VERSION "HNNBNNNYNNNNNNNNNNNNNNNNNNNNNNNNNNNNNNNNNN/4/%%%/4/'%**4NNN///"

NS_ :

BS_:

BU_: Airbag Allrad_Haldex BAP_Tester DCC_Gen3 EBKV_MQBW ESC_MQBW Gateway_Max Lenkhilfe_REPS

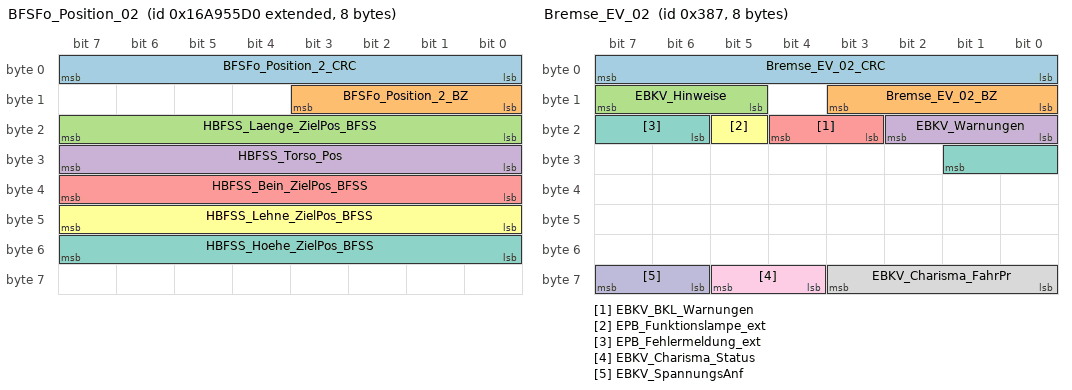
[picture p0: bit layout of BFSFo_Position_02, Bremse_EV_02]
BO_ 2527679952 BFSFo_Position_02: 8 Gateway_Max
 SG_ BFSFo_Position_2_CRC : 0|8@1+ (1,0) [0|255] ""  Airbag
 SG_ BFSFo_Position_2_BZ : 8|4@1+ (1,0) [0|15] ""  Airbag
 SG_ HBFSS_Laenge_ZielPos_BFSS : 16|8@1+ (1,0) [0|255] ""  Vector__XXX
 SG_ HBFSS_Torso_Pos : 24|8@1+ (1,0) [0|255] ""  Airbag
 SG_ HBFSS_Bein_ZielPos_BFSS : 32|8@1+ (1,0) [0|255] ""  Vector__XXX
 SG_ HBFSS_Lehne_ZielPos_BFSS : 40|8@1+ (1,0) [0|255] ""  Vector__XXX
 SG_ HBFSS_Hoehe_ZielPos_BFSS : 48|8@1+ (1,0) [0|255] ""  Vector__XXX

BO_ 870 Blinkmodi_02: 8 Gateway_Max
 SG_ Blinkmodi_02_CRC : 0|8@1+ (1,0) [0|255] ""  Vector__XXX
 SG_ Blinkmodi_02_BZ : 8|4@1+ (1,0) [0|15] ""  Vector__XXX
 SG_ BM_ZV_auf : 12|1@1+ (1.0,0.0) [0.0|1] ""  Vector__XXX
 SG_ BM_ZV_zu : 13|1@1+ (1.0,0.0) [0.0|1] ""  Vector__XXX
 SG_ BM_DWA_ein : 14|1@1+ (1.0,0.0) [0.0|1] ""  Vector__XXX
 SG_ BM_DWA_Alarm : 15|1@1+ (1.0,0.0) [0.0|1] ""  Vector__XXX
 SG_ BM_Crash : 16|1@1+ (1.0,0.0) [0.0|1] ""  Vector__XXX
 SG_ BM_Panik : 17|1@1+ (1.0,0.0) [0.0|1] ""  Vector__XXX
 SG_ BM_Not_Bremsung : 18|1@1+ (1.0,0.0) [0.0|1] ""  Vector__XXX
 SG_ BM_GDO : 19|1@1+ (1.0,0.0) [0.0|1] ""  Vector__XXX
 SG_ BM_Warnblinken : 20|1@1+ (1.0,0.0) [0.0|1] ""  Airbag,ESC_MQBW
 SG_ BM_Taxi_Notalarm : 21|1@1+ (1.0,0.0) [0.0|1] ""  Vector__XXX
 SG_ BM_Telematik : 22|1@1+ (1.0,0.0) [0.0|1] ""  Vector__XXX
 SG_ BM_links : 23|1@1+ (1.0,0.0) [0.0|1] ""  Airbag
 SG_ BM_rechts : 24|1@1+ (1.0,0.0) [0.0|1] ""  Airbag
 SG_ Blinken_li_Fzg_Takt : 25|1@1+ (1.0,0.0) [0.0|1] ""  Vector__XXX
 SG_ Blinken_re_Fzg_Takt : 26|1@1+ (1.0,0.0) [0.0|1] ""  Vector__XXX
 SG_ Blinken_li_Kombi_Takt : 27|1@1+ (1.0,0.0) [0.0|1] ""  Vector__XXX
 SG_ Blinken_re_Kombi_Takt : 28|1@1+ (1.0,0.0) [0.0|1] ""  Vector__XXX
 SG_ BM_NBA_n_codiert_n_aktiv : 29|1@1+ (1.0,0.0) [0.0|1] ""  Vector__XXX
 SG_ BM_NBA_Status : 30|2@1+ (1.0,0.0) [0.0|3] ""  Vector__XXX
 SG_ BM_WBT_Beleuchtung : 32|1@1+ (1.0,0.0) [0.0|1] ""  Vector__XXX
 SG_ BM_HD_Oeffnung_angelernt : 33|1@1+ (1.0,0.0) [0.0|1] ""  Vector__XXX
 SG_ BM_Autobahn : 34|1@1+ (1.0,0.0) [0.0|1] ""  Vector__XXX
 SG_ BM_Rollenmodus_Blinken : 35|1@1+ (1.0,0.0) [0.0|1] ""  Vector__XXX
 SG_ BM_Recas : 36|1@1+ (1.0,0.0) [0.0|1] ""  Vector__XXX
 SG_ BM_Wischblinken : 37|1@1+ (1.0,0.0) [0.0|1] ""  Vector__XXX
 SG_ BM_Telematik_Abbruchgrund : 38|6@1+ (1.0,0.0) [0.0|63] ""  Vector__XXX
 SG_ BM_PiloPa : 44|1@1+ (1.0,0.0) [0.0|1] ""  Vector__XXX
 SG_ SAL_TA_Blinken_Status : 45|3@1+ (1.0,0.0) [0.0|7] ""  Vector__XXX
 SG_ BM_WBA_Warnblinken : 48|1@1+ (1.0,0.0) [0.0|1] ""  Vector__XXX
 SG_ SAL_RHP_Blinken_Status : 49|3@1+ (1.0,0.0) [0.0|7] ""  Vector__XXX
 SG_ SAL_RHP_Warnblinken : 52|1@1+ (1.0,0.0) [0.0|1] ""  Vector__XXX

BO_ 903 Bremse_EV_02: 8 EBKV_MQBW
 SG_ Bremse_EV_02_CRC : 0|8@1+ (1,0) [0|255] ""  Vector__XXX
 SG_ Bremse_EV_02_BZ : 8|4@1+ (1,0) [0|15] ""  Vector__XXX
 SG_ EBKV_Hinweise : 13|3@1+ (1.0,0.0) [0.0|7] ""  Vector__XXX
 SG_ EBKV_Warnungen : 16|3@1+ (1.0,0.0) [0.0|7] ""  Vector__XXX
 SG_ EBKV_BKL_Warnungen : 19|2@1+ (1.0,0.0) [0.0|3] ""  Vector__XXX
 SG_ EPB_Funktionslampe_ext : 21|1@1+ (1.0,0.0) [0.0|1] ""  Vector__XXX
 SG_ EPB_Fehlermeldung_ext : 22|4@1+ (1.0,0.0) [0.0|15] ""  Vector__XXX
 SG_ EBKV_Charisma_FahrPr : 56|4@1+ (1.0,0.0) [0.0|15] ""  Vector__XXX
 SG_ EBKV_Charisma_Status : 60|2@1+ (1.0,0.0) [0.0|3] ""  Vector__XXX
 SG_ EBKV_SpannungsAnf : 62|2@1+ (1.0,0.0) [0.0|3] ""  Gateway_Max

BO_ 2281471488 CCP_Allrad_CRO_01: 8 Vector__XXX
 SG_ CCP_Allrad_CRO_01_Data : 0|64@1+ (1.0,0.0) [0.0|18446744073709551615] ""  Allrad_Haldex

BO_ 2281471489 CCP_Allrad_DTO_01: 8 Allrad_Haldex
 SG_ CCP_Allrad_DTO_01_Data : 0|64@1+ (1.0,0.0) [0.0|18446744073709551615] ""  Vector__XXX

BO_ 2463978646 Charisma_11: 24 Gateway_Max
 SG_ CHA_Ziel_FahrPr_AGA : 0|4@1+ (1.0,0.0) [0.0|15] ""  Vector__XXX
 SG_ CHA_Ziel_FahrPr_ESP : 4|4@1+ (1.0,0.0) [0.0|15] ""  ESC_MQBW
 SG_ CHA_Ziel_FahrPr_Freilauf : 8|4@1+ (1.0,0.0) [0.0|15] ""  Vector__XXX
 SG_ CHA_Fahrer_Umschaltung : 14|1@1+ (1.0,0.0) [0.0|1] ""  Airbag,ESC_MQBW
 SG_ CHA_Fahrer_Umschaltung_BMA : 15|1@1+ (1.0,0.0) [0.0|1] ""  Vector__XXX
 SG_ CHA_Ziel_FahrPr_MO : 16|4@1+ (1.0,0.0) [0.0|15] ""  Vector__XXX
 SG_ CHA_Ziel_FahrPr_GE : 20|4@1+ (1.0,0.0) [0.0|15] ""  Vector__XXX
 SG_ CHA_Ziel_FahrPr_ALR : 24|4@1+ (1.0,0.0) [0.0|15] ""  Allrad_Haldex
 SG_ CHA_Ziel_FahrPr_MO_BZS : 28|4@1+ (1.0,0.0) [0.0|15] ""  Vector__XXX
 SG_ CHA_Ziel_FahrPr_DR : 32|4@1+ (1.0,0.0) [0.0|15] ""  DCC_Gen3,ESC_MQBW
 SG_ CHA_Ziel_FahrPr_VAQ : 36|4@1+ (1.0,0.0) [0.0|15] ""  ESC_MQBW
 SG_ CHA_Ziel_FahrPr_AFS : 40|4@1+ (1.0,0.0) [0.0|15] ""  Vector__XXX
 SG_ CHA_Ziel_FahrPr_PreCrash : 44|4@1+ (1.0,0.0) [0.0|15] ""  Airbag
 SG_ CHA_Ziel_FahrPr_EPS : 48|4@1+ (1.0,0.0) [0.0|15] ""  Lenkhilfe_REPS
 SG_ CHA_Ziel_FahrPr_ACC : 52|4@1+ (1.0,0.0) [0.0|15] ""  Vector__XXX
 SG_ CHA_Ziel_FahrPr_SAK : 56|4@1+ (1.0,0.0) [0.0|15] ""  Vector__XXX
 SG_ CHA_Ziel_FahrPr_MO_StSt : 60|4@1+ (1.0,0.0) [0.0|15] ""  Vector__XXX
 SG_ CHA_Ziel_FahrPr_EBKV : 64|4@1+ (1.0,0.0) [0.0|15] ""  EBKV_MQBW
 SG_ CHA_Ziel_FahrPr_IL : 68|4@1+ (1.0,0.0) [0.0|15] ""  Vector__XXX
 SG_ CHA_Current_Mode : 72|4@1+ (1.0,0.0) [0.0|15] ""  Vector__XXX
 SG_ CHA_Ziel_FahrPr_QS : 80|4@1+ (1.0,0.0) [0.0|15] ""  Vector__XXX
 SG_ CHA_Ziel_FahrPr_SCU : 84|4@1+ (1.0,0.0) [0.0|15] ""  Vector__XXX
 SG_ CHA_Ziel_FahrPr_HAL : 88|4@1+ (1.0,0.0) [0.0|15] ""  Vector__XXX
 SG_ CHA_Ziel_FahrPr_NR : 92|4@1+ (1.0,0.0) [0.0|15] ""  Vector__XXX
 SG_ CHA_Ziel_FahrPr_AV : 96|4@1+ (1.0,0.0) [0.0|15] ""  Vector__XXX
 SG_ CHA_Ziel_FahrPr_MXB : 100|4@1+ (1.0,0.0) [0.0|15] ""  Vector__XXX
 SG_ CHA_Ziel_FahrPr_AFR : 104|4@1+ (1.0,0.0) [0.0|15] ""  Vector__XXX
 SG_ CHA_Ziel_FahrPr_HDC : 108|4@1+ (1.0,0.0) [0.0|15] ""  ESC_MQBW
 SG_ CHA_Ziel_FahrPr_EAR : 112|4@1+ (1.0,0.0) [0.0|15] ""  Vector__XXX
 SG_ CHA_Ziel_FahrPr_AEB : 116|4@1+ (1.0,0.0) [0.0|15] ""  Vector__XXX
 SG_ CHA_Ziel_FahrPr_FCWO : 120|4@1+ (1.0,0.0) [0.0|15] ""  Vector__XXX
 SG_ CHA_Ziel_FahrPr_FCWP : 124|4@1+ (1.0,0.0) [0.0|15] ""  Vector__XXX
 SG_ CHA_Ziel_FahrPr_eSound : 136|4@1+ (1.0,0.0) [0.0|15] ""  Vector__XXX
 SG_ CHA_Ziel_FahrPr_RHP : 140|4@1+ (1.0,0.0) [0.0|15] ""  Vector__XXX
 SG_ CHA_Ziel_FahrPr_ToS_laengs : 144|4@1+ (1.0,0.0) [0.0|15] ""  Vector__XXX
 SG_ CHA_Ziel_FahrPr_ToS_quer : 148|4@1+ (1.0,0.0) [0.0|15] ""  Vector__XXX
 SG_ CHA_Ziel_FahrPr_mFDR : 152|4@1+ (1.0,0.0) [0.0|15] ""  ESC_MQBW
 SG_ CHA_Ziel_FahrPr_Reku_ZwGas : 156|4@1+ (1.0,0.0) [0.0|15] ""  Vector__XXX
 SG_ CHA_Ziel_FahrPr_MO_Freilauf : 160|4@1+ (1.0,0.0) [0.0|15] ""  Vector__XXX
 SG_ CHA_Ziel_FahrPr_BMS : 164|4@1+ (1.0,0.0) [0.0|15] ""  Vector__XXX
 SG_ CHA_Ziel_FahrPr_PDC : 172|4@1+ (1.0,0.0) [0.0|15] ""  Vector__XXX
 SG_ CHA_Ziel_FahrPr_HHC : 176|4@1+ (1.0,0.0) [0.0|15] ""  ESC_MQBW
 SG_ CHA_Ziel_FahrPr_EDS : 180|4@1+ (1.0,0.0) [0.0|15] ""  ESC_MQBW
 SG_ CHA_Ziel_FahrPr_PACC : 184|4@1+ (1.0,0.0) [0.0|15] ""  Vector__XXX
 SG_ CHA_Ziel_FahrPr_AGK : 188|4@1+ (1.0,0.0) [0.0|15] ""  Vector__XXX

BO_ 918 Daempfer_01: 8 DCC_Gen3
 SG_ DR_Gelbe_Warnlampe : 18|2@1+ (1.0,0.0) [0.0|3] ""  Gateway_Max

BO_ 514 Daempfer_03: 32 DCC_Gen3
 SG_ DR_Aufbaubeschleunigung_HR : 12|10@1+ (0.0327,-15.696) [-15.6960|15.6960] "Unit_MeterPerSeconSquar"  Gateway_Max
 SG_ DR_Aufbaubeschleunigung_VR : 22|10@1+ (0.0327,-15.696) [-15.6960|15.6960] "Unit_MeterPerSeconSquar"  Gateway_Max
 SG_ DR_Aufbaubeschleunigung_VL : 32|10@1+ (0.0327,-15.696) [-15.6960|15.6960] "Unit_MeterPerSeconSquar"  Gateway_Max
 SG_ DR_Aufbaubeschleunigung_HL : 42|10@1+ (0.0327,-15.696) [-15.6960|15.6960] "Unit_MeterPerSeconSquar"  Gateway_Max
 SG_ DR_Funktionsstatus : 52|2@1+ (1.0,0.0) [0.0|3] ""  ESC_MQBW,Gateway_Max
 SG_ DR_Drehwinkelsensortausch_VL : 72|2@1+ (1,0) [1|3] ""  Gateway_Max
 SG_ DR_Drehwinkelsensortausch_VR : 74|2@1+ (1,0) [1|3] ""  Gateway_Max
 SG_ DR_Drehwinkelsensortausch_HL : 76|2@1+ (1,0) [1|3] ""  Gateway_Max
 SG_ DR_Drehwinkelsensortausch_HR : 78|2@1+ (1,0) [1|3] ""  Gateway_Max
 SG_ DR_Drehwinkel_VL : 80|12@1+ (0.088,0) [0.000|359.920] ""  ESC_MQBW,Gateway_Max
 SG_ DR_Drehwinkel_VR : 92|12@1+ (0.088,0) [0.000|359.920] ""  ESC_MQBW,Gateway_Max
 SG_ DR_Drehwinkel_HL : 104|12@1+ (0.088,0) [0.000|359.920] ""  ESC_MQBW,Gateway_Max
 SG_ DR_Drehwinkel_HR : 116|12@1+ (0.088,0) [0.000|359.920] ""  ESC_MQBW,Gateway_Max
 SG_ DR_Daempferweg_VL : 128|12@1+ (0.1,-200) [-200.0|209.1] "Unit_MilliMeter"  ESC_MQBW,Gateway_Max
 SG_ DR_Daempferweg_VR : 140|12@1+ (0.1,-200) [-200.0|209.1] "Unit_MilliMeter"  ESC_MQBW,Gateway_Max
 SG_ DR_Daempferweg_HL : 152|12@1+ (0.1,-200) [-200.0|209.1] "Unit_MilliMeter"  ESC_MQBW,Gateway_Max
 SG_ DR_Daempferweg_HR : 164|12@1+ (0.1,-200) [-200.0|209.1] "Unit_MilliMeter"  ESC_MQBW,Gateway_Max

BO_ 2463978758 Daempfer_05: 16 DCC_Gen3
 SG_ DR_DCCMonitor_I_Add : 48|8@1+ (0.5,0) [0.0|100.0] "Unit_PerCent"  Gateway_Max
 SG_ DR_DCCMonitor_I_SZ_Add : 56|8@1+ (0.5,0) [0.0|100.0] "Unit_PerCent"  Gateway_Max
 SG_ DR_DCCMonitor_I_HL : 64|8@1+ (0.5,0) [0.0|100.0] "Unit_PerCent"  Gateway_Max
 SG_ DR_DCCMonitor_I_SZ_HL : 72|8@1+ (0.5,0) [0.0|100.0] "Unit_PerCent"  Gateway_Max
 SG_ DR_DCCMonitor_I_HR : 80|8@1+ (0.5,0) [0.0|100.0] "Unit_PerCent"  Gateway_Max
 SG_ DR_DCCMonitor_I_SZ_HR : 88|8@1+ (0.5,0) [0.0|100.0] "Unit_PerCent"  Gateway_Max
 SG_ DR_DCCMonitor_I_VL : 96|8@1+ (0.5,0) [0.0|100.0] "Unit_PerCent"  Gateway_Max
 SG_ DR_DCCMonitor_I_SZ_VL : 104|8@1+ (0.5,0) [0.0|100.0] "Unit_PerCent"  Gateway_Max
 SG_ DR_DCCMonitor_I_VR : 112|8@1+ (0.5,0) [0.0|100.0] "Unit_PerCent"  Gateway_Max
 SG_ DR_DCCMonitor_I_SZ_VR : 120|8@1+ (0.5,0) [0.0|100.0] "Unit_PerCent"  Gateway_Max

BO_ 2617027088 DEV_Airbag_ASM_01: 8 Airbag
 SG_ DEV_Airbag_ASM_01_Data : 0|64@1+ (1.0,0.0) [0.0|18446744073709551615] ""  Vector__XXX

BO_ 2617027072 DEV_Airbag_Resp_00: 64 Airbag
 SG_ DEV_Airbag_Resp_00_Data_FD : 0|512@1+ (1.0,0.0) [0.0|13407807929942597099574024998205846127479365820592393377723561443721764030073546976801874298166903427690031858186486050853753882811946569946433649006084095] ""  Vector__XXX

BO_ 2617027073 DEV_Airbag_Resp_01: 64 Airbag
 SG_ DEV_Airbag_Resp_01_Data_FD : 0|512@1+ (1.0,0.0) [0.0|13407807929942597099574024998205846127479365820592393377723561443721764030073546976801874298166903427690031858186486050853753882811946569946433649006084095] ""  Vector__XXX

BO_ 2617014784 DEV_Allrad_Req_00: 8 Vector__XXX
 SG_ DEV_Allrad_Req_00_Data : 0|64@1+ (1.0,0.0) [0.0|18446744073709551615] ""  Allrad_Haldex

BO_ 2617014785 DEV_Allrad_Resp_01: 8 Allrad_Haldex
 SG_ DEV_Allrad_Resp_01_Data : 0|64@1+ (1.0,0.0) [0.0|18446744073709551615] ""  Vector__XXX

BO_ 2617014786 DEV_Allrad_Resp_02: 8 Allrad_Haldex
 SG_ DEV_Allrad_Resp_02_Data : 0|64@1+ (1.0,0.0) [0.0|18446744073709551615] ""  Vector__XXX

BO_ 2617014787 DEV_Allrad_Resp_03: 8 Allrad_Haldex
 SG_ DEV_Allrad_Resp_03_Data : 0|64@1+ (1.0,0.0) [0.0|18446744073709551615] ""  Vector__XXX

BO_ 2617014788 DEV_Allrad_Resp_04: 8 Allrad_Haldex
 SG_ DEV_Allrad_Resp_04_Data : 0|64@1+ (1.0,0.0) [0.0|18446744073709551615] ""  Vector__XXX

BO_ 2617014789 DEV_Allrad_Resp_05: 8 Allrad_Haldex
 SG_ DEV_Allrad_Resp_05_Data : 0|64@1+ (1.0,0.0) [0.0|18446744073709551615] ""  Vector__XXX

BO_ 2617014790 DEV_Allrad_Resp_06: 8 Allrad_Haldex
 SG_ DEV_Allrad_Resp_06_Data : 0|64@1+ (1.0,0.0) [0.0|18446744073709551615] ""  Vector__XXX

BO_ 2617014791 DEV_Allrad_Resp_07: 8 Allrad_Haldex
 SG_ DEV_Allrad_Resp_07_Data : 0|64@1+ (1.0,0.0) [0.0|18446744073709551615] ""  Vector__XXX

BO_ 2617217549 DEV_Daempfer_Req_13: 32 Vector__XXX
 SG_ DEV_Daempfer_Req_13_Data : 0|64@1+ (1.0,0.0) [0.0|18446744073709551615] ""  DCC_Gen3

BO_ 2617217550 DEV_Daempfer_Req_14: 32 Vector__XXX
 SG_ DEV_Daempfer_Req_14_Data : 0|64@1+ (1.0,0.0) [0.0|18446744073709551615] ""  DCC_Gen3

BO_ 2617217551 DEV_Daempfer_Resp_15: 32 DCC_Gen3
 SG_ DEV_Daempfer_Resp_15_Data : 0|64@1+ (1.0,0.0) [0.0|18446744073709551615] ""  Vector__XXX

BO_ 2617217552 DEV_Daempfer_Resp_16: 48 DCC_Gen3
 SG_ DEV_Daempfer_Resp_16_Data : 0|64@1+ (1.0,0.0) [0.0|18446744073709551615] ""  Vector__XXX

BO_ 2617217553 DEV_Daempfer_Resp_17: 32 DCC_Gen3
 SG_ DEV_Daempfer_Resp_17_Data : 0|64@1+ (1.0,0.0) [0.0|18446744073709551615] ""  Vector__XXX

BO_ 2617104905 DEV_EBKV_Resp_00: 64 EBKV_MQBW
 SG_ DEV_EBKV_Resp_00_Data : 0|64@1+ (1.0,0.0) [0.0|18446744073709551615] ""  Vector__XXX

BO_ 2617104906 DEV_EBKV_Resp_01: 32 EBKV_MQBW
 SG_ DEV_EBKV_Resp_01_Data : 0|64@1+ (1.0,0.0) [0.0|18446744073709551615] ""  Vector__XXX

BO_ 2617104907 DEV_EBKV_Resp_03: 20 EBKV_MQBW
 SG_ DEV_EBKV_Resp_03_Data : 0|64@1+ (1.0,0.0) [0.0|18446744073709551615] ""  Vector__XXX

BO_ 2617104908 DEV_EBKV_Resp_04: 24 EBKV_MQBW
 SG_ DEV_EBKV_Resp_04_Data : 0|64@1+ (1.0,0.0) [0.0|18446744073709551615] ""  Vector__XXX

BO_ 2617104897 DEV_EBKV_Resp_05: 64 EBKV_MQBW
 SG_ DEV_EBKV_Resp_05_Data : 0|64@1+ (1.0,0.0) [0.0|18446744073709551615] ""  Vector__XXX

BO_ 2617104898 DEV_EBKV_Resp_06: 64 EBKV_MQBW
 SG_ DEV_EBKV_Resp_06_Data : 0|64@1+ (1.0,0.0) [0.0|18446744073709551615] ""  Vector__XXX

BO_ 2617104899 DEV_EBKV_Resp_07: 64 EBKV_MQBW
 SG_ DEV_EBKV_Resp_07_Data : 0|64@1+ (1.0,0.0) [0.0|18446744073709551615] ""  Vector__XXX

BO_ 2617104903 DEV_EBKV_Resp_08: 64 EBKV_MQBW
 SG_ DEV_EBKV_Resp_08_Data : 0|64@1+ (1.0,0.0) [0.0|18446744073709551615] ""  Vector__XXX

BO_ 2617104904 DEV_EBKV_Resp_09: 64 EBKV_MQBW
 SG_ DEV_EBKV_Resp_09_Data : 0|64@1+ (1.0,0.0) [0.0|18446744073709551615] ""  Vector__XXX

BO_ 2617104909 DEV_EBKV_Resp_10: 64 EBKV_MQBW
 SG_ DEV_EBKV_Resp_10_Data : 0|64@1+ (1.0,0.0) [0.0|18446744073709551615] ""  Vector__XXX

BO_ 2617152033 DEV_EPB_Resp_01: 48 ESC_MQBW
 SG_ DEV_EPB_Resp_01_Data : 0|64@1+ (1.0,0.0) [0.0|18446744073709551615] ""  Vector__XXX

BO_ 2617152034 DEV_EPB_Resp_02: 48 ESC_MQBW
 SG_ DEV_EPB_Resp_02_Data : 0|64@1+ (1.0,0.0) [0.0|18446744073709551615] ""  Vector__XXX

BO_ 2617023022 DEV_ESC_Req_01: 7 Vector__XXX
 SG_ DEV_ESC_Req_01_Data : 0|56@1+ (1.0,0.0) [0.0|72057594037927935] ""  ESC_MQBW

BO_ 2617023023 DEV_ESC_Req_02: 7 Vector__XXX
 SG_ DEV_ESC_Req_02_Data : 0|56@1+ (1.0,0.0) [0.0|72057594037927935] ""  ESC_MQBW

BO_ 2617023021 DEV_ESC_Req_03: 8 Vector__XXX
 SG_ DEV_ESC_Req_03_Data : 0|64@1+ (1.0,0.0) [0.0|18446744073709551615] ""  ESC_MQBW

BO_ 2617023008 DEV_ESC_Resp_00: 64 ESC_MQBW
 SG_ DEV_ESC_Resp_00_Data : 0|64@1+ (1.0,0.0) [0.0|18446744073709551615] ""  Vector__XXX

BO_ 2617023009 DEV_ESC_Resp_01: 64 ESC_MQBW
 SG_ DEV_ESC_Resp_01_Data : 0|64@1+ (1.0,0.0) [0.0|18446744073709551615] ""  Vector__XXX

BO_ 2617023011 DEV_ESC_Resp_03: 20 ESC_MQBW
 SG_ DEV_ESC_Resp_03_Data : 0|64@1+ (1.0,0.0) [0.0|18446744073709551615] ""  Vector__XXX

BO_ 2617023012 DEV_ESC_Resp_04: 24 ESC_MQBW
 SG_ DEV_ESC_Resp_04_Data : 0|64@1+ (1.0,0.0) [0.0|18446744073709551615] ""  Vector__XXX

BO_ 2617023018 DEV_ESC_Resp_05: 48 ESC_MQBW
 SG_ DEV_ESC_Resp_05_Data : 0|64@1+ (1.0,0.0) [0.0|18446744073709551615] ""  Vector__XXX

BO_ 2617023019 DEV_ESC_Resp_06: 8 ESC_MQBW
 SG_ DEV_ESC_Resp_06_Data : 0|64@1+ (1.0,0.0) [0.0|18446744073709551615] ""  Vector__XXX

BO_ 2617023014 DEV_ESC_Resp_07: 64 ESC_MQBW
 SG_ DEV_ESC_Resp_07_Data : 0|64@1+ (1.0,0.0) [0.0|18446744073709551615] ""  Vector__XXX

BO_ 2617023015 DEV_ESC_Resp_08: 64 ESC_MQBW
 SG_ DEV_ESC_Resp_08_Data : 0|64@1+ (1.0,0.0) [0.0|18446744073709551615] ""  Vector__XXX

BO_ 2617023016 DEV_ESC_Resp_09: 64 ESC_MQBW
 SG_ DEV_ESC_Resp_09_Data : 0|64@1+ (1.0,0.0) [0.0|18446744073709551615] ""  Vector__XXX

BO_ 2617023013 DEV_ESC_Resp_10: 64 ESC_MQBW
 SG_ DEV_ESC_Resp_10_Data : 0|64@1+ (1.0,0.0) [0.0|18446744073709551615] ""  Vector__XXX

BO_ 2617023017 DEV_ESC_Resp_11: 64 ESC_MQBW
 SG_ DEV_ESC_Resp_11_Data : 0|64@1+ (1.0,0.0) [0.0|18446744073709551615] ""  Vector__XXX

BO_ 2617023024 DEV_ESC_Resp_12: 20 ESC_MQBW
 SG_ DEV_ESC_Resp_12_Data : 0|64@1+ (1.0,0.0) [0.0|18446744073709551615] ""  Vector__XXX

BO_ 2617023026 DEV_ESC_Resp_13: 64 ESC_MQBW
 SG_ DEV_ESC_Resp_13_Data : 0|64@1+ (1.0,0.0) [0.0|18446744073709551615] ""  Vector__XXX

BO_ 2617020928 DEV_Lenkhilfe_Resp_00: 8 Lenkhilfe_REPS
 SG_ DEV_Lenkhilfe_Resp_00_Data : 0|64@1+ (1.0,0.0) [0.0|18446744073709551615] ""  Vector__XXX

BO_ 2617020929 DEV_Lenkhilfe_Resp_01: 8 Lenkhilfe_REPS
 SG_ DEV_Lenkhilfe_Resp_01_Data : 0|64@1+ (1.0,0.0) [0.0|18446744073709551615] ""  Vector__XXX

BO_ 2617020930 DEV_Lenkhilfe_Resp_02: 8 Lenkhilfe_REPS
 SG_ DEV_Lenkhilfe_Resp_02_Data : 0|64@1+ (1.0,0.0) [0.0|18446744073709551615] ""  Vector__XXX

BO_ 2617020931 DEV_Lenkhilfe_Resp_03: 8 Lenkhilfe_REPS
 SG_ DEV_Lenkhilfe_Resp_03_Data : 0|64@1+ (1.0,0.0) [0.0|18446744073709551615] ""  Vector__XXX

BO_ 2617020932 DEV_Lenkhilfe_Resp_04: 8 Lenkhilfe_REPS
 SG_ DEV_Lenkhilfe_Resp_04_Data : 0|64@1+ (1.0,0.0) [0.0|18446744073709551615] ""  Vector__XXX

BO_ 2617020933 DEV_Lenkhilfe_Resp_05: 8 Lenkhilfe_REPS
 SG_ DEV_Lenkhilfe_Resp_05_Data : 0|64@1+ (1.0,0.0) [0.0|18446744073709551615] ""  Vector__XXX

BO_ 2617020934 DEV_Lenkhilfe_Resp_06: 8 Lenkhilfe_REPS
 SG_ DEV_Lenkhilfe_Resp_06_Data : 0|64@1+ (1.0,0.0) [0.0|18446744073709551615] ""  Vector__XXX

BO_ 2617020935 DEV_Lenkhilfe_Resp_07: 8 Lenkhilfe_REPS
 SG_ DEV_Lenkhilfe_Resp_07_Data : 0|64@1+ (1.0,0.0) [0.0|18446744073709551615] ""  Vector__XXX

BO_ 2617020936 DEV_Lenkhilfe_Resp_08: 8 Lenkhilfe_REPS
 SG_ DEV_Lenkhilfe_Resp_08_Data : 0|64@1+ (1.0,0.0) [0.0|18446744073709551615] ""  Vector__XXX

BO_ 2617020937 DEV_Lenkhilfe_Resp_09: 8 Lenkhilfe_REPS
 SG_ DEV_Lenkhilfe_Resp_09_Data : 0|64@1+ (1.0,0.0) [0.0|18446744073709551615] ""  Vector__XXX

BO_ 2617020938 DEV_Lenkhilfe_Resp_10: 8 Lenkhilfe_REPS
 SG_ DEV_Lenkhilfe_Resp_10_Data : 0|64@1+ (1.0,0.0) [0.0|18446744073709551615] ""  Vector__XXX

BO_ 2617020939 DEV_Lenkhilfe_Resp_11: 8 Lenkhilfe_REPS
 SG_ DEV_Lenkhilfe_Resp_11_Data : 0|64@1+ (1.0,0.0) [0.0|18446744073709551615] ""  Vector__XXX

BO_ 2617020940 DEV_Lenkhilfe_Resp_12: 8 Lenkhilfe_REPS
 SG_ DEV_Lenkhilfe_Resp_12_Data : 0|64@1+ (1.0,0.0) [0.0|18446744073709551615] ""  Vector__XXX

BO_ 2617020941 DEV_Lenkhilfe_Resp_13: 8 Lenkhilfe_REPS
 SG_ DEV_Lenkhilfe_Resp_13_Data : 0|64@1+ (1.0,0.0) [0.0|18446744073709551615] ""  Vector__XXX

BO_ 2617152080 DEV_PBC_Resp_01: 64 ESC_MQBW
 SG_ DEV_PBC_Resp_01_Data : 0|64@1+ (1.0,0.0) [0.0|18446744073709551615] ""  Vector__XXX

BO_ 2549891590 DIA_eCS_Req: 8 Gateway_Max
 SG_ DIA_eCS_Req_Data : 0|64@1+ (1.0,0.0) [0.0|18446744073709551615] ""  Vector__XXX

BO_ 2621456902 DIA_eCS_Req_FD: 64 Gateway_Max
 SG_ DIA_eCS_Req_FD_Data : 0|512@1+ (1.0,0.0) [0.0|13407807929942597099574024998205846127479365820592393377723561443721764030073546976801874298166903427690031858186486050853753882811946569946433649006084095] ""  Vector__XXX

BO_ 2550022662 DIA_eCS_Resp: 8 Vector__XXX
 SG_ DIA_eCS_Resp_Data : 0|64@1+ (1.0,0.0) [0.0|18446744073709551615] ""  Gateway_Max

BO_ 2621587974 DIA_eCS_Resp_FD: 64 Vector__XXX
 SG_ DIA_eCS_Resp_FD_Data : 0|512@1+ (1.0,0.0) [0.0|13407807929942597099574024998205846127479365820592393377723561443721764030073546976801874298166903427690031858186486050853753882811946569946433649006084095] ""  Gateway_Max

BO_ 2549880606 DIA_RGS_HL_Req: 8 Gateway_Max
 SG_ DIA_RGS_HL_Req_Data : 0|64@1+ (1.0,0.0) [0.0|18446744073709551615] ""  Vector__XXX

BO_ 2621445918 DIA_RGS_HL_Req_FD: 64 Gateway_Max
 SG_ DIA_RGS_HL_Req_FD_Data : 0|512@1+ (1.0,0.0) [0.0|13407807929942597099574024998205846127479365820592393377723561443721764030073546976801874298166903427690031858186486050853753882811946569946433649006084095] ""  Vector__XXX

BO_ 2550011678 DIA_RGS_HL_Resp: 8 Vector__XXX
 SG_ DIA_RGS_HL_Resp_Data : 0|64@1+ (1.0,0.0) [0.0|18446744073709551615] ""  Gateway_Max

BO_ 2621576990 DIA_RGS_HL_Resp_FD: 64 Vector__XXX
 SG_ DIA_RGS_HL_Resp_FD_Data : 0|512@1+ (1.0,0.0) [0.0|13407807929942597099574024998205846127479365820592393377723561443721764030073546976801874298166903427690031858186486050853753882811946569946433649006084095] ""  Gateway_Max

BO_ 2549880607 DIA_RGS_HR_Req: 8 Gateway_Max
 SG_ DIA_RGS_HR_Req_Data : 0|64@1+ (1.0,0.0) [0.0|18446744073709551615] ""  Vector__XXX

BO_ 2621445919 DIA_RGS_HR_Req_FD: 64 Gateway_Max
 SG_ DIA_RGS_HR_Req_FD_Data : 0|512@1+ (1.0,0.0) [0.0|13407807929942597099574024998205846127479365820592393377723561443721764030073546976801874298166903427690031858186486050853753882811946569946433649006084095] ""  Vector__XXX

BO_ 2550011679 DIA_RGS_HR_Resp: 8 Vector__XXX
 SG_ DIA_RGS_HR_Resp_Data : 0|64@1+ (1.0,0.0) [0.0|18446744073709551615] ""  Gateway_Max

BO_ 2621576991 DIA_RGS_HR_Resp_FD: 64 Vector__XXX
 SG_ DIA_RGS_HR_Resp_FD_Data : 0|512@1+ (1.0,0.0) [0.0|13407807929942597099574024998205846127479365820592393377723561443721764030073546976801874298166903427690031858186486050853753882811946569946433649006084095] ""  Gateway_Max

BO_ 2549880362 DIA_RGS_VL_Req: 8 Gateway_Max
 SG_ DIA_RGS_VL_Req_Data : 0|64@1+ (1.0,0.0) [0.0|18446744073709551615] ""  Vector__XXX

BO_ 2621445674 DIA_RGS_VL_Req_FD: 64 Gateway_Max
 SG_ DIA_RGS_VL_Req_FD_Data : 0|512@1+ (1.0,0.0) [0.0|13407807929942597099574024998205846127479365820592393377723561443721764030073546976801874298166903427690031858186486050853753882811946569946433649006084095] ""  Vector__XXX

BO_ 2550011434 DIA_RGS_VL_Resp: 8 Vector__XXX
 SG_ DIA_RGS_VL_Resp_Data : 0|64@1+ (1.0,0.0) [0.0|18446744073709551615] ""  Gateway_Max

BO_ 2621576746 DIA_RGS_VL_Resp_FD: 64 Vector__XXX
 SG_ DIA_RGS_VL_Resp_FD_Data : 0|512@1+ (1.0,0.0) [0.0|13407807929942597099574024998205846127479365820592393377723561443721764030073546976801874298166903427690031858186486050853753882811946569946433649006084095] ""  Gateway_Max

BO_ 2549880363 DIA_RGS_VR_Req: 8 Gateway_Max
 SG_ DIA_RGS_VR_Req_Data : 0|64@1+ (1.0,0.0) [0.0|18446744073709551615] ""  Vector__XXX

BO_ 2621445675 DIA_RGS_VR_Req_FD: 64 Gateway_Max
 SG_ DIA_RGS_VR_Req_FD_Data : 0|512@1+ (1.0,0.0) [0.0|13407807929942597099574024998205846127479365820592393377723561443721764030073546976801874298166903427690031858186486050853753882811946569946433649006084095] ""  Vector__XXX

BO_ 2550011435 DIA_RGS_VR_Resp: 8 Vector__XXX
 SG_ DIA_RGS_VR_Resp_Data : 0|64@1+ (1.0,0.0) [0.0|18446744073709551615] ""  Gateway_Max

BO_ 2621576747 DIA_RGS_VR_Resp_FD: 64 Vector__XXX
 SG_ DIA_RGS_VR_Resp_FD_Data : 0|512@1+ (1.0,0.0) [0.0|13407807929942597099574024998205846127479365820592393377723561443721764030073546976801874298166903427690031858186486050853753882811946569946433649006084095] ""  Gateway_Max

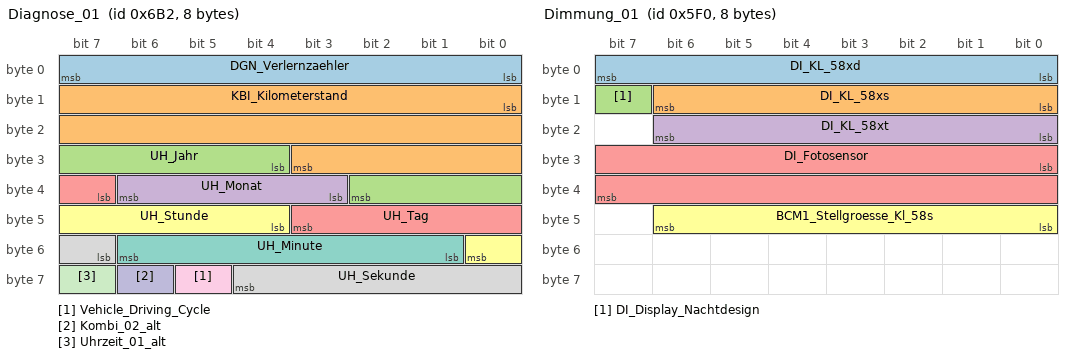
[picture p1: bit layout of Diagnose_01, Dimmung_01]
BO_ 1714 Diagnose_01: 8 Gateway_Max
 SG_ DGN_Verlernzaehler : 0|8@1+ (1,0) [0|254] ""  Airbag,Allrad_Haldex,EBKV_MQBW,ESC_MQBW
 SG_ KBI_Kilometerstand : 8|20@1+ (1,0) [0|1048573] "Unit_KiloMeter"  Airbag,Allrad_Haldex,DCC_Gen3,EBKV_MQBW,ESC_MQBW,Lenkhilfe_REPS
 SG_ UH_Jahr : 28|7@1+ (1,2000) [2000|2127] "Unit_Year"  Airbag,Allrad_Haldex,DCC_Gen3,EBKV_MQBW,ESC_MQBW,Lenkhilfe_REPS
 SG_ UH_Monat : 35|4@1+ (1,0) [1|12] "Unit_Month"  Airbag,Allrad_Haldex,DCC_Gen3,EBKV_MQBW,ESC_MQBW,Lenkhilfe_REPS
 SG_ UH_Tag : 39|5@1+ (1,0) [1|31] "Unit_Day"  Airbag,Allrad_Haldex,DCC_Gen3,EBKV_MQBW,ESC_MQBW,Lenkhilfe_REPS
 SG_ UH_Stunde : 44|5@1+ (1,0) [0|23] "Unit_Hours"  Airbag,Allrad_Haldex,DCC_Gen3,EBKV_MQBW,ESC_MQBW,Lenkhilfe_REPS
 SG_ UH_Minute : 49|6@1+ (1,0) [0|59] "Unit_Minut"  Airbag,Allrad_Haldex,DCC_Gen3,EBKV_MQBW,ESC_MQBW,Lenkhilfe_REPS
 SG_ UH_Sekunde : 55|6@1+ (1,0) [0|59] "Unit_Secon"  Airbag,Allrad_Haldex,DCC_Gen3,EBKV_MQBW,ESC_MQBW,Lenkhilfe_REPS
 SG_ Vehicle_Driving_Cycle : 61|1@1+ (1.0,0.0) [0.0|1] ""  Airbag,Lenkhilfe_REPS
 SG_ Kombi_02_alt : 62|1@1+ (1.0,0.0) [0.0|1] ""  Airbag
 SG_ Uhrzeit_01_alt : 63|1@1+ (1.0,0.0) [0.0|1] ""  Airbag

BO_ 1520 Dimmung_01: 8 Gateway_Max
 SG_ DI_KL_58xd : 0|8@1+ (1,0) [0|253] ""  Airbag,ESC_MQBW
 SG_ DI_KL_58xs : 8|7@1+ (1,0) [0|100] "Unit_PerCent"  Airbag
 SG_ DI_Display_Nachtdesign : 15|1@1+ (1.0,0.0) [0.0|1] ""  Vector__XXX
 SG_ DI_KL_58xt : 16|7@1+ (1,0) [0|100] "Unit_PerCent"  Airbag
 SG_ DI_Fotosensor : 24|16@1+ (1,0) [0|65535] ""  Vector__XXX
 SG_ BCM1_Stellgroesse_Kl_58s : 40|7@1+ (1,0) [0|100] ""  Vector__XXX

BO_ 331 DSR_01: 24 ESC_MQBW
 SG_ DSR_QFK_AnfStat : 12|4@1+ (1.0,0.0) [0.0|15] ""  Lenkhilfe_REPS
 SG_ DSR_QFK_Spuerb : 16|8@1+ (0.4,0) [0.0|100.0] "Unit_PerCent"  Lenkhilfe_REPS
 SG_ DSR_QFK_KruemmSoll : 24|15@1+ (0.0000067,0) [0E-7|0.2195389] "Unit_MeterInver"  Lenkhilfe_REPS
 SG_ DSR_QFK_KruemmSoll_VZ : 39|1@1+ (1.0,0.0) [0.0|1] ""  Lenkhilfe_REPS
 SG_ DSR_QFK_Signal1 : 40|10@1+ (1,0) [0|1023] ""  Lenkhilfe_REPS
 SG_ DSR_QFK_Art1 : 50|3@1+ (1,0) [0|7] ""  Lenkhilfe_REPS
 SG_ DSR_QFK_Art2 : 53|3@1+ (1,0) [0|7] ""  Lenkhilfe_REPS
 SG_ DSR_QFK_Signal2 : 56|10@1+ (1,0) [0|1023] ""  Lenkhilfe_REPS
 SG_ DSR_01_Sendestatus : 66|1@1+ (1.0,0.0) [0.0|1] ""  Lenkhilfe_REPS
 SG_ DSR_QFK_KrSoll_VZ : 67|1@1+ (1.0,0.0) [0.0|1] ""  Lenkhilfe_REPS
 SG_ DSR_QFK_KrSoll : 72|16@1+ (0.0000067,0) [0E-7|0.4390778] "Unit_MeterInver"  Lenkhilfe_REPS
 SG_ SOK_DSR_01_Signatur : 144|48@1+ (1,0) [0|281474976710655] "Unit_None"  Vector__XXX

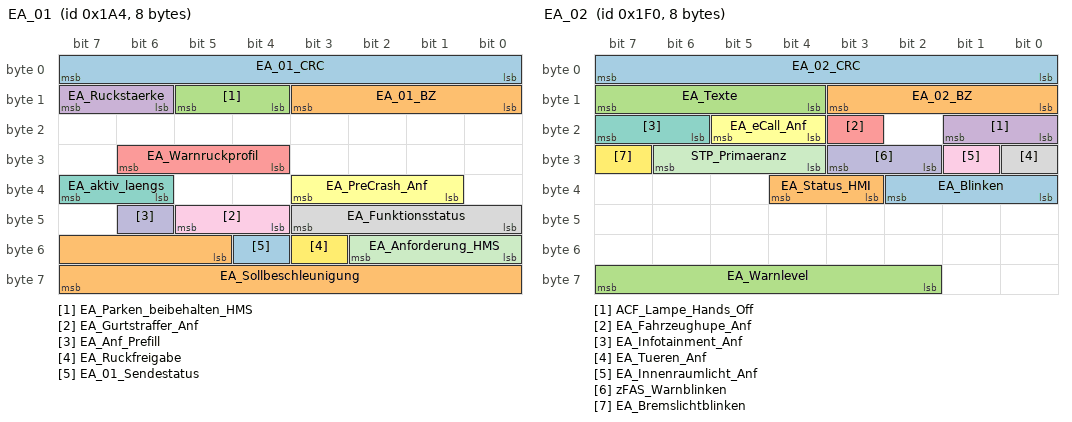
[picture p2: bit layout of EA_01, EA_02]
BO_ 420 EA_01: 8 Gateway_Max
 SG_ EA_01_CRC : 0|8@1+ (1,0) [0|255] ""  ESC_MQBW
 SG_ EA_01_BZ : 8|4@1+ (1,0) [0|15] ""  ESC_MQBW
 SG_ EA_Parken_beibehalten_HMS : 12|2@1+ (1.0,0.0) [0.0|3] ""  ESC_MQBW
 SG_ EA_Ruckstaerke : 14|2@1+ (1.0,0.0) [0.0|3] ""  ESC_MQBW
 SG_ EA_Warnruckprofil : 28|3@1+ (1.0,0.0) [0.0|7] ""  Vector__XXX
 SG_ EA_PreCrash_Anf : 33|3@1+ (1.0,0.0) [0.0|7] ""  Airbag
 SG_ EA_aktiv_laengs : 38|2@1+ (1.0,0.0) [0.0|3] ""  Vector__XXX
 SG_ EA_Funktionsstatus : 40|4@1+ (1.0,0.0) [0.0|15] ""  Airbag
 SG_ EA_Gurtstraffer_Anf : 44|2@1+ (1.0,0.0) [0.0|3] ""  Vector__XXX
 SG_ EA_Anf_Prefill : 46|1@1+ (1.0,0.0) [0.0|1] ""  ESC_MQBW
 SG_ EA_Anforderung_HMS : 48|3@1+ (1.0,0.0) [0.0|7] ""  ESC_MQBW
 SG_ EA_Ruckfreigabe : 51|1@1+ (1.0,0.0) [0.0|1] ""  ESC_MQBW
 SG_ EA_01_Sendestatus : 52|1@1+ (1.0,0.0) [0.0|1] ""  ESC_MQBW
 SG_ EA_Sollbeschleunigung : 53|11@1+ (0.005,-7.22) [-7.220|3.005] "Unit_MeterPerSeconSquar"  Vector__XXX

BO_ 496 EA_02: 8 Gateway_Max
 SG_ EA_02_CRC : 0|8@1+ (1,0) [0|255] ""  Vector__XXX
 SG_ EA_02_BZ : 8|4@1+ (1,0) [0|15] ""  Vector__XXX
 SG_ EA_Texte : 12|4@1+ (1.0,0.0) [0.0|15] ""  Airbag
 SG_ ACF_Lampe_Hands_Off : 16|2@1+ (1.0,0.0) [0.0|3] ""  Vector__XXX
 SG_ EA_Fahrzeughupe_Anf : 19|1@1+ (1.0,0.0) [0.0|1] ""  Vector__XXX
 SG_ EA_eCall_Anf : 20|2@1+ (1.0,0.0) [0.0|3] ""  Vector__XXX
 SG_ EA_Infotainment_Anf : 22|2@1+ (1.0,0.0) [0.0|3] ""  Vector__XXX
 SG_ EA_Tueren_Anf : 24|1@1+ (1.0,0.0) [0.0|1] ""  Vector__XXX
 SG_ EA_Innenraumlicht_Anf : 25|1@1+ (1.0,0.0) [0.0|1] ""  Vector__XXX
 SG_ zFAS_Warnblinken : 26|2@1+ (1.0,0.0) [0.0|3] ""  Vector__XXX
 SG_ STP_Primaeranz : 28|3@1+ (1.0,0.0) [0.0|7] ""  Vector__XXX
 SG_ EA_Bremslichtblinken : 31|1@1+ (1.0,0.0) [0.0|1] ""  Vector__XXX
 SG_ EA_Blinken : 32|3@1+ (1.0,0.0) [0.0|7] ""  Vector__XXX
 SG_ EA_Status_HMI : 35|2@1+ (1.0,0.0) [0.0|3] ""  Airbag
 SG_ EA_Warnlevel : 58|6@1+ (1.0,0.0) [0.0|63] ""  Vector__XXX

BO_ 236 EBKV_02: 12 EBKV_MQBW
 SG_ EBKV_02_CRC : 0|8@1+ (1,0) [0|255] ""  ESC_MQBW
 SG_ EBKV_02_BZ : 8|4@1+ (1,0) [0|15] ""  ESC_MQBW
 SG_ EBKV_extBr_Status : 12|3@1+ (1.0,0.0) [0.0|7] ""  ESC_MQBW
 SG_ EBKV_AktBr_aktiv : 15|1@1+ (1.0,0.0) [0.0|1] ""  ESC_MQBW
 SG_ EBKV_extBr_Druck_Max : 16|8@1+ (1,0) [0|250] "Unit_Bar"  ESC_MQBW
 SG_ EBKV_aktBr_Volumenstrom_Ist : 24|16@1+ (0.0078125,-252) [-252.0000000|252.0000000] "Unit_MilliLiterPerSec"  ESC_MQBW
 SG_ EBKV_Stangenweg : 40|12@1+ (0.015625,-5) [-5.000000|47.000000] "Unit_MilliMeter"  ESC_MQBW
 SG_ EBKV_Stangenweg_Fahrerwunsch : 52|12@1+ (0.02,-5) [-5.00|47.00] "Unit_MilliMeter"  ESC_MQBW
 SG_ SOK_EBKV_02_Signatur : 64|32@1+ (1,0) [0|4294967295] ""  Vector__XXX

BO_ 374 EBKV_03: 12 EBKV_MQBW
 SG_ EBKV_03_CRC : 0|8@1+ (1,0) [0|255] ""  ESC_MQBW,Gateway_Max
 SG_ EBKV_03_BZ : 8|4@1+ (1,0) [0|15] ""  ESC_MQBW,Gateway_Max
 SG_ EBKV_Activate_Fallback_ESP : 12|1@1+ (1.0,0.0) [0.0|1] ""  ESC_MQBW,Gateway_Max
 SG_ EBKV_Restdruckabsenkung : 13|3@1+ (1.0,0.0) [0.0|7] ""  ESC_MQBW,Gateway_Max
 SG_ EBKV_Status_02 : 16|4@1+ (1.0,0.0) [0.0|15] ""  ESC_MQBW,Gateway_Max
 SG_ EBKV_Diagnose : 20|1@1+ (1.0,0.0) [0.0|1] ""  ESC_MQBW,Gateway_Max
 SG_ EBKV_Fahrer_bremst : 21|1@1+ (1.0,0.0) [0.0|1] ""  ESC_MQBW,Gateway_Max
 SG_ EBKV_QBit_Fahrer_bremst : 22|1@1+ (1.0,0.0) [0.0|1] ""  ESC_MQBW,Gateway_Max
 SG_ EBKV_Fahrer_bremst_deutlich : 23|1@1+ (1.0,0.0) [0.0|1] ""  ESC_MQBW,Gateway_Max
 SG_ EBKV_OBD_Status : 24|1@1+ (1.0,0.0) [0.0|1] ""  ESC_MQBW,Gateway_Max
 SG_ EBKV_VMM_Sek_Notstopp_Status : 25|3@1+ (1.0,0.0) [0.0|7] ""  ESC_MQBW,Gateway_Max
 SG_ EBKV_Anforderung_HMS : 28|3@1+ (1.0,0.0) [0.0|7] ""  ESC_MQBW,Gateway_Max
 SG_ SBS_Anforderung_GE : 31|1@1+ (1.0,0.0) [0.0|1] ""  Gateway_Max
 SG_ EPB_Status_ext : 32|3@1+ (1.0,0.0) [0.0|7] ""  Gateway_Max
 SG_ EBKV_Textanzeigen : 35|2@1+ (1.0,0.0) [0.0|3] ""  Gateway_Max
 SG_ EBKV_Bremspedalweg : 40|8@1+ (0.4,-0.4) [0.0|101.2] "Unit_PerCent"  Airbag,ESC_MQBW,Gateway_Max
 SG_ EBKV_Kraftblending_Reserve : 48|8@1+ (0.5,0) [0.0|125.0] "Unit_Bar"  ESC_MQBW,Gateway_Max
 SG_ EBKV_Aussteuerdruck : 56|8@1+ (1,0) [0|250] "Unit_Bar"  ESC_MQBW,Gateway_Max
 SG_ SOK_EBKV_03_Signatur : 64|32@1+ (1,0) [0|4294967295] ""  Gateway_Max

BO_ 2589283963 EBKV_05: 16 EBKV_MQBW
 SG_ EBKV_OBD_Status_Auth : 12|1@1+ (1.0,0.0) [0.0|1] ""  Gateway_Max
 SG_ EBKV_Indc_StChk : 13|1@1+ (1.0,0.0) [0.0|1] ""  Gateway_Max
 SG_ EBKV_Indc_StFail : 14|1@1+ (1.0,0.0) [0.0|1] ""  Gateway_Max
 SG_ OBDProtocol_EBKV : 16|8@1+ (1.0,0.0) [0.0|255] ""  Gateway_Max
 SG_ SOK_EBKV_05_Signatur : 64|64@1+ (1,0) [1|18446744073709551615] "Unit_None"  Gateway_Max

BO_ 193 EM2_01: 32 Gateway_Max
 SG_ EM2_01_CRC : 0|8@1+ (1,0) [0|255] ""  Vector__XXX
 SG_ EM2_01_BZ : 8|4@1+ (1,0) [0|15] ""  Vector__XXX
 SG_ EM2_Istmodus : 12|4@1+ (1.0,0.0) [0.0|15] ""  Vector__XXX
 SG_ EM2_IstMoment : 16|12@1+ (0.5,-1023) [-1023.0|1023.5] "Unit_NewtoMeter"  Vector__XXX
 SG_ EM2_Moment_AR_Eingriff : 28|12@1+ (0.5,-1023) [-1023.0|1023.5] "Unit_NewtoMeter"  Vector__XXX
 SG_ EM2_IstDrehzahl : 40|15@1+ (1,-10000) [-10000|22765] "Unit_MinutInver"  Vector__XXX
 SG_ EM2_AR_aktiv : 55|1@1+ (1.0,0.0) [0.0|1] ""  Vector__XXX
 SG_ EM2_IstSpannung : 56|12@1+ (0.25,0) [0.00|1023.25] "Unit_Volt"  Vector__XXX
 SG_ EM2_Strom_HV : 68|12@1+ (0.5,-1023) [-1023.0|1023.5] "Unit_Amper"  Vector__XXX
 SG_ EM2_Max_Moment : 80|11@1+ (1,-1023) [-1023|1022] "Unit_NewtoMeter"  Vector__XXX
 SG_ EM2_ErwGrenzen_aktiv : 91|1@1+ (1.0,0.0) [0.0|1] ""  Vector__XXX
 SG_ EM2_Min_Moment : 92|11@1+ (1,-1023) [-1023|1022] "Unit_NewtoMeter"  Vector__XXX
 SG_ EM2_Fehler_ElAntriebAbschaltung : 103|1@1+ (1.0,0.0) [0.0|1] ""  Vector__XXX
 SG_ EM2_Max_Moment_Lim : 104|11@1+ (1,-1023) [-1023|1022] "Unit_NewtoMeter"  Vector__XXX
 SG_ EM2_Fehler_Notabschaltung : 115|1@1+ (1.0,0.0) [0.0|1] ""  Vector__XXX
 SG_ EM2_Min_Moment_Lim : 116|11@1+ (1,-1023) [-1023|1022] "Unit_NewtoMeter"  Vector__XXX
 SG_ EM2_Status_DrzEingriff : 127|2@1+ (1.0,0.0) [0.0|3] ""  Vector__XXX
 SG_ EM2_Mom_DrzEingriff : 129|11@1+ (1,-1023) [-1023|1022] "Unit_NewtoMeter"  Vector__XXX
 SG_ EM2_Raddrehzahl_links : 140|13@1+ (0.3,0) [0.0|2456.1] "Unit_MinutInver"  Vector__XXX
 SG_ EM2_Raddrehzahl_rechts : 153|13@1+ (0.3,0) [0.0|2456.1] "Unit_MinutInver"  Vector__XXX
 SG_ EM2_Max_Moment_Gesamt : 166|11@1+ (1,-1023) [-1023|1022] "Unit_NewtoMeter"  Vector__XXX
 SG_ EM2_Min_Moment_Gesamt : 177|11@1+ (1,-1023) [-1023|1022] "Unit_NewtoMeter"  Vector__XXX
 SG_ CluAxs_Avl : 188|2@1+ (1.0,0.0) [0.0|3] ""  Vector__XXX
 SG_ CluAxs_State : 190|2@1+ (1.0,0.0) [0.0|3] ""  Vector__XXX

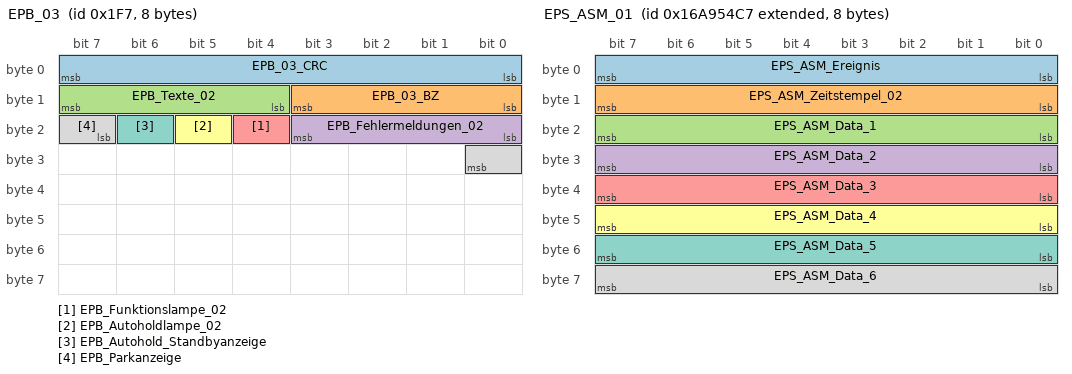
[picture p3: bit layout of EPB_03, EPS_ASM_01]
BO_ 503 EPB_03: 8 ESC_MQBW
 SG_ EPB_03_CRC : 0|8@1+ (1,0) [0|255] ""  Gateway_Max
 SG_ EPB_03_BZ : 8|4@1+ (1,0) [0|15] ""  Gateway_Max
 SG_ EPB_Texte_02 : 12|4@1+ (1.0,0.0) [0.0|15] ""  Gateway_Max
 SG_ EPB_Fehlermeldungen_02 : 16|4@1+ (1.0,0.0) [0.0|15] ""  Gateway_Max
 SG_ EPB_Funktionslampe_02 : 20|1@1+ (1.0,0.0) [0.0|1] ""  Gateway_Max
 SG_ EPB_Autoholdlampe_02 : 21|1@1+ (1.0,0.0) [0.0|1] ""  Gateway_Max
 SG_ EPB_Autohold_Standbyanzeige : 22|1@1+ (1.0,0.0) [0.0|1] ""  Gateway_Max
 SG_ EPB_Parkanzeige : 23|2@1+ (1.0,0.0) [0.0|3] ""  Gateway_Max

BO_ 2527679687 EPS_ASM_01: 8 Lenkhilfe_REPS
 SG_ EPS_ASM_Ereignis : 0|8@1+ (1,0) [1|254] "Unit_None"  Airbag
 SG_ EPS_ASM_Zeitstempel_02 : 8|8@1+ (0.04,0) [0.00|10.16] "Unit_Secon"  Airbag
 SG_ EPS_ASM_Data_1 : 16|8@1+ (1,0) [0|255] "Unit_None"  Airbag
 SG_ EPS_ASM_Data_2 : 24|8@1+ (1,0) [0|255] "Unit_None"  Airbag
 SG_ EPS_ASM_Data_3 : 32|8@1+ (1,0) [0|255] "Unit_None"  Airbag
 SG_ EPS_ASM_Data_4 : 40|8@1+ (1,0) [0|255] "Unit_None"  Airbag
 SG_ EPS_ASM_Data_5 : 48|8@1+ (1,0) [0|255] "Unit_None"  Airbag
 SG_ EPS_ASM_Data_6 : 56|8@1+ (1,0) [0|255] "Unit_None"  Airbag

CM_ BO_ 870 "Nur die Kombination des statischen und toggelnden Signals ergibt den Blinktakt für die Hell & Dunkelphase";
CM_ BO_ 903 "Schnittstelle EBKV - Kombi";
CM_ BO_ 2463978646 "ab MQB ohne CHK und mit geänderter Sendeart";
CM_ BO_ 1520 "ab MQB nach abgestimmten FLH Dimmung";

CM_ SG_ 2527679952 BFSFo_Position_2_BZ "4bit Botschaftszähler, wird mit jeder Sendebotschaft inkrementiert";
CM_ SG_ 2527679952 BFSFo_Position_2_CRC "Für MLB:
Berechnung siehe Lastenheft 'Kommunikationsabsicherung für FlexRay und CAN'
Ab MQB und MLBevo:
Berechnung siehe Lastenheft 'End-to-End Kommunikationsabsicherung'

Endwerte siehe Begleitdokument 'S-PDU Kennungsfolgen'";
CM_ SG_ 2527679952 HBFSS_Bein_ZielPos_BFSS "Zielposition_Bein_BFS_fuer EA_HBFS";
CM_ SG_ 2527679952 HBFSS_Hoehe_ZielPos_BFSS "HBFSS_Hoehe_ZielPos_BFSS";
CM_ SG_ 2527679952 HBFSS_Laenge_ZielPos_BFSS "Zielposition_Laenge_BFS_fuer EA_HBFS";
CM_ SG_ 2527679952 HBFSS_Lehne_ZielPos_BFSS "Zielposition_Lehne_BFS_fuer EA_HBFS";
CM_ SG_ 2527679952 HBFSS_Torso_Pos "Sitzwinkelposition für den Torso-Airbag";

CM_ SG_ 870 Blinken_li_Fzg_Takt "Fzg-Takt Blinker links

";
CM_ SG_ 870 Blinken_li_Kombi_Takt "Kombi-Takt Blinker links

";
CM_ SG_ 870 Blinken_re_Fzg_Takt "Fzg-Takt Blinker rechts

";
CM_ SG_ 870 Blinken_re_Kombi_Takt "Kombi-Takt Blinker rechts

";
CM_ SG_ 870 Blinkmodi_02_BZ "4bit Botschaftszähler, wird mit jeder Sendebotschaft inkrementiert";
CM_ SG_ 870 Blinkmodi_02_CRC "Für MLB:
Berechnung siehe Lastenheft 'Kommunikationsabsicherung für FlexRay und CAN'
Ab MQB und MLBevo:
Berechnung siehe Lastenheft 'End-to-End Kommunikationsabsicherung'

Endwerte siehe Begleitdokument 'S-PDU Kennungsfolgen'";
CM_ SG_ 870 BM_Autobahn "Status Autobahnblinken
";
CM_ SG_ 870 BM_Crash "Status Crashblinken
";
CM_ SG_ 870 BM_DWA_Alarm "Status DWA-Alarmblinken
";
CM_ SG_ 870 BM_DWA_ein "Status Quittierungsblinken DWA";
CM_ SG_ 870 BM_GDO "Blinken bei UGDO anlernen

";
CM_ SG_ 870 BM_HD_Oeffnung_angelernt "HD_Rueckmeld_prog eine Blinkerquittierung wird beim BCM2 angefordert.
Wenn die Geschwindigkeit kleiner einer vorgegebenen Schwelle (default 2km/h) ist wird das Signal BM_HD_Öffnung_angelernt versendet und die Blinkerquittierung ausgelöst";
CM_ SG_ 870 BM_links "Richtungsblinken links

";
CM_ SG_ 870 BM_NBA_n_codiert_n_aktiv "Notbremsanzeige nicht codiert/nicht aktiv (Fehler)";
CM_ SG_ 870 BM_NBA_Status "Notbremsanzeige Status nicht aktiv / BRL Dunkelphase / BRL Hellphase";
CM_ SG_ 870 BM_Not_Bremsung "Das Signal BM_Not_Bremsung  zeigt an,  ob ein Warnblinken aufgrund einer vom Bremssystem signalisierten Notbremsung aktiv ist.";
CM_ SG_ 870 BM_Panik "Panikblinken
";
CM_ SG_ 870 BM_PiloPa "Quittierungsblinken bei pilotierten Parkvorgängen";
CM_ SG_ 870 BM_Recas "Blinkermodus RECAS  (RearEndCollisionAlertSignal)";
CM_ SG_ 870 BM_rechts "Richtungsblinken rechts

";
CM_ SG_ 870 BM_Rollenmodus_Blinken "Das Signal wird statisch gesetzt, wenn die Blinkerart Rollenmodus_Blinken aktiv ist.";
CM_ SG_ 870 BM_Taxi_Notalarm "Blinken bei Taxi-Not-Alarm

";
CM_ SG_ 870 BM_Telematik "Telematikblinken
";
CM_ SG_ 870 BM_Telematik_Abbruchgrund "Gibt bei erwaretem aber ausbleibendem Flankenanstieg der BM_Telematik an wieso die Ausführung verhindert wurde. Bei Flankenabfall der BM_Telematik wird angegeben wieso die Ausführung beendet wurde.

Bei nicht bereitem Sender soll 'init' gesendet werden,";
CM_ SG_ 870 BM_Warnblinken "Warnblinken

";
CM_ SG_ 870 BM_WBA_Warnblinken "Rückkanal des durch WBA (Warnen, Bremsen, Ausweichen) angeforderten Warnblinken";
CM_ SG_ 870 BM_WBT_Beleuchtung "Aktivierung Warnblinktasterfunktionsbeleuchtung
Warnblinktasterfunktionsbeleuchtung soll aktiviert werden (statisch auf 1)";
CM_ SG_ 870 BM_Wischblinken "Blinkermodus Wisch_Blinken";
CM_ SG_ 870 BM_ZV_auf "Blinken bei ZV auf

";
CM_ SG_ 870 BM_ZV_zu "Blinken bei ZV zu

";
CM_ SG_ 870 SAL_RHP_Blinken_Status "SAL Rückmeldung Rush Hour Pilot Blinker-Status an Funktion RHP";
CM_ SG_ 870 SAL_RHP_Warnblinken "Rückkanal des durch RHP angeforderten Warnblinken";
CM_ SG_ 870 SAL_TA_Blinken_Status "SAL RückmeldungTravelAssist Blinker-Status an Funktion TA (MFK)";

CM_ SG_ 903 Bremse_EV_02_CRC "Für MLB:
'Berechnung siehe Lastenheft 'Kommunikationsabsicherung für FlexRay und CAN''

Ab MQB und MLBevo:
'Berechnung siehe Lastenheft 'End-to-End Kommunikationsabsicherung''

Endwerte siehe Begleitdokument 'S-PDU Kennungsfolgen'";
CM_ SG_ 903 EBKV_BKL_Warnungen "Ansteuerung der BKL-Lampe";
CM_ SG_ 903 EBKV_Charisma_FahrPr "Aktuell eingestellte Kennlinie EBKV";
CM_ SG_ 903 EBKV_Charisma_Status "Systemstatus des FPA-Teilnehmers EBKV";
CM_ SG_ 903 EBKV_Hinweise "Ansteuerung der Textanzeige";
CM_ SG_ 903 EBKV_SpannungsAnf "Anforderung eines Mindest-Spannungs-Niveaus an das NVEM";
CM_ SG_ 903 EBKV_Warnungen "Ansteuerung Kombi zur Fahrerwarnung";
CM_ SG_ 903 EPB_Fehlermeldung_ext "Über das Signal werden bestimmte Fehlertexte und -lampen für den separat angeschlossenen Aktuator im Kombi angefordert. Signal wird nur im MEB verwendet.";
CM_ SG_ 903 EPB_Funktionslampe_ext "Ersatzsignal um im Fehlerfall eine Anzeige im Kombi zu triggern. Signal wird nur im MEB verwendet.";

CM_ SG_ 2463978646 CHA_Current_Mode "Aktuell eingestelltes Charisma Fahrprogramm";
CM_ SG_ 2463978646 CHA_Fahrer_Umschaltung "Die manuelle Umschaltung durch den Fahrer soll signalisiert werden, um zu automatischen Umschaltungen (z.B. Retries) differenzieren zu können.";
CM_ SG_ 2463978646 CHA_Fahrer_Umschaltung_BMA "Die manuelle Umschaltung der Betriebsmodusauswahl durch den Fahrer soll signalisiert werden, um zu automatischen Umschaltungen (z.B. Retries) differenzieren zu können.";
CM_ SG_ 2463978646 CHA_Ziel_FahrPr_ACC "MQB
Anforderung Ziel-Fahrprogramm ACC";
CM_ SG_ 2463978646 CHA_Ziel_FahrPr_AEB "Anforderung Ziel-Fahrprogramm AEB (Autonomous Emergency Braking)";
CM_ SG_ 2463978646 CHA_Ziel_FahrPr_AFR "Anforderung Ziel-Fahrprogramm Aktive Fahrwerk Regelung (eAWS und eABC)";
CM_ SG_ 2463978646 CHA_Ziel_FahrPr_AFS "Anforderung Ziel-Fahrprogramm AFS";
CM_ SG_ 2463978646 CHA_Ziel_FahrPr_AGA "Anforderung Ziel-Fahrprogramm AGA/SAK2 (Aussensound)";
CM_ SG_ 2463978646 CHA_Ziel_FahrPr_AGK "Signal zur Ansteuerung des Teilnehmers Abgasklappen durch den Charisma-Koordinator über das Motor-SG";
CM_ SG_ 2463978646 CHA_Ziel_FahrPr_ALR "Anforderung Ziel-Fahrprogramm Allrad";
CM_ SG_ 2463978646 CHA_Ziel_FahrPr_AV "Anforderung Ziel-Fahrprogramm AreaView2";
CM_ SG_ 2463978646 CHA_Ziel_FahrPr_BMS "Anforderung Ziel-Fahrprogramm BMS (nähere Spezifikation siehe Charisma-LH PAG)";
CM_ SG_ 2463978646 CHA_Ziel_FahrPr_DR "Anforderung Ziel-Fahrprogramm Dämpfer";
CM_ SG_ 2463978646 CHA_Ziel_FahrPr_EAR "Anforderung Zielfahrprogramm EAR (EFP Allrad Regelsysteme)";
CM_ SG_ 2463978646 CHA_Ziel_FahrPr_EBKV "Signal zur Ansteuerung des EBKV durch den Charisma-Koordinator";
CM_ SG_ 2463978646 CHA_Ziel_FahrPr_EDS "Anforderung Ziel-Fahrprogramm Elektronische Differentialsperre";
CM_ SG_ 2463978646 CHA_Ziel_FahrPr_EPS "Anforderung Ziel-Fahrprogramm Elektrische Lenkhilfe";
CM_ SG_ 2463978646 CHA_Ziel_FahrPr_eSound "Anforderung Ziel-Fahrprogramm eSound";
CM_ SG_ 2463978646 CHA_Ziel_FahrPr_ESP "Anforderung Ziel-Fahrprogramm ESP";
CM_ SG_ 2463978646 CHA_Ziel_FahrPr_FCWO "Anforderung Ziel-Fahrprogramm FCWO (Objektwarnung)";
CM_ SG_ 2463978646 CHA_Ziel_FahrPr_FCWP "Anforderung Ziel-Fahrprogramm FCWP (Personenwarnung)";
CM_ SG_ 2463978646 CHA_Ziel_FahrPr_Freilauf "Anforderung Ziel-Fahrprogramm Funktion Freilauf";
CM_ SG_ 2463978646 CHA_Ziel_FahrPr_GE "Anforderung Ziel-Fahrprogramm Getriebe";
CM_ SG_ 2463978646 CHA_Ziel_FahrPr_HAL "Anforderung Zielfahrprogramm Hinterachslenkung (HAL)";
CM_ SG_ 2463978646 CHA_Ziel_FahrPr_HDC "Anforderung Ziel-Fahrprogramm Hill Descent Control";
CM_ SG_ 2463978646 CHA_Ziel_FahrPr_HHC "Anforderung Ziel-Fahrprogramm Hill Hold Control";
CM_ SG_ 2463978646 CHA_Ziel_FahrPr_IL "Anforderung Ziel-Fahrprogramm Integrallenkung";
CM_ SG_ 2463978646 CHA_Ziel_FahrPr_mFDR "Signal zur Ansteuerung des mFDR durch den Charisma-Koordinator";
CM_ SG_ 2463978646 CHA_Ziel_FahrPr_MO "Anforderung Ziel-Fahrprogramm Motor";
CM_ SG_ 2463978646 CHA_Ziel_FahrPr_MO_BZS "Anforderung Zielfahrprogramm Motor-Betriebszusände";
CM_ SG_ 2463978646 CHA_Ziel_FahrPr_MO_Freilauf "Anforderung Ziel-Fahrprogramm Funktion Freilauf Motor aus";
CM_ SG_ 2463978646 CHA_Ziel_FahrPr_MO_StSt "Anforderung Ziel-Fahrprogramm Funktion Motor Start-Stopp";
CM_ SG_ 2463978646 CHA_Ziel_FahrPr_MXB "Anforderung Ziel-Fahrprogramm MXB";
CM_ SG_ 2463978646 CHA_Ziel_FahrPr_NR "Anforderung Ziel-Fahrprogramm Niveaureglierung";
CM_ SG_ 2463978646 CHA_Ziel_FahrPr_PACC "Anforderung Ziel-Fahrprogramm InnoDrive (PACCh)";
CM_ SG_ 2463978646 CHA_Ziel_FahrPr_PDC "Signal zur Ansteuerung des PDC/PLA durch den Charisma-Koordinator";
CM_ SG_ 2463978646 CHA_Ziel_FahrPr_PreCrash "Anforderung Ziel-Fahrprogramm PreCrash";
CM_ SG_ 2463978646 CHA_Ziel_FahrPr_QS "Anforderung Ziel-Fahrprogramm geregelte Hinterachsquersperre";
CM_ SG_ 2463978646 CHA_Ziel_FahrPr_Reku_ZwGas "Anforderung Ziel-Fahrprogramm für Rekuperation oder Zwischengas";
CM_ SG_ 2463978646 CHA_Ziel_FahrPr_RHP "MQB
Anforderung Ziel-Fahrprogramm RHP";
CM_ SG_ 2463978646 CHA_Ziel_FahrPr_SAK "Anforderung Ziel-Fahrprogramm Soundaktuator";
CM_ SG_ 2463978646 CHA_Ziel_FahrPr_SCU "Anforderung Ziel-Fahrprogramm SCU";
CM_ SG_ 2463978646 CHA_Ziel_FahrPr_ToS_laengs "Signal zur Ansteuerung des Torque Splitter längs durch den Charisma-Koordinator";
CM_ SG_ 2463978646 CHA_Ziel_FahrPr_ToS_quer "Signal zur Ansteuerung des Torque Splitter quer durch den Charisma-Koordinator";
CM_ SG_ 2463978646 CHA_Ziel_FahrPr_VAQ "Anforderung Ziel-Fahrprogramm VAQ";

CM_ SG_ 918 DR_Gelbe_Warnlampe "Bit wird gesetzt, wenn während des Betriebes ein Fehler erkannt wird.";

CM_ SG_ 514 DR_Aufbaubeschleunigung_HL "Aufbaubeschleunigungssensor
Auflösung 1g/300 
Wertebereich -1,6g..1,6g 
in m/s^2 übertragen.";
CM_ SG_ 514 DR_Aufbaubeschleunigung_HR "Aufbaubeschleunigungssensor
Auflösung 1g/300 
Wertebereich -1,6g..1,6g 
in m/s^2 übertragen.";
CM_ SG_ 514 DR_Aufbaubeschleunigung_VL "Aufbaubeschleunigungssensor
Auflösung 1g/300 
Wertebereich -1,6g..1,6g 
in m/s^2 übertragen.";
CM_ SG_ 514 DR_Aufbaubeschleunigung_VR "Aufbaubeschleunigungssensor
Auflösung 1g/300 
Wertebereich -1,6g..1,6g 
in m/s^2 übertragen.";
CM_ SG_ 514 DR_Daempferweg_HL "Bei DCC-System: 0mm entspricht
maximal eingefedert.";
CM_ SG_ 514 DR_Daempferweg_HR "Bei DCC-System: 0mm entspricht
maximal eingefedert.";
CM_ SG_ 514 DR_Daempferweg_VL "Bei DCC-System: 0mm entspricht
maximal eingefedert.";
CM_ SG_ 514 DR_Daempferweg_VR "Bei DCC-System: 0mm entspricht
maximal eingefedert.";
CM_ SG_ 514 DR_Drehwinkel_HL "Drehwinkelsensor zur Berechnung von Dämpferweg und  für LWR";
CM_ SG_ 514 DR_Drehwinkel_HR "Drehwinkelsensor zur Berechnung von Dämpferweg und  für LWR";
CM_ SG_ 514 DR_Drehwinkel_VL "Drehwinkelsensor zur Berechnung von Dämpferweg und  für LWR";
CM_ SG_ 514 DR_Drehwinkel_VR "Drehwinkelsensor zur Berechnung von Dämpferweg und  für LWR";
CM_ SG_ 514 DR_Drehwinkelsensortausch_HL "Zähler der bei jedem erkannten Drehwinkelsensortausch inkrementiert wird. Systeme die den Drehwinkelwert empfangen können notwendigen Inbetriebnahmefunktionen starten";
CM_ SG_ 514 DR_Drehwinkelsensortausch_HR "Zähler der bei jedem erkannten Drehwinkelsensortausch inkrementiert wird. Systeme die den Drehwinkelwert empfangen können notwendigen Inbetriebnahmefunktionen starten";
CM_ SG_ 514 DR_Drehwinkelsensortausch_VL "Zähler der bei jedem erkannten Drehwinkelsensortausch inkrementiert wird. Systeme die den Drehwinkelwert empfangen können notwendigen Inbetriebnahmefunktionen starten";
CM_ SG_ 514 DR_Drehwinkelsensortausch_VR "Zähler der bei jedem erkannten Drehwinkelsensortausch inkrementiert wird. Systeme die den Drehwinkelwert empfangen können notwendigen Inbetriebnahmefunktionen starten";
CM_ SG_ 514 DR_Funktionsstatus "Funktionsstatus des DCC_Gen3-SG";

CM_ SG_ 2463978758 DR_DCCMonitor_I_Add "Summen-Dämpferstrom zur Anzeige im DCC-Monitor in % auf den max. Strom bezogen.";
CM_ SG_ 2463978758 DR_DCCMonitor_I_HL "Dämpferstrom zur Anzeige im DCC-Monitor in % auf den max. Strom bezogen.";
CM_ SG_ 2463978758 DR_DCCMonitor_I_HR "Dämpferstrom zur Anzeige im DCC-Monitor in % auf den max. Strom bezogen.";
CM_ SG_ 2463978758 DR_DCCMonitor_I_SZ_Add "Schleppzeigerwert für DR_DCCMonitor_I_Add";
CM_ SG_ 2463978758 DR_DCCMonitor_I_SZ_HL "Schleppzeigerwert für DR_DCCMonitor_I_HL";
CM_ SG_ 2463978758 DR_DCCMonitor_I_SZ_HR "Schleppzeigerwert für DR_DCCMonitor_I_HR";
CM_ SG_ 2463978758 DR_DCCMonitor_I_SZ_VL "Schleppzeigerwert für DR_DCCMonitor_I_VL";
CM_ SG_ 2463978758 DR_DCCMonitor_I_SZ_VR "Schleppzeigerwert für DR_DCCMonitor_I_VR";
CM_ SG_ 2463978758 DR_DCCMonitor_I_VL "Dämpferstrom zur Anzeige im DCC-Monitor in % auf den max. Strom bezogen.";
CM_ SG_ 2463978758 DR_DCCMonitor_I_VR "Dämpferstrom zur Anzeige im DCC-Monitor in % auf den max. Strom bezogen.";

CM_ SG_ 2549891590 DIA_eCS_Req_Data "Diagnose Request Flashen <SG-Name>";

CM_ SG_ 2621456902 DIA_eCS_Req_FD_Data "Diagnose Request Flashen eCS";

CM_ SG_ 2550022662 DIA_eCS_Resp_Data "Diagnose Response Flashen <SG-Name>";

CM_ SG_ 2621587974 DIA_eCS_Resp_FD_Data "Diagnose Response Flashen eCS";

CM_ SG_ 2549880606 DIA_RGS_HL_Req_Data "Diagnose Request Flashen RGS_HL";

CM_ SG_ 2621445918 DIA_RGS_HL_Req_FD_Data "Diagnose Request FD RGS_HL";

CM_ SG_ 2550011678 DIA_RGS_HL_Resp_Data "Diagnose Response Flashen RGS_HL";

CM_ SG_ 2621576990 DIA_RGS_HL_Resp_FD_Data "Diagnose Response FD RGS_HL";

CM_ SG_ 2549880607 DIA_RGS_HR_Req_Data "Diagnose Request Flashen RGS_HR";

CM_ SG_ 2621445919 DIA_RGS_HR_Req_FD_Data "Diagnose Request FD RGS_HR";

CM_ SG_ 2550011679 DIA_RGS_HR_Resp_Data "Diagnose Response Flashen RGS_HR";

CM_ SG_ 2621576991 DIA_RGS_HR_Resp_FD_Data "Diagnose Response FD RGS_HR";

CM_ SG_ 2549880362 DIA_RGS_VL_Req_Data "Diagnose Request Flashen RGS_VL";

CM_ SG_ 2621445674 DIA_RGS_VL_Req_FD_Data "Diagnose Request FD RGS_VL";

CM_ SG_ 2550011434 DIA_RGS_VL_Resp_Data "Diagnose Response Flashen RGS_VL";

CM_ SG_ 2621576746 DIA_RGS_VL_Resp_FD_Data "Diagnose Response FD RGS_VL";

CM_ SG_ 2549880363 DIA_RGS_VR_Req_Data "Diagnose Request Flashen RGS_VR";

CM_ SG_ 2621445675 DIA_RGS_VR_Req_FD_Data "Diagnose Request FD RGS_VR";

CM_ SG_ 2550011435 DIA_RGS_VR_Resp_Data "Diagnose Response Flashen RGS_VR";

CM_ SG_ 2621576747 DIA_RGS_VR_Resp_FD_Data "Diagnose Response FD RGS_VR";

CM_ SG_ 1714 DGN_Verlernzaehler "wrap around 254 --> 0";
CM_ SG_ 1714 KBI_Kilometerstand "Fehler wird ausgegeben, falls Kilometerstand nicht restaurierbar
";
CM_ SG_ 1714 UH_Minute "0x3C- 0x3f = Werte ungültig";
CM_ SG_ 1714 UH_Monat "0x0D, 0xF =  Werte ungültig
0x0E = Relatives Datum (nur VW)";
CM_ SG_ 1714 UH_Sekunde "0x3C- 0x3f = Werte ungültig";
CM_ SG_ 1714 UH_Stunde "0x18 - 0x1F = Werte ungültig";
CM_ SG_ 1714 UH_Tag "0x0: reserviert bei VW";
CM_ SG_ 1714 Uhrzeit_01_alt "
";
CM_ SG_ 1714 Vehicle_Driving_Cycle "Optimierung der Inbetriebnahme von Steuergeräten in einem Teilverbau in der Produktion.
Siehe VW80114. Signal bildet (durch eine Gateway-Funktion) den Inhalt des Signals OBD_Driving_Cycle ab.";

CM_ SG_ 1520 BCM1_Stellgroesse_Kl_58s "Rohwert Dimmpoti";
CM_ SG_ 1520 DI_Display_Nachtdesign "Für Displays sind oft  automatische Umschaltungen von Tag-/Nachtdesign vorgesehen.
Es gibt jedoch Zustände, an denen auch tagsüber das Abblendlicht eingeschaltet ist.
z.B. Dauerfahrlicht, Geschwindigkeitsabhängiges 'Licht-An-Bei-Autobahn', 'Regenlicht',";
CM_ SG_ 1520 DI_Fotosensor "Helligkeitswert Fotosensor
Für die Dimmung relevanter Wert zur Sensierung der Umgebungshelligkeit
Im Detail beschrieben im 'Funktionslastenheft Dimmung MQB'.";
CM_ SG_ 1520 DI_KL_58xd "Klemme 58xd Display- und Funktionsbeleuchtung
Mit der Klemme 58xd wird die Helligkeit der Display- und der Funktionsbeleuchtungen der Schalter gesteuert.
Im Detail beschrieben im 'Funktionslastenheft Dimmung MQB'.";
CM_ SG_ 1520 DI_KL_58xs "Suchbeleuchtung Schalter
EIN-AUS-Schaltalgorithmus der allgemeinen Schaltersuchbeleuchtung. 
Im Detail beschrieben im 'Funktionslastenheft Dimmung MQB'.
";
CM_ SG_ 1520 DI_KL_58xt "Timergesteuerte Suchbeleuchtung
Der EIN-AUS-Schaltalgorithmus für die vor- und nachlaufende Schaltersuchbeleuchtungen beim Ein- & Aussteigen; z.B.: Start/Stop-Taster.
Im Detail beschrieben im 'Funktionslastenheft Dimmung MQB'.";

CM_ SG_ 331 DSR_01_Sendestatus "Umschalten zwischen langsamem und schnellem Zyklus der DSR_01-Botschaft";
CM_ SG_ 331 DSR_QFK_AnfStat "Statusinformationen des Anforderers";
CM_ SG_ 331 DSR_QFK_Art1 "Auswahlsignal für DSR_QFK_Signal1";
CM_ SG_ 331 DSR_QFK_Art2 "Auswahlsignal für DSR_QFK_Signal2";
CM_ SG_ 331 DSR_QFK_KrSoll "Krümmungsanforderung";
CM_ SG_ 331 DSR_QFK_KrSoll_VZ "Vorzeichen für die Krümmungsanforderung";
CM_ SG_ 331 DSR_QFK_KruemmSoll "Krümmungsanforderung";
CM_ SG_ 331 DSR_QFK_KruemmSoll_VZ "Vorzeichen für die Krümmungsanforderung";
CM_ SG_ 331 DSR_QFK_Signal1 "Inhalt DSR_QFK_Signal1 wird durch das Signal DSR_QFK_Art1 gesteuert.
Nähere Informationen im LAH Querführungskoordinator.";
CM_ SG_ 331 DSR_QFK_Signal2 "Inhalt DSR_QFK_Signal2 wird durch das Signal DSR_QFK_Art2 gesteuert.
Nähere Informationen im LAH Querführungskoordinator.";
CM_ SG_ 331 DSR_QFK_Spuerb "Spürbarkeitsanforderung. Legt fest, mit welchem Handmoment die angeforderte Krümmung überlenkt werden muss.";
CM_ SG_ 331 SOK_DSR_01_Signatur "Signatur im Rahmen der durch SOK geschützen Broadcast-Kommunikation

Geschützte Funktion: Driver Steering Recommendation
Geschützte Botschaft: DSR_01";

CM_ SG_ 420 EA_01_BZ "EA Botschaftszähler";
CM_ SG_ 420 EA_01_CRC "Ab MQB und MLBevo:
'Berechnung siehe Lastenheft 'End-to-End Kommunikationsabsicherung''";
CM_ SG_ 420 EA_01_Sendestatus "Gibt den Sendestatus der Botschaft EA_01 an (notwendig für IL-Unterstützung)";
CM_ SG_ 420 EA_aktiv_laengs "Zeigt an, ob der Emergency Assist aktiv längs regelt.";
CM_ SG_ 420 EA_Anf_Prefill "Emergency Assist Anforderung an Prefill";
CM_ SG_ 420 EA_Anforderung_HMS "Emergency Assist Anforderung an HMS";
CM_ SG_ 420 EA_Funktionsstatus "Emergency Assist Funktionsstatus";
CM_ SG_ 420 EA_Gurtstraffer_Anf "Emergency Assist Anforderung reversibler Gurtstraffer";
CM_ SG_ 420 EA_Parken_beibehalten_HMS "Anforderung um automatisches lösen der Parkbremse zu verhindern";
CM_ SG_ 420 EA_PreCrash_Anf "Emergency Assist Anforderung PreCrash";
CM_ SG_ 420 EA_Ruckfreigabe "Emergency Alert Freigabit für die Warnruck-Anforderung an das ESP";
CM_ SG_ 420 EA_Ruckstaerke "Anforderung der Ruckstaerke in schwach, mittel oder stark.";
CM_ SG_ 420 EA_Sollbeschleunigung "Emergency Assist Beschleunigungsanforderung";
CM_ SG_ 420 EA_Warnruckprofil "Emergency Assist Anforderung an ESP, welcher Ruck verwendet werden soll.";

CM_ SG_ 496 ACF_Lampe_Hands_Off "Anzeige, ob der Fahrer die Hände am Lenkrad hat.";
CM_ SG_ 496 EA_02_BZ "Botschaftszähler";
CM_ SG_ 496 EA_02_CRC "Für MLB:
'Berechnung siehe Lastenheft 'Kommunikationsabsicherung für Flexray und CAN''

Ab MQB und MLBevo:
'Berechnung siehe Lastenheft 'End-to-End Kommunikationsabsicherung'

Endwerte siehe Begleitdokument 'S-PDU Kennungsfolge'";
CM_ SG_ 496 EA_Blinken "Emergency Assist Anforderung Blinker";
CM_ SG_ 496 EA_Bremslichtblinken "Die Funktion Emergency Alert fordert ein Blinken der Bremsleuchten an.";
CM_ SG_ 496 EA_eCall_Anf "Emergency Assist Anforderung eCall";
CM_ SG_ 496 EA_Fahrzeughupe_Anf "Emergency Assist Anforderung Fahrzeughupe";
CM_ SG_ 496 EA_Infotainment_Anf "Emergency Assist Anforderung Absenkung Infotainment-Funktionen";
CM_ SG_ 496 EA_Innenraumlicht_Anf "Anforderung Innenraumbeleuchtung durch den Emergency Assist";
CM_ SG_ 496 EA_Status_HMI "Anzeige Emergency Assist-Statusleuchte im Fahrerinformationsdisplay";
CM_ SG_ 496 EA_Texte "Anzeige der EA Texte";
CM_ SG_ 496 EA_Tueren_Anf "Emergency Assist Anforderung Türen entriegeln";
CM_ SG_ 496 EA_Warnlevel "Kritikalität der Funktion Emergency Assist";
CM_ SG_ 496 STP_Primaeranz "Primäranzeige des Staupiloten";
CM_ SG_ 496 zFAS_Warnblinken "Anforderung Warnblinken durch zFAS Funktionen.";

CM_ SG_ 236 EBKV_02_BZ "4bit Botschaftszähler, wird mit jeder Sendebotschaft inkrementiert";
CM_ SG_ 236 EBKV_02_CRC "Für MLB:
Berechnung siehe Lastenheft 'Kommunikationsabsicherung für FlexRay und CAN'
Ab MQB und MLBevo:
Berechnung siehe Lastenheft 'End-to-End Kommunikationsabsicherung'

Endwerte siehe Begleitdokument 'S-PDU Kennungsfolgen'";
CM_ SG_ 236 EBKV_AktBr_aktiv "Fahreranteil an Aktivbremsung";
CM_ SG_ 236 EBKV_aktBr_Volumenstrom_Ist "Istvolumenstrom für Aktivbremsung per eBKV,";
CM_ SG_ 236 EBKV_extBr_Druck_Max "Das Signal übermittelt seitens des EBKV den maximal abbildbaren Druck, der durch eine Volumenstromanforderung mittels ESC angesteuert werden kann.";
CM_ SG_ 236 EBKV_extBr_Status "beschreibt den eBKV-seitigen Status zur Realisierung einer externen Druckanforderung, gestellt durch das ESC";
CM_ SG_ 236 EBKV_Stangenweg "Ausgangsstangenweg des eBKV";
CM_ SG_ 236 EBKV_Stangenweg_Fahrerwunsch "Zielwert für die eBKV-Ausgangsstange, berechnet aus dem Fahrerwunsch an der Eingangsstange. Bei externer Druckanforderung wird der Wert ebenfalls ausgegeben.

Achtung! Der aktuelle, tatsächliche Ausgangsstangenweg, z.B. während dynamischer Bremsbetätigu";
CM_ SG_ 236 SOK_EBKV_02_Signatur "Signatur im Rahmen der durch SOK geschützen Broadcast-Kommunikation

Geschützte Funktion: Bremsfunktionen: Rekuperation und Blending
Geschützte Botschaft: EBKV_02";

CM_ SG_ 374 EBKV_03_BZ "4bit Botschaftszähler, wird mit jeder Sendebotschaft inkrementiert";
CM_ SG_ 374 EBKV_03_CRC "Für MLB:
Berechnung siehe Lastenheft 'Kommunikationsabsicherung für FlexRay und CAN'
Ab MQB und MLBevo:
Berechnung siehe Lastenheft 'End-to-End Kommunikationsabsicherung'

Endwerte siehe Begleitdokument 'S-PDU Kennungsfolgen'";
CM_ SG_ 374 EBKV_Activate_Fallback_ESP "Das Signal aktiviert im ESC die Rückfallebene.";
CM_ SG_ 374 EBKV_Anforderung_HMS "Anforderung an dem Haltemanager vom EBKV";
CM_ SG_ 374 EBKV_Aussteuerdruck "Das Signal übermittelt seitens des EBKVs frühzeitig den aktuellen, Fahrsituations-abhängig-variablen Brems-Vordruck an das ESC, bei dem die maximale Bremskraftunterstützung des EBVK erreicht ist. 
Über diesen übermittelten Druck-Wert erkennt das ESC den ";
CM_ SG_ 374 EBKV_Bremspedalweg "Bremspedalwert in Prozent. Der Wert ist Nullpunkt-abgeglichen.
Bremspedalweg von der EBKV eingelesen.";
CM_ SG_ 374 EBKV_Diagnose "eBKV im Diagnosemodus";
CM_ SG_ 374 EBKV_Fahrer_bremst "Fahrer will bremsen (Eintreterkennung).
Wird benötigt, um ACC oder GRA abzuschalten.";
CM_ SG_ 374 EBKV_Fahrer_bremst_deutlich "Rückmeldung des eBKVs, ob der Fahrer deutlich eine Bremsung wünscht.

Eine Aktivierung des Signals erfolgt bei 50N Pedalkraft (Druckäquivalent= 20bar, verwendet in AWV-Fkt.)
";
CM_ SG_ 374 EBKV_Kraftblending_Reserve "Maximale Druckdifferenz, die durch Pedalkraftblending noch simuliert werden kann";
CM_ SG_ 374 EBKV_OBD_Status "Ansteuerung der MIL-Lampe über den MIL-Master (Motorsteuergerät)";
CM_ SG_ 374 EBKV_QBit_Fahrer_bremst "
";
CM_ SG_ 374 EBKV_Restdruckabsenkung "Dieses Signal ermöglicht die Steuerung einer Routine zur Restdruckabsenkung aus dem eBKV heraus.
Die genaue Funktionsausprägung muss für das jeweilige Projekt festgelegt werden.";
CM_ SG_ 374 EBKV_Status_02 "eBKV Status Signal für 2 und 3 Box Systeme";
CM_ SG_ 374 EBKV_Textanzeigen "Das Signal sendet im Hinweisfall den Status des eBKV an das Kombiinstrument, welcher das Fahrzeugverhalten für den Nutzer plausibilisieren soll.";
CM_ SG_ 374 EBKV_VMM_Sek_Notstopp_Status "Beschreibt den eBKV -seitigen Status zur Kommunikation mit der Steuerung der Notstopp Rückfallebene im ESC";
CM_ SG_ 374 EPB_Status_ext "Zustand des separat angeschlossenen Aktuators. Signal wird nur im MEB verwendet.";
CM_ SG_ 374 SBS_Anforderung_GE "Das Sekundärbremssystem (SBS) realisiert mit dieser Schnittstelle ein Sichern des Fahrzeugs. Nach einer Bremsung in den Stillstand über die direkte Verzögerungsschnittstelle wird hierüber die Getriebesperre angefordert.";
CM_ SG_ 374 SOK_EBKV_03_Signatur "Signatur im Rahmen der durch SOK geschützten Broadcast-Kommunikation

Geschützte Funktion: Bremsfunktionen Rekuperation und Blending
Geschützte Botschaft: EBKV_03";

CM_ SG_ 2589283963 EBKV_Indc_StChk "OBM Inducement Request TestNotCompletedThisOperationCycle";
CM_ SG_ 2589283963 EBKV_Indc_StFail "OBM-Inducement Request TestFailed";
CM_ SG_ 2589283963 EBKV_OBD_Status_Auth "Ansteuerung der MIL-Lampe über den MIL-Master (Motorsteuergerät)
Redundantes Signal (SOK gesichert) zu EBKV_OBD_Status";
CM_ SG_ 2589283963 OBDProtocol_EBKV "Bestätigung des aktuell umgesetzten Scan Tool Protokolls";
CM_ SG_ 2589283963 SOK_EBKV_05_Signatur "Signatur im Rahmen der durch SOK geschützen Broadcast-Kommunikation

Geschützte Funktion: OBD-Malfunction Indicator Light (MIL)
Geschützte PDU: EBKV_05";

CM_ SG_ 193 CluAxs_Avl "Verfügbarkeit der Kupplung an der elektrischen Hinterachse";
CM_ SG_ 193 CluAxs_State "Status der Kupplung an der elektrischen Hinterachse";
CM_ SG_ 193 EM2_01_BZ "4bit Botschaftszähler, wird mit jeder Sendebotschaft inkrementiert
Botschaft asynchron geroutet. Zählerwert kann springen.";
CM_ SG_ 193 EM2_01_CRC "Für MLB:
Berechnung siehe Lastenheft 'Kommunikationsabsicherung für FlexRay und CAN'
Ab MQB und MLBevo:
Berechnung siehe Lastenheft 'End-to-End Kommunikationsabsicherung'

Endwerte siehe Begleitdokument 'S-PDU Kennungsfolgen'";
CM_ SG_ 193 EM2_AR_aktiv "Ruckeldämpfer aktiv";
CM_ SG_ 193 EM2_ErwGrenzen_aktiv "Die absoluten Momentengrenzen sind für die Durchführung eines VKM-Starts ggf. aufgeweitet";
CM_ SG_ 193 EM2_Fehler_ElAntriebAbschaltung "Fehler: PWR befindet sich im aktiven Kurzschluss
alle vom EMS gesendeten Max- und Min-Momente und das aktuelle EM-Moment nehmen in diesem Zustand den Wert des für die aktuelle Drehzahl entsprechenden Schleppmoments der E-Maschine an";
CM_ SG_ 193 EM2_Fehler_Notabschaltung "Fehler: Leistungselektronik fordert Abschaltung des HV-Netzes wegen eines schweren Fehlers an";
CM_ SG_ 193 EM2_IstDrehzahl "Momentanwert: E-Maschinen Drehzahl";
CM_ SG_ 193 EM2_Istmodus "aktuelle Betriebsart der E-Maschine...
0: Standby; Kommunikation aktiv; PSM: Aktiver Kurzschluss eingenommen
1: Momentenreglung
2: Drezahlregeung (interner Regelkreis)
3: Spannungsregelung
4: Drehzahlregelung (externer Regelkreis)
5: interner Invert";
CM_ SG_ 193 EM2_IstMoment "Momentanwert: E-Maschinen Moment";
CM_ SG_ 193 EM2_IstSpannung "Momentanwert: HV-Spannung am PWR";
CM_ SG_ 193 EM2_Max_Moment "maximal darstellbares Moment für eine im Funktionslastenheft definierte Dauer

Die Berechnung der Momentengrenzen wird projektspezifisch festgelegt
";
CM_ SG_ 193 EM2_Max_Moment_Gesamt "Maximal mögliches Moment bei der momentanen Maschinendrehzahl bezogen auf die im System verfügbare elektrische Gesamtleistung MO_EM1_Max_Leistung_Gesamt, motorischer Betrieb";
CM_ SG_ 193 EM2_Max_Moment_Lim "Maximales Moment bei der momentanen Maschinendrehzahl, motorischer Betrieb, berechnet aus Abregelstrom MO_EMx_Max_Strom_Lim und aktueller Spannung";
CM_ SG_ 193 EM2_Min_Moment "minimal darstellbares Moment für eine im Funktionslastenheft definierte Dauer

Die Berechnung der Momentengrenzen wird projektspezifisch festgelegt
";
CM_ SG_ 193 EM2_Min_Moment_Gesamt "Minimal mögliches Moment bei der momentanen Maschinendrehzahl bezogen auf die vom System aufnehmbare elektrische Gesamtleistung MO_EM1_Min_Leistung_Gesamt, generatorischer Betrieb";
CM_ SG_ 193 EM2_Min_Moment_Lim "Minimales Moment bei der momentanen Maschinendrehzahl, generatorischer Betrieb, berechnet aus Abregelstrom MO_EMx_Min_Strom_Lim und aktueller Spannung";
CM_ SG_ 193 EM2_Mom_DrzEingriff "Wirksames Moment der EM zum Begrenzen der Drehzahl auf Drehzahlbegrenzung";
CM_ SG_ 193 EM2_Moment_AR_Eingriff "Momentanwert: Eingriffsmoment der Anti-Ruckel-Funktion im PWR";
CM_ SG_ 193 EM2_Raddrehzahl_links "Momentanwert: Raddrehzahl links (Betrag)

Wird im PWR unter Nutzung der ESC-HW-Schnittstelle (Drehzahlfühler-Ausgänge im ESC) berechnet

Einschränkungen:
1. QM-Signal, kein ASIL möglich
2. Nur Betragswert möglich
3. Nach Stillstand oder Drehrichtun";
CM_ SG_ 193 EM2_Raddrehzahl_rechts "Momentanwert: Raddrehzahl rechts (Betrag)

Wird im PWR unter Nutzung der ESC-HW-Schnittstelle (Drehzahlfühler-Ausgänge im ESC) berechnet

Einschränkungen:
1. QM-Signal, kein ASIL möglich
2. Nur Betragswert möglich
3. Nach Stillstand oder Drehrichtu";
CM_ SG_ 193 EM2_Status_DrzEingriff "Status ASR-Eingriff über EM-Regelung";
CM_ SG_ 193 EM2_Strom_HV "Momentanwert: HV DC-Strom des PWR";

CM_ SG_ 503 EPB_03_BZ "Botschaftszähler";
CM_ SG_ 503 EPB_03_CRC "Für MLB:
'Berechnung siehe Lastenheft 'Kommunikationsabsicherung für FlexRay und CAN''

Ab MQB und MLBevo:
'Berechnung siehe Lastenheft 'End-to-End Kommunikationsabsicherung''

Endwerte siehe Begleitdokument 'S-PDU Kennungsfolgen'
";
CM_ SG_ 503 EPB_Autohold_Standbyanzeige "Ansteuerung der Autohold-Bereitschaftsanzeige im Kombiinstrument";
CM_ SG_ 503 EPB_Autoholdlampe_02 "Autoholdlampe im Kombi, grünes P";
CM_ SG_ 503 EPB_Fehlermeldungen_02 "Über das Signal werden bestimmte Fehlertexte und -lampen im Kombi angefordert.";
CM_ SG_ 503 EPB_Funktionslampe_02 "Bit wird nur gesetzt, wenn volle Spannkraft auf beiden Seiten erreicht. Rote Lampe (rotes P) im Kombiinstrument";
CM_ SG_ 503 EPB_Parkanzeige "Signalisierung der Funktionsaktivierung der Parkbremse. Dient zur Anzeige des Schriftzug „PARK“ im i.ID..";
CM_ SG_ 503 EPB_Texte_02 "EPB-Texte für Kombi
9 bei Audi aktuell nicht bedient.
10 bei Audi hinzugefügt für RSe
11 bei PAG Duo Servo Parkbremse aktuell nicht bedient 
12 bei PAG Duo Servo Parkbremse aktuell nicht bedient";

CM_ SG_ 2527679687 EPS_ASM_Data_1 "Diese Signal wird von mehreren Funktionen auf dem EPS-SG gemäß der ASM-Datendefinition befüllt und an den Assistenzsystemmonitor ASM gesendet";
CM_ SG_ 2527679687 EPS_ASM_Data_2 "Diese Signal wird von mehreren Funktionen auf dem EPS-SG gemäß der ASM-Datendefinition befüllt und an den Assistenzsystemmonitor ASM gesendet";
CM_ SG_ 2527679687 EPS_ASM_Data_3 "Diese Signal wird von mehreren Funktionen auf dem EPS-SG gemäß der ASM-Datendefinition befüllt und an den Assistenzsystemmonitor ASM gesendet";
CM_ SG_ 2527679687 EPS_ASM_Data_4 "Diese Signal wird von mehreren Funktionen auf dem EPS-SG gemäß der ASM-Datendefinition befüllt und an den Assistenzsystemmonitor ASM gesendet";
CM_ SG_ 2527679687 EPS_ASM_Data_5 "Diese Signal wird von mehreren Funktionen auf dem EPS-SG gemäß der ASM-Datendefinition befüllt und an den Assistenzsystemmonitor ASM gesendet";
CM_ SG_ 2527679687 EPS_ASM_Data_6 "Diese Signal wird von mehreren Funktionen auf dem EPS-SG gemäß der ASM-Datendefinition befüllt und an den Assistenzsystemmonitor ASM gesendet";
CM_ SG_ 2527679687 EPS_ASM_Ereignis "Dieses Signal definiert, welche Funktion und welche Art von Aktivität das Senden der Botschaft an den Assistenzsystemmonitor ASM veranlasst hat.";
CM_ SG_ 2527679687 EPS_ASM_Zeitstempel_02 "Zeitstempel der generierten ASM EPS Botschaft";
BA_DEF_REL_ BU_SG_REL_  "GenSigTimeoutTime" INT 0 65535;
BA_DEF_ BO_  "DiagRequest" ENUM "No", "Yes";
BA_DEF_ BO_  "DiagResponse" ENUM "No", "Yes";
BA_DEF_ BO_  "DiagState" ENUM "No", "Yes";
BA_DEF_ BO_  "GenMsgChkConstant" HEX 0 4095;
BA_DEF_ BO_  "GenMsgCycleTime" INT 0 65535;
BA_DEF_ BO_  "GenMsgCycleTimeFast" INT 0 65535;
BA_DEF_ BO_  "GenMsgDelayTime" INT 0 100000;
BA_DEF_ BO_  "GenMsgILSupport" ENUM "No", "Yes";
BA_DEF_ BO_  "GenMsgNrOfRepetition" INT 0 100;
BA_DEF_ BO_  "GenMsgPDUConstants" STRING;
BA_DEF_ BO_  "GenMsgSendType" ENUM "Cyclic", "not_used", "not_used", "not_used", "not_used", "not_used", "not_used", "IfActive", "NoMsgSendType";
BA_DEF_ BO_  "GenMsgStartDelayTime" INT 0 100000;
BA_DEF_ BO_  "NmMessage" ENUM "No", "Yes";
BA_DEF_ BO_  "NmhMessage" ENUM "No", "Yes";
BA_DEF_ BO_  "MsgType" ENUM "Application", "NM ", "NMH", "TP2.0", "ISO-TP ", "BAP", "EID", "KS", "XCP_PRE_CONFIGURED", "XCP_RUNTIME_CONFIGURED";
BA_DEF_ BO_  "VAGTP20_API" HEX 0 255;
BA_DEF_ BO_  "VAGTP20_DynConnection" ENUM "No", "Yes";
BA_DEF_ BO_  "VAGTP20_DynSetup" ENUM "No", "Yes";
BA_DEF_ BO_  "VAGTP20_StatConnection" ENUM "No", "Yes";
BA_DEF_ BO_  "CANFD_BRS" ENUM "0", "1";
BA_DEF_ BO_  "VFrameFormat" ENUM "StandardCAN", "ExtendedCAN", "reserved", "reserved", "reserved", "reserved", "reserved", "reserved", "reserved", "reserved", "reserved", "reserved", "reserved", "reserved", "StandardCAN_FD", "ExtendedCAN_FD";
BA_DEF_ SG_  "GenSigActiveRepetitions" INT -2147483648 2147483647;
BA_DEF_ SG_  "GenSigInactiveValue" INT -2147483648 2147483647;
BA_DEF_ SG_  "GenSigSendType" ENUM "Cyclic", "OnWrite", "OnWriteWithRepetition", "OnChange", "OnChangeWithRepetition", "IfActive", "IfActiveWithRepetition", "NoSigSendType", "OnChangeAndIfActive", "OnChangeAndIfActiveWithRepetition";
BA_DEF_ SG_  "GenSigStartValue" INT -2147483648 2147483647;
BA_DEF_ SG_  "NWM-WakeupAllowed" ENUM "No", "Yes";
BA_DEF_ SG_  "GenSigFuncType" ENUM "NoFunction", "MsgCounter", "CRC-8", "XOR", "XOR-2", "DatedBit", "SW-Kl15", "CHK", "Constant", "Protocol", "CRC-8-SAE_J1850", "CRC-32", "DataLength", "DataID", "MsgCounter16", "SOK-Signatur", "Cluster";
BA_DEF_ SG_  "GenSigSwitchedByIgnition" ENUM "No", "Yes";
BA_DEF_ SG_  "Fehlerwert" HEX 0 2147483647;
BA_DEF_ SG_  "GenSigMissingSourceValue" HEX 0 2147483647;
BA_DEF_DEF_REL_  "GenSigTimeoutTime" 0;
BA_DEF_DEF_  "DiagRequest" "No";
BA_DEF_DEF_  "DiagResponse" "No";
BA_DEF_DEF_  "DiagState" "No";
BA_DEF_DEF_  "GenMsgChkConstant" 0;
BA_DEF_DEF_  "GenMsgCycleTime" 0;
BA_DEF_DEF_  "GenMsgCycleTimeFast" 0;
BA_DEF_DEF_  "GenMsgDelayTime" 0;
BA_DEF_DEF_  "GenMsgILSupport" "No";
BA_DEF_DEF_  "GenMsgNrOfRepetition" 0;
BA_DEF_DEF_  "GenMsgPDUConstants" "";
BA_DEF_DEF_  "GenMsgSendType" "NoMsgSendType";
BA_DEF_DEF_  "GenMsgStartDelayTime" 0;
BA_DEF_DEF_  "NmMessage" "No";
BA_DEF_DEF_  "NmhMessage" "No";
BA_DEF_DEF_  "MsgType" "Application";
BA_DEF_DEF_  "VAGTP20_API" 0;
BA_DEF_DEF_  "VAGTP20_DynConnection" "No";
BA_DEF_DEF_  "VAGTP20_DynSetup" "No";
BA_DEF_DEF_  "VAGTP20_StatConnection" "No";
BA_DEF_DEF_  "CANFD_BRS" "1";
BA_DEF_DEF_  "VFrameFormat" "StandardCAN";
BA_DEF_DEF_  "GenSigActiveRepetitions" 0;
BA_DEF_DEF_  "GenSigInactiveValue" 0;
BA_DEF_DEF_  "GenSigSendType" "NoSigSendType";
BA_DEF_DEF_  "GenSigStartValue" 0;
BA_DEF_DEF_  "NWM-WakeupAllowed" "No";
BA_DEF_DEF_  "GenSigFuncType" "NoFunction";
BA_DEF_DEF_  "GenSigSwitchedByIgnition" "Yes";
BA_DEF_DEF_  "Fehlerwert" 0;
BA_DEF_DEF_  "GenSigMissingSourceValue" 0;
BA_ "GenMsgCycleTime" BO_ 2527679952 200;
BA_ "GenMsgILSupport" BO_ 2527679952 1;
BA_ "GenMsgPDUConstants" BO_ 2527679952 "0x9f,0xce,0x35,0xeb,0x75,0x1d,0xb5,0x1c,0xaf,0x1f,0xbf,0xc4,0x77,0x01,0xe1,0x12";
BA_ "GenMsgSendType" BO_ 2527679952 0;
BA_ "VFrameFormat" BO_ 2527679952 15;
BA_ "GenMsgCycleTime" BO_ 870 1000;
BA_ "GenMsgCycleTimeFast" BO_ 870 50;
BA_ "GenMsgDelayTime" BO_ 870 10;
BA_ "GenMsgILSupport" BO_ 870 1;
BA_ "GenMsgNrOfRepetition" BO_ 870 5;
BA_ "GenMsgPDUConstants" BO_ 870 "0xa9,0xbd,0xfb,0x3c,0x95,0x0f,0x75,0x3a,0x4f,0x19,0x59,0x6d,0xb2,0xe9,0xd1,0x97";
BA_ "GenMsgSendType" BO_ 870 0;
BA_ "VFrameFormat" BO_ 870 14;
BA_ "GenMsgChkConstant" BO_ 903 222;
BA_ "GenMsgCycleTime" BO_ 903 100;
BA_ "GenMsgILSupport" BO_ 903 1;
BA_ "GenMsgPDUConstants" BO_ 903 "0xde,0xde,0xde,0xde,0xde,0xde,0xde,0xde,0xde,0xde,0xde,0xde,0xde,0xde,0xde,0xde";
BA_ "GenMsgSendType" BO_ 903 0;
BA_ "VFrameFormat" BO_ 903 14;
BA_ "MsgType" BO_ 2281471488 6;
BA_ "CANFD_BRS" BO_ 2281471488 0;
BA_ "VFrameFormat" BO_ 2281471488 1;
BA_ "MsgType" BO_ 2281471489 6;
BA_ "CANFD_BRS" BO_ 2281471489 0;
BA_ "VFrameFormat" BO_ 2281471489 1;
BA_ "GenMsgCycleTime" BO_ 2463978646 1000;
BA_ "GenMsgDelayTime" BO_ 2463978646 50;
BA_ "GenMsgILSupport" BO_ 2463978646 1;
BA_ "GenMsgSendType" BO_ 2463978646 0;
BA_ "VFrameFormat" BO_ 2463978646 15;
BA_ "GenMsgCycleTime" BO_ 918 100;
BA_ "GenMsgILSupport" BO_ 918 1;
BA_ "GenMsgSendType" BO_ 918 0;
BA_ "VFrameFormat" BO_ 918 14;
BA_ "GenMsgCycleTime" BO_ 514 20;
BA_ "GenMsgILSupport" BO_ 514 1;
BA_ "GenMsgSendType" BO_ 514 0;
BA_ "VFrameFormat" BO_ 514 14;
BA_ "GenMsgCycleTime" BO_ 2463978758 100;
BA_ "GenMsgILSupport" BO_ 2463978758 1;
BA_ "GenMsgSendType" BO_ 2463978758 0;
BA_ "VFrameFormat" BO_ 2463978758 15;
BA_ "MsgType" BO_ 2617027088 6;
BA_ "VFrameFormat" BO_ 2617027088 15;
BA_ "MsgType" BO_ 2617027072 6;
BA_ "VFrameFormat" BO_ 2617027072 15;
BA_ "MsgType" BO_ 2617027073 6;
BA_ "VFrameFormat" BO_ 2617027073 15;
BA_ "MsgType" BO_ 2617014784 6;
BA_ "CANFD_BRS" BO_ 2617014784 0;
BA_ "VFrameFormat" BO_ 2617014784 1;
BA_ "MsgType" BO_ 2617014785 6;
BA_ "CANFD_BRS" BO_ 2617014785 0;
BA_ "VFrameFormat" BO_ 2617014785 1;
BA_ "MsgType" BO_ 2617014786 6;
BA_ "CANFD_BRS" BO_ 2617014786 0;
BA_ "VFrameFormat" BO_ 2617014786 1;
BA_ "MsgType" BO_ 2617014787 6;
BA_ "CANFD_BRS" BO_ 2617014787 0;
BA_ "VFrameFormat" BO_ 2617014787 1;
BA_ "MsgType" BO_ 2617014788 6;
BA_ "CANFD_BRS" BO_ 2617014788 0;
BA_ "VFrameFormat" BO_ 2617014788 1;
BA_ "MsgType" BO_ 2617014789 6;
BA_ "CANFD_BRS" BO_ 2617014789 0;
BA_ "VFrameFormat" BO_ 2617014789 1;
BA_ "MsgType" BO_ 2617014790 6;
BA_ "CANFD_BRS" BO_ 2617014790 0;
BA_ "VFrameFormat" BO_ 2617014790 1;
BA_ "MsgType" BO_ 2617014791 6;
BA_ "CANFD_BRS" BO_ 2617014791 0;
BA_ "VFrameFormat" BO_ 2617014791 1;
BA_ "MsgType" BO_ 2617217549 6;
BA_ "VFrameFormat" BO_ 2617217549 15;
BA_ "MsgType" BO_ 2617217550 6;
BA_ "VFrameFormat" BO_ 2617217550 15;
BA_ "MsgType" BO_ 2617217551 6;
BA_ "VFrameFormat" BO_ 2617217551 15;
BA_ "MsgType" BO_ 2617217552 6;
BA_ "VFrameFormat" BO_ 2617217552 15;
BA_ "MsgType" BO_ 2617217553 6;
BA_ "VFrameFormat" BO_ 2617217553 15;
BA_ "MsgType" BO_ 2617104905 6;
BA_ "VFrameFormat" BO_ 2617104905 15;
BA_ "MsgType" BO_ 2617104906 6;
BA_ "VFrameFormat" BO_ 2617104906 15;
BA_ "MsgType" BO_ 2617104907 6;
BA_ "VFrameFormat" BO_ 2617104907 15;
BA_ "MsgType" BO_ 2617104908 6;
BA_ "VFrameFormat" BO_ 2617104908 15;
BA_ "MsgType" BO_ 2617104897 6;
BA_ "VFrameFormat" BO_ 2617104897 15;
BA_ "MsgType" BO_ 2617104898 6;
BA_ "VFrameFormat" BO_ 2617104898 15;
BA_ "MsgType" BO_ 2617104899 6;
BA_ "VFrameFormat" BO_ 2617104899 15;
BA_ "MsgType" BO_ 2617104903 6;
BA_ "VFrameFormat" BO_ 2617104903 15;
BA_ "MsgType" BO_ 2617104904 6;
BA_ "VFrameFormat" BO_ 2617104904 15;
BA_ "MsgType" BO_ 2617104909 6;
BA_ "VFrameFormat" BO_ 2617104909 15;
BA_ "MsgType" BO_ 2617152033 6;
BA_ "VFrameFormat" BO_ 2617152033 15;
BA_ "MsgType" BO_ 2617152034 6;
BA_ "VFrameFormat" BO_ 2617152034 15;
BA_ "MsgType" BO_ 2617023022 6;
BA_ "VFrameFormat" BO_ 2617023022 15;
BA_ "MsgType" BO_ 2617023023 6;
BA_ "VFrameFormat" BO_ 2617023023 15;
BA_ "MsgType" BO_ 2617023021 6;
BA_ "VFrameFormat" BO_ 2617023021 15;
BA_ "MsgType" BO_ 2617023008 6;
BA_ "VFrameFormat" BO_ 2617023008 15;
BA_ "MsgType" BO_ 2617023009 6;
BA_ "VFrameFormat" BO_ 2617023009 15;
BA_ "MsgType" BO_ 2617023011 6;
BA_ "VFrameFormat" BO_ 2617023011 15;
BA_ "MsgType" BO_ 2617023012 6;
BA_ "VFrameFormat" BO_ 2617023012 15;
BA_ "MsgType" BO_ 2617023018 6;
BA_ "VFrameFormat" BO_ 2617023018 15;
BA_ "MsgType" BO_ 2617023019 6;
BA_ "VFrameFormat" BO_ 2617023019 15;
BA_ "MsgType" BO_ 2617023014 6;
BA_ "VFrameFormat" BO_ 2617023014 15;
BA_ "MsgType" BO_ 2617023015 6;
BA_ "VFrameFormat" BO_ 2617023015 15;
BA_ "MsgType" BO_ 2617023016 6;
BA_ "VFrameFormat" BO_ 2617023016 15;
BA_ "MsgType" BO_ 2617023013 6;
BA_ "VFrameFormat" BO_ 2617023013 15;
BA_ "MsgType" BO_ 2617023017 6;
BA_ "VFrameFormat" BO_ 2617023017 15;
BA_ "MsgType" BO_ 2617023024 6;
BA_ "VFrameFormat" BO_ 2617023024 15;
BA_ "MsgType" BO_ 2617023026 6;
BA_ "VFrameFormat" BO_ 2617023026 15;
BA_ "MsgType" BO_ 2617020928 6;
BA_ "VFrameFormat" BO_ 2617020928 15;
BA_ "MsgType" BO_ 2617020929 6;
BA_ "VFrameFormat" BO_ 2617020929 15;
BA_ "MsgType" BO_ 2617020930 6;
BA_ "VFrameFormat" BO_ 2617020930 15;
BA_ "MsgType" BO_ 2617020931 6;
BA_ "VFrameFormat" BO_ 2617020931 15;
BA_ "MsgType" BO_ 2617020932 6;
BA_ "VFrameFormat" BO_ 2617020932 15;
BA_ "MsgType" BO_ 2617020933 6;
BA_ "VFrameFormat" BO_ 2617020933 15;
BA_ "MsgType" BO_ 2617020934 6;
BA_ "VFrameFormat" BO_ 2617020934 15;
BA_ "MsgType" BO_ 2617020935 6;
BA_ "VFrameFormat" BO_ 2617020935 15;
BA_ "MsgType" BO_ 2617020936 6;
BA_ "VFrameFormat" BO_ 2617020936 15;
BA_ "MsgType" BO_ 2617020937 6;
BA_ "VFrameFormat" BO_ 2617020937 15;
BA_ "MsgType" BO_ 2617020938 6;
BA_ "VFrameFormat" BO_ 2617020938 15;
BA_ "MsgType" BO_ 2617020939 6;
BA_ "VFrameFormat" BO_ 2617020939 15;
BA_ "MsgType" BO_ 2617020940 6;
BA_ "VFrameFormat" BO_ 2617020940 15;
BA_ "MsgType" BO_ 2617020941 6;
BA_ "VFrameFormat" BO_ 2617020941 15;
BA_ "MsgType" BO_ 2617152080 6;
BA_ "VFrameFormat" BO_ 2617152080 15;
BA_ "DiagRequest" BO_ 2549891590 1;
BA_ "MsgType" BO_ 2549891590 4;
BA_ "VFrameFormat" BO_ 2549891590 15;
BA_ "DiagRequest" BO_ 2621456902 1;
BA_ "MsgType" BO_ 2621456902 4;
BA_ "VFrameFormat" BO_ 2621456902 15;
BA_ "DiagResponse" BO_ 2550022662 1;
BA_ "MsgType" BO_ 2550022662 4;
BA_ "VFrameFormat" BO_ 2550022662 15;
BA_ "DiagResponse" BO_ 2621587974 1;
BA_ "MsgType" BO_ 2621587974 4;
BA_ "VFrameFormat" BO_ 2621587974 15;
BA_ "DiagRequest" BO_ 2549880606 1;
BA_ "MsgType" BO_ 2549880606 4;
BA_ "VFrameFormat" BO_ 2549880606 15;
BA_ "DiagRequest" BO_ 2621445918 1;
BA_ "MsgType" BO_ 2621445918 4;
BA_ "VFrameFormat" BO_ 2621445918 15;
BA_ "DiagResponse" BO_ 2550011678 1;
BA_ "MsgType" BO_ 2550011678 4;
BA_ "VFrameFormat" BO_ 2550011678 15;
BA_ "DiagResponse" BO_ 2621576990 1;
BA_ "MsgType" BO_ 2621576990 4;
BA_ "VFrameFormat" BO_ 2621576990 15;
BA_ "DiagRequest" BO_ 2549880607 1;
BA_ "MsgType" BO_ 2549880607 4;
BA_ "VFrameFormat" BO_ 2549880607 15;
BA_ "DiagRequest" BO_ 2621445919 1;
BA_ "MsgType" BO_ 2621445919 4;
BA_ "VFrameFormat" BO_ 2621445919 15;
BA_ "DiagResponse" BO_ 2550011679 1;
BA_ "MsgType" BO_ 2550011679 4;
BA_ "VFrameFormat" BO_ 2550011679 15;
BA_ "DiagResponse" BO_ 2621576991 1;
BA_ "MsgType" BO_ 2621576991 4;
BA_ "VFrameFormat" BO_ 2621576991 15;
BA_ "DiagRequest" BO_ 2549880362 1;
BA_ "MsgType" BO_ 2549880362 4;
BA_ "VFrameFormat" BO_ 2549880362 15;
BA_ "DiagRequest" BO_ 2621445674 1;
BA_ "MsgType" BO_ 2621445674 4;
BA_ "VFrameFormat" BO_ 2621445674 15;
BA_ "DiagResponse" BO_ 2550011434 1;
BA_ "MsgType" BO_ 2550011434 4;
BA_ "VFrameFormat" BO_ 2550011434 15;
BA_ "DiagResponse" BO_ 2621576746 1;
BA_ "MsgType" BO_ 2621576746 4;
BA_ "VFrameFormat" BO_ 2621576746 15;
BA_ "DiagRequest" BO_ 2549880363 1;
BA_ "MsgType" BO_ 2549880363 4;
BA_ "VFrameFormat" BO_ 2549880363 15;
BA_ "DiagRequest" BO_ 2621445675 1;
BA_ "MsgType" BO_ 2621445675 4;
BA_ "VFrameFormat" BO_ 2621445675 15;
BA_ "DiagResponse" BO_ 2550011435 1;
BA_ "MsgType" BO_ 2550011435 4;
BA_ "VFrameFormat" BO_ 2550011435 15;
BA_ "DiagResponse" BO_ 2621576747 1;
BA_ "MsgType" BO_ 2621576747 4;
BA_ "VFrameFormat" BO_ 2621576747 15;
BA_ "GenMsgCycleTime" BO_ 1714 1000;
BA_ "GenMsgILSupport" BO_ 1714 1;
BA_ "GenMsgSendType" BO_ 1714 0;
BA_ "VFrameFormat" BO_ 1714 14;
BA_ "GenMsgCycleTime" BO_ 1520 200;
BA_ "GenMsgDelayTime" BO_ 1520 50;
BA_ "GenMsgILSupport" BO_ 1520 1;
BA_ "GenMsgSendType" BO_ 1520 0;
BA_ "VFrameFormat" BO_ 1520 14;
BA_ "GenMsgCycleTime" BO_ 331 1000;
BA_ "GenMsgCycleTimeFast" BO_ 331 10;
BA_ "GenMsgILSupport" BO_ 331 1;
BA_ "GenMsgNrOfRepetition" BO_ 331 5;
BA_ "GenMsgSendType" BO_ 331 0;
BA_ "VFrameFormat" BO_ 331 14;
BA_ "GenMsgCycleTime" BO_ 420 500;
BA_ "GenMsgCycleTimeFast" BO_ 420 20;
BA_ "GenMsgDelayTime" BO_ 420 20;
BA_ "GenMsgILSupport" BO_ 420 1;
BA_ "GenMsgNrOfRepetition" BO_ 420 5;
BA_ "GenMsgPDUConstants" BO_ 420 "0x69,0xbb,0x54,0xe6,0x4e,0x46,0x8d,0x7b,0xea,0x87,0xe9,0xb3,0x63,0xce,0xf8,0xbf";
BA_ "GenMsgSendType" BO_ 420 0;
BA_ "VFrameFormat" BO_ 420 14;
BA_ "GenMsgCycleTime" BO_ 496 500;
BA_ "GenMsgDelayTime" BO_ 496 20;
BA_ "GenMsgILSupport" BO_ 496 1;
BA_ "GenMsgPDUConstants" BO_ 496 "0x2f,0x3c,0x22,0x60,0x18,0xeb,0x63,0x76,0xc5,0x91,0x0f,0x27,0x34,0x04,0x7f,0x02";
BA_ "GenMsgSendType" BO_ 496 0;
BA_ "VFrameFormat" BO_ 496 14;
BA_ "GenMsgCycleTime" BO_ 236 10;
BA_ "GenMsgILSupport" BO_ 236 1;
BA_ "GenMsgPDUConstants" BO_ 236 "0xc9,0x33,0x62,0x8a,0xe0,0x01,0x96,0xd5,0x24,0x2f,0xbb,0x40,0xd1,0x5f,0x8d,0xb7";
BA_ "GenMsgSendType" BO_ 236 0;
BA_ "VFrameFormat" BO_ 236 14;
BA_ "GenMsgCycleTime" BO_ 374 20;
BA_ "GenMsgILSupport" BO_ 374 1;
BA_ "GenMsgPDUConstants" BO_ 374 "0x3c,0x60,0xeb,0x76,0x91,0x27,0x04,0x02,0xa4,0x3a,0x3f,0xa8,0x24,0x32,0x38,0x51";
BA_ "GenMsgSendType" BO_ 374 0;
BA_ "VFrameFormat" BO_ 374 14;
BA_ "GenMsgCycleTime" BO_ 2589283963 500;
BA_ "GenMsgILSupport" BO_ 2589283963 1;
BA_ "GenMsgSendType" BO_ 2589283963 0;
BA_ "VFrameFormat" BO_ 2589283963 15;
BA_ "GenMsgCycleTime" BO_ 193 200;
BA_ "GenMsgDelayTime" BO_ 193 20;
BA_ "GenMsgILSupport" BO_ 193 1;
BA_ "GenMsgPDUConstants" BO_ 193 "0xd7,0x12,0x85,0x7e,0x0b,0x34,0xfa,0x16,0x7a,0x25,0x2d,0x8f,0x04,0x8e,0x5d,0x35";
BA_ "GenMsgSendType" BO_ 193 0;
BA_ "VFrameFormat" BO_ 193 14;
BA_ "GenMsgCycleTime" BO_ 503 200;
BA_ "GenMsgDelayTime" BO_ 503 20;
BA_ "GenMsgILSupport" BO_ 503 1;
BA_ "GenMsgPDUConstants" BO_ 503 "0xe7,0x1f,0xa2,0xc2,0x76,0x25,0x1a,0x30,0xb7,0xc8,0xe8,0xe9,0x15,0x28,0x08,0x75";
BA_ "GenMsgSendType" BO_ 503 0;
BA_ "VFrameFormat" BO_ 503 14;
BA_ "GenMsgCycleTime" BO_ 2527679687 2000;
BA_ "GenMsgDelayTime" BO_ 2527679687 100;
BA_ "GenMsgILSupport" BO_ 2527679687 1;
BA_ "GenMsgSendType" BO_ 2527679687 0;
BA_ "VFrameFormat" BO_ 2527679687 15;
BA_ "GenSigSendType" SG_ 2527679952 BFSFo_Position_2_BZ 0;
BA_ "GenSigFuncType" SG_ 2527679952 BFSFo_Position_2_BZ 1;
BA_ "GenSigSwitchedByIgnition" SG_ 2527679952 BFSFo_Position_2_BZ 0;
BA_ "GenSigSendType" SG_ 2527679952 BFSFo_Position_2_CRC 0;
BA_ "GenSigFuncType" SG_ 2527679952 BFSFo_Position_2_CRC 2;
BA_ "GenSigSwitchedByIgnition" SG_ 2527679952 BFSFo_Position_2_CRC 0;
BA_ "GenSigSendType" SG_ 2527679952 HBFSS_Bein_ZielPos_BFSS 0;
BA_ "GenSigSwitchedByIgnition" SG_ 2527679952 HBFSS_Bein_ZielPos_BFSS 0;
BA_ "GenSigSendType" SG_ 2527679952 HBFSS_Hoehe_ZielPos_BFSS 0;
BA_ "GenSigSwitchedByIgnition" SG_ 2527679952 HBFSS_Hoehe_ZielPos_BFSS 0;
BA_ "GenSigSendType" SG_ 2527679952 HBFSS_Laenge_ZielPos_BFSS 0;
BA_ "GenSigSwitchedByIgnition" SG_ 2527679952 HBFSS_Laenge_ZielPos_BFSS 0;
BA_ "GenSigSendType" SG_ 2527679952 HBFSS_Lehne_ZielPos_BFSS 0;
BA_ "GenSigSwitchedByIgnition" SG_ 2527679952 HBFSS_Lehne_ZielPos_BFSS 0;
BA_ "GenSigSendType" SG_ 2527679952 HBFSS_Torso_Pos 0;
BA_ "GenSigSwitchedByIgnition" SG_ 2527679952 HBFSS_Torso_Pos 0;
BA_ "GenSigSendType" SG_ 870 Blinken_li_Fzg_Takt 4;
BA_ "GenSigSwitchedByIgnition" SG_ 870 Blinken_li_Fzg_Takt 0;
BA_ "GenSigSendType" SG_ 870 Blinken_li_Kombi_Takt 4;
BA_ "GenSigSwitchedByIgnition" SG_ 870 Blinken_li_Kombi_Takt 0;
BA_ "GenSigSendType" SG_ 870 Blinken_re_Fzg_Takt 4;
BA_ "GenSigSwitchedByIgnition" SG_ 870 Blinken_re_Fzg_Takt 0;
BA_ "GenSigSendType" SG_ 870 Blinken_re_Kombi_Takt 4;
BA_ "GenSigSwitchedByIgnition" SG_ 870 Blinken_re_Kombi_Takt 0;
BA_ "GenSigSendType" SG_ 870 Blinkmodi_02_BZ 0;
BA_ "GenSigFuncType" SG_ 870 Blinkmodi_02_BZ 1;
BA_ "GenSigSwitchedByIgnition" SG_ 870 Blinkmodi_02_BZ 0;
BA_ "GenSigSendType" SG_ 870 Blinkmodi_02_CRC 0;
BA_ "GenSigFuncType" SG_ 870 Blinkmodi_02_CRC 2;
BA_ "GenSigSwitchedByIgnition" SG_ 870 Blinkmodi_02_CRC 0;
BA_ "GenSigSendType" SG_ 870 BM_Autobahn 4;
BA_ "GenSigSwitchedByIgnition" SG_ 870 BM_Autobahn 0;
BA_ "GenSigSendType" SG_ 870 BM_Crash 4;
BA_ "GenSigSwitchedByIgnition" SG_ 870 BM_Crash 0;
BA_ "GenSigSendType" SG_ 870 BM_DWA_Alarm 4;
BA_ "GenSigSwitchedByIgnition" SG_ 870 BM_DWA_Alarm 0;
BA_ "GenSigSendType" SG_ 870 BM_DWA_ein 4;
BA_ "GenSigSwitchedByIgnition" SG_ 870 BM_DWA_ein 0;
BA_ "GenSigSendType" SG_ 870 BM_GDO 4;
BA_ "GenSigSwitchedByIgnition" SG_ 870 BM_GDO 0;
BA_ "GenSigSendType" SG_ 870 BM_HD_Oeffnung_angelernt 3;
BA_ "GenSigSwitchedByIgnition" SG_ 870 BM_HD_Oeffnung_angelernt 0;
BA_ "GenSigSendType" SG_ 870 BM_links 4;
BA_ "GenSigSwitchedByIgnition" SG_ 870 BM_links 0;
BA_ "GenSigSendType" SG_ 870 BM_NBA_n_codiert_n_aktiv 3;
BA_ "GenSigStartValue" SG_ 870 BM_NBA_n_codiert_n_aktiv 1;
BA_ "GenSigSwitchedByIgnition" SG_ 870 BM_NBA_n_codiert_n_aktiv 0;
BA_ "GenSigSendType" SG_ 870 BM_NBA_Status 4;
BA_ "GenSigSwitchedByIgnition" SG_ 870 BM_NBA_Status 0;
BA_ "GenSigSendType" SG_ 870 BM_Not_Bremsung 4;
BA_ "GenSigSwitchedByIgnition" SG_ 870 BM_Not_Bremsung 0;
BA_ "GenSigSendType" SG_ 870 BM_Panik 4;
BA_ "GenSigSwitchedByIgnition" SG_ 870 BM_Panik 0;
BA_ "GenSigSendType" SG_ 870 BM_PiloPa 4;
BA_ "GenSigSwitchedByIgnition" SG_ 870 BM_PiloPa 0;
BA_ "GenSigSendType" SG_ 870 BM_Recas 5;
BA_ "GenSigSwitchedByIgnition" SG_ 870 BM_Recas 0;
BA_ "GenSigSendType" SG_ 870 BM_rechts 4;
BA_ "GenSigSwitchedByIgnition" SG_ 870 BM_rechts 0;
BA_ "GenSigSendType" SG_ 870 BM_Rollenmodus_Blinken 5;
BA_ "GenSigSwitchedByIgnition" SG_ 870 BM_Rollenmodus_Blinken 0;
BA_ "GenSigSendType" SG_ 870 BM_Taxi_Notalarm 4;
BA_ "GenSigSwitchedByIgnition" SG_ 870 BM_Taxi_Notalarm 0;
BA_ "GenSigSendType" SG_ 870 BM_Telematik 4;
BA_ "GenSigSwitchedByIgnition" SG_ 870 BM_Telematik 0;
BA_ "GenSigSendType" SG_ 870 BM_Telematik_Abbruchgrund 4;
BA_ "GenSigSwitchedByIgnition" SG_ 870 BM_Telematik_Abbruchgrund 0;
BA_ "GenSigSendType" SG_ 870 BM_Warnblinken 4;
BA_ "GenSigSwitchedByIgnition" SG_ 870 BM_Warnblinken 0;
BA_ "GenSigSendType" SG_ 870 BM_WBA_Warnblinken 4;
BA_ "GenSigSwitchedByIgnition" SG_ 870 BM_WBA_Warnblinken 0;
BA_ "GenSigSendType" SG_ 870 BM_WBT_Beleuchtung 3;
BA_ "GenSigSwitchedByIgnition" SG_ 870 BM_WBT_Beleuchtung 0;
BA_ "GenSigSendType" SG_ 870 BM_Wischblinken 4;
BA_ "GenSigSwitchedByIgnition" SG_ 870 BM_Wischblinken 0;
BA_ "GenSigSendType" SG_ 870 BM_ZV_auf 4;
BA_ "GenSigSwitchedByIgnition" SG_ 870 BM_ZV_auf 0;
BA_ "GenSigSendType" SG_ 870 BM_ZV_zu 4;
BA_ "GenSigSwitchedByIgnition" SG_ 870 BM_ZV_zu 0;
BA_ "GenSigSendType" SG_ 870 SAL_RHP_Blinken_Status 3;
BA_ "GenSigSwitchedByIgnition" SG_ 870 SAL_RHP_Blinken_Status 0;
BA_ "GenSigSendType" SG_ 870 SAL_RHP_Warnblinken 3;
BA_ "GenSigSwitchedByIgnition" SG_ 870 SAL_RHP_Warnblinken 0;
BA_ "GenSigSendType" SG_ 870 SAL_TA_Blinken_Status 4;
BA_ "GenSigSwitchedByIgnition" SG_ 870 SAL_TA_Blinken_Status 0;
BA_ "GenSigSendType" SG_ 903 Bremse_EV_02_BZ 0;
BA_ "GenSigFuncType" SG_ 903 Bremse_EV_02_BZ 1;
BA_ "GenSigSwitchedByIgnition" SG_ 903 Bremse_EV_02_BZ 0;
BA_ "GenSigSendType" SG_ 903 Bremse_EV_02_CRC 0;
BA_ "GenSigFuncType" SG_ 903 Bremse_EV_02_CRC 2;
BA_ "GenSigSwitchedByIgnition" SG_ 903 Bremse_EV_02_CRC 0;
BA_ "GenSigSendType" SG_ 903 EBKV_BKL_Warnungen 0;
BA_ "GenSigSwitchedByIgnition" SG_ 903 EBKV_BKL_Warnungen 0;
BA_ "GenSigSendType" SG_ 903 EBKV_Charisma_FahrPr 0;
BA_ "GenSigSwitchedByIgnition" SG_ 903 EBKV_Charisma_FahrPr 0;
BA_ "GenSigSendType" SG_ 903 EBKV_Charisma_Status 0;
BA_ "GenSigSwitchedByIgnition" SG_ 903 EBKV_Charisma_Status 0;
BA_ "GenSigSendType" SG_ 903 EBKV_Hinweise 0;
BA_ "GenSigSwitchedByIgnition" SG_ 903 EBKV_Hinweise 0;
BA_ "GenSigSendType" SG_ 903 EBKV_SpannungsAnf 0;
BA_ "GenSigSwitchedByIgnition" SG_ 903 EBKV_SpannungsAnf 0;
BA_ "GenSigSendType" SG_ 903 EBKV_Warnungen 0;
BA_ "GenSigSwitchedByIgnition" SG_ 903 EBKV_Warnungen 0;
BA_ "GenSigSendType" SG_ 903 EPB_Fehlermeldung_ext 0;
BA_ "GenSigSwitchedByIgnition" SG_ 903 EPB_Fehlermeldung_ext 0;
BA_ "GenSigSendType" SG_ 903 EPB_Funktionslampe_ext 0;
BA_ "GenSigSwitchedByIgnition" SG_ 903 EPB_Funktionslampe_ext 0;
BA_ "GenSigFuncType" SG_ 2281471488 CCP_Allrad_CRO_01_Data 9;
BA_ "GenSigSwitchedByIgnition" SG_ 2281471488 CCP_Allrad_CRO_01_Data 0;
BA_ "GenSigFuncType" SG_ 2281471489 CCP_Allrad_DTO_01_Data 9;
BA_ "GenSigSwitchedByIgnition" SG_ 2281471489 CCP_Allrad_DTO_01_Data 0;
BA_ "GenSigSendType" SG_ 2463978646 CHA_Current_Mode 3;
BA_ "GenSigSwitchedByIgnition" SG_ 2463978646 CHA_Current_Mode 0;
BA_ "GenSigSendType" SG_ 2463978646 CHA_Fahrer_Umschaltung 3;
BA_ "GenSigSwitchedByIgnition" SG_ 2463978646 CHA_Fahrer_Umschaltung 0;
BA_ "GenSigSendType" SG_ 2463978646 CHA_Fahrer_Umschaltung_BMA 3;
BA_ "GenSigSwitchedByIgnition" SG_ 2463978646 CHA_Fahrer_Umschaltung_BMA 0;
BA_ "GenSigSendType" SG_ 2463978646 CHA_Ziel_FahrPr_ACC 3;
BA_ "GenSigSwitchedByIgnition" SG_ 2463978646 CHA_Ziel_FahrPr_ACC 0;
BA_ "GenSigSendType" SG_ 2463978646 CHA_Ziel_FahrPr_AEB 3;
BA_ "GenSigSwitchedByIgnition" SG_ 2463978646 CHA_Ziel_FahrPr_AEB 0;
BA_ "GenSigSendType" SG_ 2463978646 CHA_Ziel_FahrPr_AFR 3;
BA_ "GenSigSwitchedByIgnition" SG_ 2463978646 CHA_Ziel_FahrPr_AFR 0;
BA_ "GenSigSendType" SG_ 2463978646 CHA_Ziel_FahrPr_AFS 3;
BA_ "GenSigSwitchedByIgnition" SG_ 2463978646 CHA_Ziel_FahrPr_AFS 0;
BA_ "GenSigSendType" SG_ 2463978646 CHA_Ziel_FahrPr_AGA 3;
BA_ "GenSigSwitchedByIgnition" SG_ 2463978646 CHA_Ziel_FahrPr_AGA 0;
BA_ "GenSigSendType" SG_ 2463978646 CHA_Ziel_FahrPr_AGK 3;
BA_ "GenSigSwitchedByIgnition" SG_ 2463978646 CHA_Ziel_FahrPr_AGK 0;
BA_ "GenSigSendType" SG_ 2463978646 CHA_Ziel_FahrPr_ALR 3;
BA_ "GenSigSwitchedByIgnition" SG_ 2463978646 CHA_Ziel_FahrPr_ALR 0;
BA_ "GenSigSendType" SG_ 2463978646 CHA_Ziel_FahrPr_AV 3;
BA_ "GenSigSwitchedByIgnition" SG_ 2463978646 CHA_Ziel_FahrPr_AV 0;
BA_ "GenSigSendType" SG_ 2463978646 CHA_Ziel_FahrPr_BMS 3;
BA_ "GenSigSwitchedByIgnition" SG_ 2463978646 CHA_Ziel_FahrPr_BMS 0;
BA_ "GenSigSendType" SG_ 2463978646 CHA_Ziel_FahrPr_DR 3;
BA_ "GenSigSwitchedByIgnition" SG_ 2463978646 CHA_Ziel_FahrPr_DR 0;
BA_ "GenSigSendType" SG_ 2463978646 CHA_Ziel_FahrPr_EAR 3;
BA_ "GenSigSwitchedByIgnition" SG_ 2463978646 CHA_Ziel_FahrPr_EAR 0;
BA_ "GenSigSendType" SG_ 2463978646 CHA_Ziel_FahrPr_EBKV 3;
BA_ "GenSigSwitchedByIgnition" SG_ 2463978646 CHA_Ziel_FahrPr_EBKV 0;
BA_ "GenSigSendType" SG_ 2463978646 CHA_Ziel_FahrPr_EDS 3;
BA_ "GenSigSwitchedByIgnition" SG_ 2463978646 CHA_Ziel_FahrPr_EDS 0;
BA_ "GenSigSendType" SG_ 2463978646 CHA_Ziel_FahrPr_EPS 3;
BA_ "GenSigSwitchedByIgnition" SG_ 2463978646 CHA_Ziel_FahrPr_EPS 0;
BA_ "GenSigSendType" SG_ 2463978646 CHA_Ziel_FahrPr_eSound 3;
BA_ "GenSigSwitchedByIgnition" SG_ 2463978646 CHA_Ziel_FahrPr_eSound 0;
BA_ "GenSigSendType" SG_ 2463978646 CHA_Ziel_FahrPr_ESP 3;
BA_ "GenSigSwitchedByIgnition" SG_ 2463978646 CHA_Ziel_FahrPr_ESP 0;
BA_ "GenSigSendType" SG_ 2463978646 CHA_Ziel_FahrPr_FCWO 3;
BA_ "GenSigSwitchedByIgnition" SG_ 2463978646 CHA_Ziel_FahrPr_FCWO 0;
BA_ "GenSigSendType" SG_ 2463978646 CHA_Ziel_FahrPr_FCWP 3;
BA_ "GenSigSwitchedByIgnition" SG_ 2463978646 CHA_Ziel_FahrPr_FCWP 0;
BA_ "GenSigSendType" SG_ 2463978646 CHA_Ziel_FahrPr_Freilauf 3;
BA_ "GenSigSwitchedByIgnition" SG_ 2463978646 CHA_Ziel_FahrPr_Freilauf 0;
BA_ "GenSigSendType" SG_ 2463978646 CHA_Ziel_FahrPr_GE 3;
BA_ "GenSigSwitchedByIgnition" SG_ 2463978646 CHA_Ziel_FahrPr_GE 0;
BA_ "GenSigSendType" SG_ 2463978646 CHA_Ziel_FahrPr_HAL 3;
BA_ "GenSigSwitchedByIgnition" SG_ 2463978646 CHA_Ziel_FahrPr_HAL 0;
BA_ "GenSigSendType" SG_ 2463978646 CHA_Ziel_FahrPr_HDC 3;
BA_ "GenSigSwitchedByIgnition" SG_ 2463978646 CHA_Ziel_FahrPr_HDC 0;
BA_ "GenSigSendType" SG_ 2463978646 CHA_Ziel_FahrPr_HHC 3;
BA_ "GenSigSwitchedByIgnition" SG_ 2463978646 CHA_Ziel_FahrPr_HHC 0;
BA_ "GenSigSendType" SG_ 2463978646 CHA_Ziel_FahrPr_IL 3;
BA_ "GenSigSwitchedByIgnition" SG_ 2463978646 CHA_Ziel_FahrPr_IL 0;
BA_ "GenSigSendType" SG_ 2463978646 CHA_Ziel_FahrPr_mFDR 3;
BA_ "GenSigSwitchedByIgnition" SG_ 2463978646 CHA_Ziel_FahrPr_mFDR 0;
BA_ "GenSigSendType" SG_ 2463978646 CHA_Ziel_FahrPr_MO 3;
BA_ "GenSigSwitchedByIgnition" SG_ 2463978646 CHA_Ziel_FahrPr_MO 0;
BA_ "GenSigSendType" SG_ 2463978646 CHA_Ziel_FahrPr_MO_BZS 3;
BA_ "GenSigSwitchedByIgnition" SG_ 2463978646 CHA_Ziel_FahrPr_MO_BZS 0;
BA_ "GenSigSendType" SG_ 2463978646 CHA_Ziel_FahrPr_MO_Freilauf 3;
BA_ "GenSigSwitchedByIgnition" SG_ 2463978646 CHA_Ziel_FahrPr_MO_Freilauf 0;
BA_ "GenSigSendType" SG_ 2463978646 CHA_Ziel_FahrPr_MO_StSt 3;
BA_ "GenSigSwitchedByIgnition" SG_ 2463978646 CHA_Ziel_FahrPr_MO_StSt 0;
BA_ "GenSigSendType" SG_ 2463978646 CHA_Ziel_FahrPr_MXB 3;
BA_ "GenSigSwitchedByIgnition" SG_ 2463978646 CHA_Ziel_FahrPr_MXB 0;
BA_ "GenSigSendType" SG_ 2463978646 CHA_Ziel_FahrPr_NR 3;
BA_ "GenSigSwitchedByIgnition" SG_ 2463978646 CHA_Ziel_FahrPr_NR 0;
BA_ "GenSigSendType" SG_ 2463978646 CHA_Ziel_FahrPr_PACC 3;
BA_ "GenSigSwitchedByIgnition" SG_ 2463978646 CHA_Ziel_FahrPr_PACC 0;
BA_ "GenSigSendType" SG_ 2463978646 CHA_Ziel_FahrPr_PDC 3;
BA_ "GenSigSwitchedByIgnition" SG_ 2463978646 CHA_Ziel_FahrPr_PDC 0;
BA_ "GenSigSendType" SG_ 2463978646 CHA_Ziel_FahrPr_PreCrash 3;
BA_ "GenSigSwitchedByIgnition" SG_ 2463978646 CHA_Ziel_FahrPr_PreCrash 0;
BA_ "GenSigSendType" SG_ 2463978646 CHA_Ziel_FahrPr_QS 3;
BA_ "GenSigSwitchedByIgnition" SG_ 2463978646 CHA_Ziel_FahrPr_QS 0;
BA_ "GenSigSendType" SG_ 2463978646 CHA_Ziel_FahrPr_Reku_ZwGas 3;
BA_ "GenSigSwitchedByIgnition" SG_ 2463978646 CHA_Ziel_FahrPr_Reku_ZwGas 0;
BA_ "GenSigSendType" SG_ 2463978646 CHA_Ziel_FahrPr_RHP 3;
BA_ "GenSigSwitchedByIgnition" SG_ 2463978646 CHA_Ziel_FahrPr_RHP 0;
BA_ "GenSigSendType" SG_ 2463978646 CHA_Ziel_FahrPr_SAK 3;
BA_ "GenSigSwitchedByIgnition" SG_ 2463978646 CHA_Ziel_FahrPr_SAK 0;
BA_ "GenSigSendType" SG_ 2463978646 CHA_Ziel_FahrPr_SCU 3;
BA_ "GenSigSwitchedByIgnition" SG_ 2463978646 CHA_Ziel_FahrPr_SCU 0;
BA_ "GenSigSendType" SG_ 2463978646 CHA_Ziel_FahrPr_ToS_laengs 3;
BA_ "GenSigSwitchedByIgnition" SG_ 2463978646 CHA_Ziel_FahrPr_ToS_laengs 0;
BA_ "GenSigSendType" SG_ 2463978646 CHA_Ziel_FahrPr_ToS_quer 3;
BA_ "GenSigSwitchedByIgnition" SG_ 2463978646 CHA_Ziel_FahrPr_ToS_quer 0;
BA_ "GenSigSendType" SG_ 2463978646 CHA_Ziel_FahrPr_VAQ 3;
BA_ "GenSigSwitchedByIgnition" SG_ 2463978646 CHA_Ziel_FahrPr_VAQ 0;
BA_ "GenSigSendType" SG_ 918 DR_Gelbe_Warnlampe 0;
BA_ "GenSigSendType" SG_ 514 DR_Aufbaubeschleunigung_HL 0;
BA_ "GenSigStartValue" SG_ 514 DR_Aufbaubeschleunigung_HL 1022;
BA_ "GenSigSwitchedByIgnition" SG_ 514 DR_Aufbaubeschleunigung_HL 0;
BA_ "Fehlerwert" SG_ 514 DR_Aufbaubeschleunigung_HL 1023;
BA_ "GenSigSendType" SG_ 514 DR_Aufbaubeschleunigung_HR 0;
BA_ "GenSigStartValue" SG_ 514 DR_Aufbaubeschleunigung_HR 1022;
BA_ "GenSigSwitchedByIgnition" SG_ 514 DR_Aufbaubeschleunigung_HR 0;
BA_ "Fehlerwert" SG_ 514 DR_Aufbaubeschleunigung_HR 1023;
BA_ "GenSigSendType" SG_ 514 DR_Aufbaubeschleunigung_VL 0;
BA_ "GenSigStartValue" SG_ 514 DR_Aufbaubeschleunigung_VL 1022;
BA_ "GenSigSwitchedByIgnition" SG_ 514 DR_Aufbaubeschleunigung_VL 0;
BA_ "Fehlerwert" SG_ 514 DR_Aufbaubeschleunigung_VL 1023;
BA_ "GenSigSendType" SG_ 514 DR_Aufbaubeschleunigung_VR 0;
BA_ "GenSigStartValue" SG_ 514 DR_Aufbaubeschleunigung_VR 1022;
BA_ "GenSigSwitchedByIgnition" SG_ 514 DR_Aufbaubeschleunigung_VR 0;
BA_ "Fehlerwert" SG_ 514 DR_Aufbaubeschleunigung_VR 1023;
BA_ "GenSigSendType" SG_ 514 DR_Daempferweg_HL 0;
BA_ "GenSigStartValue" SG_ 514 DR_Daempferweg_HL 4094;
BA_ "GenSigSwitchedByIgnition" SG_ 514 DR_Daempferweg_HL 0;
BA_ "Fehlerwert" SG_ 514 DR_Daempferweg_HL 4095;
BA_ "GenSigSendType" SG_ 514 DR_Daempferweg_HR 0;
BA_ "GenSigStartValue" SG_ 514 DR_Daempferweg_HR 4094;
BA_ "GenSigSwitchedByIgnition" SG_ 514 DR_Daempferweg_HR 0;
BA_ "Fehlerwert" SG_ 514 DR_Daempferweg_HR 4095;
BA_ "GenSigSendType" SG_ 514 DR_Daempferweg_VL 0;
BA_ "GenSigStartValue" SG_ 514 DR_Daempferweg_VL 4094;
BA_ "GenSigSwitchedByIgnition" SG_ 514 DR_Daempferweg_VL 0;
BA_ "Fehlerwert" SG_ 514 DR_Daempferweg_VL 4095;
BA_ "GenSigSendType" SG_ 514 DR_Daempferweg_VR 0;
BA_ "GenSigStartValue" SG_ 514 DR_Daempferweg_VR 4094;
BA_ "GenSigSwitchedByIgnition" SG_ 514 DR_Daempferweg_VR 0;
BA_ "Fehlerwert" SG_ 514 DR_Daempferweg_VR 4095;
BA_ "GenSigSendType" SG_ 514 DR_Drehwinkel_HL 0;
BA_ "GenSigStartValue" SG_ 514 DR_Drehwinkel_HL 4094;
BA_ "GenSigSwitchedByIgnition" SG_ 514 DR_Drehwinkel_HL 0;
BA_ "Fehlerwert" SG_ 514 DR_Drehwinkel_HL 4095;
BA_ "GenSigSendType" SG_ 514 DR_Drehwinkel_HR 0;
BA_ "GenSigStartValue" SG_ 514 DR_Drehwinkel_HR 4094;
BA_ "GenSigSwitchedByIgnition" SG_ 514 DR_Drehwinkel_HR 0;
BA_ "Fehlerwert" SG_ 514 DR_Drehwinkel_HR 4095;
BA_ "GenSigSendType" SG_ 514 DR_Drehwinkel_VL 0;
BA_ "GenSigStartValue" SG_ 514 DR_Drehwinkel_VL 4094;
BA_ "GenSigSwitchedByIgnition" SG_ 514 DR_Drehwinkel_VL 0;
BA_ "Fehlerwert" SG_ 514 DR_Drehwinkel_VL 4095;
BA_ "GenSigSendType" SG_ 514 DR_Drehwinkel_VR 0;
BA_ "GenSigStartValue" SG_ 514 DR_Drehwinkel_VR 4094;
BA_ "GenSigSwitchedByIgnition" SG_ 514 DR_Drehwinkel_VR 0;
BA_ "Fehlerwert" SG_ 514 DR_Drehwinkel_VR 4095;
BA_ "GenSigSendType" SG_ 514 DR_Drehwinkelsensortausch_HL 0;
BA_ "GenSigSwitchedByIgnition" SG_ 514 DR_Drehwinkelsensortausch_HL 0;
BA_ "GenSigSendType" SG_ 514 DR_Drehwinkelsensortausch_HR 0;
BA_ "GenSigSwitchedByIgnition" SG_ 514 DR_Drehwinkelsensortausch_HR 0;
BA_ "GenSigSendType" SG_ 514 DR_Drehwinkelsensortausch_VL 0;
BA_ "GenSigSwitchedByIgnition" SG_ 514 DR_Drehwinkelsensortausch_VL 0;
BA_ "GenSigSendType" SG_ 514 DR_Drehwinkelsensortausch_VR 0;
BA_ "GenSigSwitchedByIgnition" SG_ 514 DR_Drehwinkelsensortausch_VR 0;
BA_ "GenSigSendType" SG_ 514 DR_Funktionsstatus 0;
BA_ "GenSigSwitchedByIgnition" SG_ 514 DR_Funktionsstatus 0;
BA_ "GenSigSendType" SG_ 2463978758 DR_DCCMonitor_I_Add 0;
BA_ "GenSigSwitchedByIgnition" SG_ 2463978758 DR_DCCMonitor_I_Add 0;
BA_ "GenSigSendType" SG_ 2463978758 DR_DCCMonitor_I_HL 0;
BA_ "GenSigSwitchedByIgnition" SG_ 2463978758 DR_DCCMonitor_I_HL 0;
BA_ "GenSigSendType" SG_ 2463978758 DR_DCCMonitor_I_HR 0;
BA_ "GenSigSwitchedByIgnition" SG_ 2463978758 DR_DCCMonitor_I_HR 0;
BA_ "GenSigSendType" SG_ 2463978758 DR_DCCMonitor_I_SZ_Add 0;
BA_ "GenSigSwitchedByIgnition" SG_ 2463978758 DR_DCCMonitor_I_SZ_Add 0;
BA_ "GenSigSendType" SG_ 2463978758 DR_DCCMonitor_I_SZ_HL 0;
BA_ "GenSigSwitchedByIgnition" SG_ 2463978758 DR_DCCMonitor_I_SZ_HL 0;
BA_ "GenSigSendType" SG_ 2463978758 DR_DCCMonitor_I_SZ_HR 0;
BA_ "GenSigSwitchedByIgnition" SG_ 2463978758 DR_DCCMonitor_I_SZ_HR 0;
BA_ "GenSigSendType" SG_ 2463978758 DR_DCCMonitor_I_SZ_VL 0;
BA_ "GenSigSwitchedByIgnition" SG_ 2463978758 DR_DCCMonitor_I_SZ_VL 0;
BA_ "GenSigSendType" SG_ 2463978758 DR_DCCMonitor_I_SZ_VR 0;
BA_ "GenSigSwitchedByIgnition" SG_ 2463978758 DR_DCCMonitor_I_SZ_VR 0;
BA_ "GenSigSendType" SG_ 2463978758 DR_DCCMonitor_I_VL 0;
BA_ "GenSigSwitchedByIgnition" SG_ 2463978758 DR_DCCMonitor_I_VL 0;
BA_ "GenSigSendType" SG_ 2463978758 DR_DCCMonitor_I_VR 0;
BA_ "GenSigSwitchedByIgnition" SG_ 2463978758 DR_DCCMonitor_I_VR 0;
BA_ "GenSigSwitchedByIgnition" SG_ 2617027088 DEV_Airbag_ASM_01_Data 0;
BA_ "GenSigSwitchedByIgnition" SG_ 2617027072 DEV_Airbag_Resp_00_Data_FD 0;
BA_ "GenSigSwitchedByIgnition" SG_ 2617027073 DEV_Airbag_Resp_01_Data_FD 0;
BA_ "GenSigSwitchedByIgnition" SG_ 2617014784 DEV_Allrad_Req_00_Data 0;
BA_ "GenSigSwitchedByIgnition" SG_ 2617014785 DEV_Allrad_Resp_01_Data 0;
BA_ "GenSigSwitchedByIgnition" SG_ 2617014786 DEV_Allrad_Resp_02_Data 0;
BA_ "GenSigSwitchedByIgnition" SG_ 2617014787 DEV_Allrad_Resp_03_Data 0;
BA_ "GenSigSwitchedByIgnition" SG_ 2617014788 DEV_Allrad_Resp_04_Data 0;
BA_ "GenSigSwitchedByIgnition" SG_ 2617014789 DEV_Allrad_Resp_05_Data 0;
BA_ "GenSigSwitchedByIgnition" SG_ 2617014790 DEV_Allrad_Resp_06_Data 0;
BA_ "GenSigSwitchedByIgnition" SG_ 2617014791 DEV_Allrad_Resp_07_Data 0;
BA_ "GenSigSwitchedByIgnition" SG_ 2617217549 DEV_Daempfer_Req_13_Data 0;
BA_ "GenSigSwitchedByIgnition" SG_ 2617217550 DEV_Daempfer_Req_14_Data 0;
BA_ "GenSigSwitchedByIgnition" SG_ 2617217551 DEV_Daempfer_Resp_15_Data 0;
BA_ "GenSigSwitchedByIgnition" SG_ 2617217552 DEV_Daempfer_Resp_16_Data 0;
BA_ "GenSigSwitchedByIgnition" SG_ 2617217553 DEV_Daempfer_Resp_17_Data 0;
BA_ "GenSigSwitchedByIgnition" SG_ 2617104905 DEV_EBKV_Resp_00_Data 0;
BA_ "GenSigSwitchedByIgnition" SG_ 2617104906 DEV_EBKV_Resp_01_Data 0;
BA_ "GenSigSwitchedByIgnition" SG_ 2617104907 DEV_EBKV_Resp_03_Data 0;
BA_ "GenSigSwitchedByIgnition" SG_ 2617104908 DEV_EBKV_Resp_04_Data 0;
BA_ "GenSigSwitchedByIgnition" SG_ 2617104897 DEV_EBKV_Resp_05_Data 0;
BA_ "GenSigSwitchedByIgnition" SG_ 2617104898 DEV_EBKV_Resp_06_Data 0;
BA_ "GenSigSwitchedByIgnition" SG_ 2617104899 DEV_EBKV_Resp_07_Data 0;
BA_ "GenSigSwitchedByIgnition" SG_ 2617104903 DEV_EBKV_Resp_08_Data 0;
BA_ "GenSigSwitchedByIgnition" SG_ 2617104904 DEV_EBKV_Resp_09_Data 0;
BA_ "GenSigSwitchedByIgnition" SG_ 2617104909 DEV_EBKV_Resp_10_Data 0;
BA_ "GenSigSwitchedByIgnition" SG_ 2617152033 DEV_EPB_Resp_01_Data 0;
BA_ "GenSigSwitchedByIgnition" SG_ 2617152034 DEV_EPB_Resp_02_Data 0;
BA_ "GenSigSwitchedByIgnition" SG_ 2617023022 DEV_ESC_Req_01_Data 0;
BA_ "GenSigSwitchedByIgnition" SG_ 2617023023 DEV_ESC_Req_02_Data 0;
BA_ "GenSigSwitchedByIgnition" SG_ 2617023021 DEV_ESC_Req_03_Data 0;
BA_ "GenSigSwitchedByIgnition" SG_ 2617023008 DEV_ESC_Resp_00_Data 0;
BA_ "GenSigSwitchedByIgnition" SG_ 2617023009 DEV_ESC_Resp_01_Data 0;
BA_ "GenSigSwitchedByIgnition" SG_ 2617023011 DEV_ESC_Resp_03_Data 0;
BA_ "GenSigSwitchedByIgnition" SG_ 2617023012 DEV_ESC_Resp_04_Data 0;
BA_ "GenSigSwitchedByIgnition" SG_ 2617023018 DEV_ESC_Resp_05_Data 0;
BA_ "GenSigSwitchedByIgnition" SG_ 2617023019 DEV_ESC_Resp_06_Data 0;
BA_ "GenSigSwitchedByIgnition" SG_ 2617023014 DEV_ESC_Resp_07_Data 0;
BA_ "GenSigSwitchedByIgnition" SG_ 2617023015 DEV_ESC_Resp_08_Data 0;
BA_ "GenSigSwitchedByIgnition" SG_ 2617023016 DEV_ESC_Resp_09_Data 0;
BA_ "GenSigSwitchedByIgnition" SG_ 2617023013 DEV_ESC_Resp_10_Data 0;
BA_ "GenSigSwitchedByIgnition" SG_ 2617023017 DEV_ESC_Resp_11_Data 0;
BA_ "GenSigSwitchedByIgnition" SG_ 2617023024 DEV_ESC_Resp_12_Data 0;
BA_ "GenSigSwitchedByIgnition" SG_ 2617023026 DEV_ESC_Resp_13_Data 0;
BA_ "GenSigSwitchedByIgnition" SG_ 2617020928 DEV_Lenkhilfe_Resp_00_Data 0;
BA_ "GenSigSwitchedByIgnition" SG_ 2617020929 DEV_Lenkhilfe_Resp_01_Data 0;
BA_ "GenSigSwitchedByIgnition" SG_ 2617020930 DEV_Lenkhilfe_Resp_02_Data 0;
BA_ "GenSigSwitchedByIgnition" SG_ 2617020931 DEV_Lenkhilfe_Resp_03_Data 0;
BA_ "GenSigSwitchedByIgnition" SG_ 2617020932 DEV_Lenkhilfe_Resp_04_Data 0;
BA_ "GenSigSwitchedByIgnition" SG_ 2617020933 DEV_Lenkhilfe_Resp_05_Data 0;
BA_ "GenSigSwitchedByIgnition" SG_ 2617020934 DEV_Lenkhilfe_Resp_06_Data 0;
BA_ "GenSigSwitchedByIgnition" SG_ 2617020935 DEV_Lenkhilfe_Resp_07_Data 0;
BA_ "GenSigSwitchedByIgnition" SG_ 2617020936 DEV_Lenkhilfe_Resp_08_Data 0;
BA_ "GenSigSwitchedByIgnition" SG_ 2617020937 DEV_Lenkhilfe_Resp_09_Data 0;
BA_ "GenSigSwitchedByIgnition" SG_ 2617020938 DEV_Lenkhilfe_Resp_10_Data 0;
BA_ "GenSigSwitchedByIgnition" SG_ 2617020939 DEV_Lenkhilfe_Resp_11_Data 0;
BA_ "GenSigSwitchedByIgnition" SG_ 2617020940 DEV_Lenkhilfe_Resp_12_Data 0;
BA_ "GenSigSwitchedByIgnition" SG_ 2617020941 DEV_Lenkhilfe_Resp_13_Data 0;
BA_ "GenSigSwitchedByIgnition" SG_ 2617152080 DEV_PBC_Resp_01_Data 0;
BA_ "GenSigSendType" SG_ 2549891590 DIA_eCS_Req_Data 3;
BA_ "GenSigFuncType" SG_ 2549891590 DIA_eCS_Req_Data 9;
BA_ "GenSigSwitchedByIgnition" SG_ 2549891590 DIA_eCS_Req_Data 0;
BA_ "GenSigSendType" SG_ 2621456902 DIA_eCS_Req_FD_Data 3;
BA_ "GenSigFuncType" SG_ 2621456902 DIA_eCS_Req_FD_Data 9;
BA_ "GenSigSwitchedByIgnition" SG_ 2621456902 DIA_eCS_Req_FD_Data 0;
BA_ "GenSigSendType" SG_ 2550022662 DIA_eCS_Resp_Data 3;
BA_ "GenSigFuncType" SG_ 2550022662 DIA_eCS_Resp_Data 9;
BA_ "GenSigSwitchedByIgnition" SG_ 2550022662 DIA_eCS_Resp_Data 0;
BA_ "GenSigSendType" SG_ 2621587974 DIA_eCS_Resp_FD_Data 3;
BA_ "GenSigFuncType" SG_ 2621587974 DIA_eCS_Resp_FD_Data 9;
BA_ "GenSigSwitchedByIgnition" SG_ 2621587974 DIA_eCS_Resp_FD_Data 0;
BA_ "GenSigSendType" SG_ 2549880606 DIA_RGS_HL_Req_Data 3;
BA_ "GenSigFuncType" SG_ 2549880606 DIA_RGS_HL_Req_Data 9;
BA_ "GenSigSwitchedByIgnition" SG_ 2549880606 DIA_RGS_HL_Req_Data 0;
BA_ "GenSigSendType" SG_ 2621445918 DIA_RGS_HL_Req_FD_Data 3;
BA_ "GenSigFuncType" SG_ 2621445918 DIA_RGS_HL_Req_FD_Data 9;
BA_ "GenSigSwitchedByIgnition" SG_ 2621445918 DIA_RGS_HL_Req_FD_Data 0;
BA_ "GenSigSendType" SG_ 2550011678 DIA_RGS_HL_Resp_Data 3;
BA_ "GenSigFuncType" SG_ 2550011678 DIA_RGS_HL_Resp_Data 9;
BA_ "GenSigSwitchedByIgnition" SG_ 2550011678 DIA_RGS_HL_Resp_Data 0;
BA_ "GenSigSendType" SG_ 2621576990 DIA_RGS_HL_Resp_FD_Data 3;
BA_ "GenSigFuncType" SG_ 2621576990 DIA_RGS_HL_Resp_FD_Data 9;
BA_ "GenSigSwitchedByIgnition" SG_ 2621576990 DIA_RGS_HL_Resp_FD_Data 0;
BA_ "GenSigSendType" SG_ 2549880607 DIA_RGS_HR_Req_Data 3;
BA_ "GenSigFuncType" SG_ 2549880607 DIA_RGS_HR_Req_Data 9;
BA_ "GenSigSwitchedByIgnition" SG_ 2549880607 DIA_RGS_HR_Req_Data 0;
BA_ "GenSigSendType" SG_ 2621445919 DIA_RGS_HR_Req_FD_Data 3;
BA_ "GenSigFuncType" SG_ 2621445919 DIA_RGS_HR_Req_FD_Data 9;
BA_ "GenSigSwitchedByIgnition" SG_ 2621445919 DIA_RGS_HR_Req_FD_Data 0;
BA_ "GenSigSendType" SG_ 2550011679 DIA_RGS_HR_Resp_Data 3;
BA_ "GenSigFuncType" SG_ 2550011679 DIA_RGS_HR_Resp_Data 9;
BA_ "GenSigSwitchedByIgnition" SG_ 2550011679 DIA_RGS_HR_Resp_Data 0;
BA_ "GenSigSendType" SG_ 2621576991 DIA_RGS_HR_Resp_FD_Data 3;
BA_ "GenSigFuncType" SG_ 2621576991 DIA_RGS_HR_Resp_FD_Data 9;
BA_ "GenSigSwitchedByIgnition" SG_ 2621576991 DIA_RGS_HR_Resp_FD_Data 0;
BA_ "GenSigSendType" SG_ 2549880362 DIA_RGS_VL_Req_Data 3;
BA_ "GenSigFuncType" SG_ 2549880362 DIA_RGS_VL_Req_Data 9;
BA_ "GenSigSwitchedByIgnition" SG_ 2549880362 DIA_RGS_VL_Req_Data 0;
BA_ "GenSigSendType" SG_ 2621445674 DIA_RGS_VL_Req_FD_Data 3;
BA_ "GenSigFuncType" SG_ 2621445674 DIA_RGS_VL_Req_FD_Data 9;
BA_ "GenSigSwitchedByIgnition" SG_ 2621445674 DIA_RGS_VL_Req_FD_Data 0;
BA_ "GenSigSendType" SG_ 2550011434 DIA_RGS_VL_Resp_Data 3;
BA_ "GenSigFuncType" SG_ 2550011434 DIA_RGS_VL_Resp_Data 9;
BA_ "GenSigSwitchedByIgnition" SG_ 2550011434 DIA_RGS_VL_Resp_Data 0;
BA_ "GenSigSendType" SG_ 2621576746 DIA_RGS_VL_Resp_FD_Data 3;
BA_ "GenSigFuncType" SG_ 2621576746 DIA_RGS_VL_Resp_FD_Data 9;
BA_ "GenSigSwitchedByIgnition" SG_ 2621576746 DIA_RGS_VL_Resp_FD_Data 0;
BA_ "GenSigSendType" SG_ 2549880363 DIA_RGS_VR_Req_Data 3;
BA_ "GenSigFuncType" SG_ 2549880363 DIA_RGS_VR_Req_Data 9;
BA_ "GenSigSwitchedByIgnition" SG_ 2549880363 DIA_RGS_VR_Req_Data 0;
BA_ "GenSigSendType" SG_ 2621445675 DIA_RGS_VR_Req_FD_Data 3;
BA_ "GenSigFuncType" SG_ 2621445675 DIA_RGS_VR_Req_FD_Data 9;
BA_ "GenSigSwitchedByIgnition" SG_ 2621445675 DIA_RGS_VR_Req_FD_Data 0;
BA_ "GenSigSendType" SG_ 2550011435 DIA_RGS_VR_Resp_Data 3;
BA_ "GenSigFuncType" SG_ 2550011435 DIA_RGS_VR_Resp_Data 9;
BA_ "GenSigSwitchedByIgnition" SG_ 2550011435 DIA_RGS_VR_Resp_Data 0;
BA_ "GenSigSendType" SG_ 2621576747 DIA_RGS_VR_Resp_FD_Data 3;
BA_ "GenSigFuncType" SG_ 2621576747 DIA_RGS_VR_Resp_FD_Data 9;
BA_ "GenSigSwitchedByIgnition" SG_ 2621576747 DIA_RGS_VR_Resp_FD_Data 0;
BA_ "GenSigSendType" SG_ 1714 DGN_Verlernzaehler 0;
BA_ "GenSigSwitchedByIgnition" SG_ 1714 DGN_Verlernzaehler 0;
BA_ "GenSigSendType" SG_ 1714 KBI_Kilometerstand 0;
BA_ "GenSigStartValue" SG_ 1714 KBI_Kilometerstand 1048574;
BA_ "GenSigSwitchedByIgnition" SG_ 1714 KBI_Kilometerstand 0;
BA_ "Fehlerwert" SG_ 1714 KBI_Kilometerstand 1048575;
BA_ "GenSigSendType" SG_ 1714 Kombi_02_alt 0;
BA_ "GenSigStartValue" SG_ 1714 Kombi_02_alt 1;
BA_ "GenSigFuncType" SG_ 1714 Kombi_02_alt 5;
BA_ "GenSigSwitchedByIgnition" SG_ 1714 Kombi_02_alt 0;
BA_ "GenSigSendType" SG_ 1714 UH_Jahr 0;
BA_ "GenSigSwitchedByIgnition" SG_ 1714 UH_Jahr 0;
BA_ "GenSigSendType" SG_ 1714 UH_Minute 0;
BA_ "GenSigSwitchedByIgnition" SG_ 1714 UH_Minute 0;
BA_ "GenSigSendType" SG_ 1714 UH_Monat 0;
BA_ "GenSigSwitchedByIgnition" SG_ 1714 UH_Monat 0;
BA_ "Fehlerwert" SG_ 1714 UH_Monat 15;
BA_ "GenSigSendType" SG_ 1714 UH_Sekunde 0;
BA_ "GenSigSwitchedByIgnition" SG_ 1714 UH_Sekunde 0;
BA_ "GenSigSendType" SG_ 1714 UH_Stunde 0;
BA_ "GenSigSwitchedByIgnition" SG_ 1714 UH_Stunde 0;
BA_ "GenSigSendType" SG_ 1714 UH_Tag 0;
BA_ "GenSigSwitchedByIgnition" SG_ 1714 UH_Tag 0;
BA_ "GenSigSendType" SG_ 1714 Uhrzeit_01_alt 0;
BA_ "GenSigStartValue" SG_ 1714 Uhrzeit_01_alt 1;
BA_ "GenSigFuncType" SG_ 1714 Uhrzeit_01_alt 5;
BA_ "GenSigSwitchedByIgnition" SG_ 1714 Uhrzeit_01_alt 0;
BA_ "GenSigSendType" SG_ 1714 Vehicle_Driving_Cycle 0;
BA_ "GenSigSwitchedByIgnition" SG_ 1714 Vehicle_Driving_Cycle 0;
BA_ "GenSigSendType" SG_ 1520 BCM1_Stellgroesse_Kl_58s 3;
BA_ "GenSigStartValue" SG_ 1520 BCM1_Stellgroesse_Kl_58s 126;
BA_ "GenSigSwitchedByIgnition" SG_ 1520 BCM1_Stellgroesse_Kl_58s 0;
BA_ "Fehlerwert" SG_ 1520 BCM1_Stellgroesse_Kl_58s 127;
BA_ "GenSigSendType" SG_ 1520 DI_Display_Nachtdesign 3;
BA_ "GenSigSwitchedByIgnition" SG_ 1520 DI_Display_Nachtdesign 0;
BA_ "GenSigSendType" SG_ 1520 DI_Fotosensor 3;
BA_ "GenSigSwitchedByIgnition" SG_ 1520 DI_Fotosensor 0;
BA_ "GenSigSendType" SG_ 1520 DI_KL_58xd 3;
BA_ "GenSigStartValue" SG_ 1520 DI_KL_58xd 254;
BA_ "GenSigSwitchedByIgnition" SG_ 1520 DI_KL_58xd 0;
BA_ "Fehlerwert" SG_ 1520 DI_KL_58xd 255;
BA_ "GenSigSendType" SG_ 1520 DI_KL_58xs 3;
BA_ "GenSigStartValue" SG_ 1520 DI_KL_58xs 126;
BA_ "GenSigSwitchedByIgnition" SG_ 1520 DI_KL_58xs 0;
BA_ "Fehlerwert" SG_ 1520 DI_KL_58xs 127;
BA_ "GenSigSendType" SG_ 1520 DI_KL_58xt 3;
BA_ "GenSigStartValue" SG_ 1520 DI_KL_58xt 126;
BA_ "GenSigSwitchedByIgnition" SG_ 1520 DI_KL_58xt 0;
BA_ "Fehlerwert" SG_ 1520 DI_KL_58xt 127;
BA_ "GenSigSendType" SG_ 331 DSR_01_Sendestatus 6;
BA_ "GenSigSendType" SG_ 331 DSR_QFK_AnfStat 0;
BA_ "GenSigStartValue" SG_ 331 DSR_QFK_AnfStat 1;
BA_ "GenSigSwitchedByIgnition" SG_ 331 DSR_QFK_AnfStat 0;
BA_ "GenSigSendType" SG_ 331 DSR_QFK_Art1 0;
BA_ "GenSigSwitchedByIgnition" SG_ 331 DSR_QFK_Art1 0;
BA_ "GenSigSendType" SG_ 331 DSR_QFK_Art2 0;
BA_ "GenSigSwitchedByIgnition" SG_ 331 DSR_QFK_Art2 0;
BA_ "GenSigSendType" SG_ 331 DSR_QFK_KrSoll 0;
BA_ "GenSigSwitchedByIgnition" SG_ 331 DSR_QFK_KrSoll 0;
BA_ "GenSigSendType" SG_ 331 DSR_QFK_KrSoll_VZ 0;
BA_ "GenSigSwitchedByIgnition" SG_ 331 DSR_QFK_KrSoll_VZ 0;
BA_ "GenSigSendType" SG_ 331 DSR_QFK_KruemmSoll 0;
BA_ "GenSigSwitchedByIgnition" SG_ 331 DSR_QFK_KruemmSoll 0;
BA_ "GenSigSendType" SG_ 331 DSR_QFK_KruemmSoll_VZ 0;
BA_ "GenSigSwitchedByIgnition" SG_ 331 DSR_QFK_KruemmSoll_VZ 0;
BA_ "GenSigSendType" SG_ 331 DSR_QFK_Signal1 0;
BA_ "GenSigSwitchedByIgnition" SG_ 331 DSR_QFK_Signal1 0;
BA_ "GenSigSendType" SG_ 331 DSR_QFK_Signal2 0;
BA_ "GenSigSwitchedByIgnition" SG_ 331 DSR_QFK_Signal2 0;
BA_ "GenSigSendType" SG_ 331 DSR_QFK_Spuerb 0;
BA_ "GenSigSwitchedByIgnition" SG_ 331 DSR_QFK_Spuerb 0;
BA_ "GenSigSendType" SG_ 331 SOK_DSR_01_Signatur 0;
BA_ "GenSigFuncType" SG_ 331 SOK_DSR_01_Signatur 15;
BA_ "GenSigSwitchedByIgnition" SG_ 331 SOK_DSR_01_Signatur 0;
BA_ "GenSigSendType" SG_ 420 EA_01_BZ 0;
BA_ "GenSigFuncType" SG_ 420 EA_01_BZ 1;
BA_ "GenSigSendType" SG_ 420 EA_01_CRC 0;
BA_ "GenSigFuncType" SG_ 420 EA_01_CRC 2;
BA_ "GenSigSendType" SG_ 420 EA_01_Sendestatus 6;
BA_ "GenSigSendType" SG_ 420 EA_aktiv_laengs 0;
BA_ "GenSigSendType" SG_ 420 EA_Anf_Prefill 0;
BA_ "GenSigSendType" SG_ 420 EA_Anforderung_HMS 0;
BA_ "GenSigSendType" SG_ 420 EA_Funktionsstatus 0;
BA_ "GenSigSendType" SG_ 420 EA_Gurtstraffer_Anf 3;
BA_ "GenSigSendType" SG_ 420 EA_Parken_beibehalten_HMS 0;
BA_ "GenSigStartValue" SG_ 420 EA_Parken_beibehalten_HMS 2;
BA_ "Fehlerwert" SG_ 420 EA_Parken_beibehalten_HMS 3;
BA_ "GenSigSendType" SG_ 420 EA_PreCrash_Anf 0;
BA_ "GenSigSendType" SG_ 420 EA_Ruckfreigabe 0;
BA_ "GenSigSendType" SG_ 420 EA_Ruckstaerke 0;
BA_ "GenSigSendType" SG_ 420 EA_Sollbeschleunigung 0;
BA_ "GenSigStartValue" SG_ 420 EA_Sollbeschleunigung 2046;
BA_ "Fehlerwert" SG_ 420 EA_Sollbeschleunigung 2047;
BA_ "GenSigSendType" SG_ 420 EA_Warnruckprofil 0;
BA_ "GenSigSendType" SG_ 496 ACF_Lampe_Hands_Off 3;
BA_ "GenSigSendType" SG_ 496 EA_02_BZ 0;
BA_ "GenSigFuncType" SG_ 496 EA_02_BZ 1;
BA_ "GenSigSendType" SG_ 496 EA_02_CRC 0;
BA_ "GenSigFuncType" SG_ 496 EA_02_CRC 2;
BA_ "GenSigSendType" SG_ 496 EA_Blinken 3;
BA_ "GenSigSendType" SG_ 496 EA_Bremslichtblinken 3;
BA_ "GenSigSendType" SG_ 496 EA_eCall_Anf 3;
BA_ "GenSigSendType" SG_ 496 EA_Fahrzeughupe_Anf 3;
BA_ "GenSigSendType" SG_ 496 EA_Infotainment_Anf 3;
BA_ "GenSigSendType" SG_ 496 EA_Innenraumlicht_Anf 3;
BA_ "GenSigSendType" SG_ 496 EA_Status_HMI 3;
BA_ "GenSigSendType" SG_ 496 EA_Texte 3;
BA_ "GenSigSendType" SG_ 496 EA_Tueren_Anf 3;
BA_ "GenSigSendType" SG_ 496 EA_Warnlevel 3;
BA_ "GenSigSendType" SG_ 496 STP_Primaeranz 3;
BA_ "GenSigSendType" SG_ 496 zFAS_Warnblinken 3;
BA_ "GenSigSendType" SG_ 236 EBKV_02_BZ 0;
BA_ "GenSigFuncType" SG_ 236 EBKV_02_BZ 1;
BA_ "GenSigSwitchedByIgnition" SG_ 236 EBKV_02_BZ 0;
BA_ "GenSigSendType" SG_ 236 EBKV_02_CRC 0;
BA_ "GenSigFuncType" SG_ 236 EBKV_02_CRC 2;
BA_ "GenSigSwitchedByIgnition" SG_ 236 EBKV_02_CRC 0;
BA_ "GenSigSendType" SG_ 236 EBKV_AktBr_aktiv 0;
BA_ "GenSigSwitchedByIgnition" SG_ 236 EBKV_AktBr_aktiv 0;
BA_ "GenSigSendType" SG_ 236 EBKV_aktBr_Volumenstrom_Ist 0;
BA_ "GenSigStartValue" SG_ 236 EBKV_aktBr_Volumenstrom_Ist 65534;
BA_ "GenSigSwitchedByIgnition" SG_ 236 EBKV_aktBr_Volumenstrom_Ist 0;
BA_ "Fehlerwert" SG_ 236 EBKV_aktBr_Volumenstrom_Ist 65535;
BA_ "GenSigSendType" SG_ 236 EBKV_extBr_Druck_Max 0;
BA_ "GenSigStartValue" SG_ 236 EBKV_extBr_Druck_Max 254;
BA_ "GenSigSwitchedByIgnition" SG_ 236 EBKV_extBr_Druck_Max 0;
BA_ "Fehlerwert" SG_ 236 EBKV_extBr_Druck_Max 255;
BA_ "GenSigSendType" SG_ 236 EBKV_extBr_Status 0;
BA_ "GenSigSwitchedByIgnition" SG_ 236 EBKV_extBr_Status 0;
BA_ "GenSigSendType" SG_ 236 EBKV_Stangenweg 0;
BA_ "GenSigStartValue" SG_ 236 EBKV_Stangenweg 4094;
BA_ "GenSigSwitchedByIgnition" SG_ 236 EBKV_Stangenweg 0;
BA_ "Fehlerwert" SG_ 236 EBKV_Stangenweg 4095;
BA_ "GenSigSendType" SG_ 236 EBKV_Stangenweg_Fahrerwunsch 0;
BA_ "GenSigStartValue" SG_ 236 EBKV_Stangenweg_Fahrerwunsch 4094;
BA_ "GenSigSwitchedByIgnition" SG_ 236 EBKV_Stangenweg_Fahrerwunsch 0;
BA_ "Fehlerwert" SG_ 236 EBKV_Stangenweg_Fahrerwunsch 4095;
BA_ "GenSigSendType" SG_ 236 SOK_EBKV_02_Signatur 0;
BA_ "GenSigFuncType" SG_ 236 SOK_EBKV_02_Signatur 15;
BA_ "GenSigSendType" SG_ 374 EBKV_03_BZ 0;
BA_ "GenSigFuncType" SG_ 374 EBKV_03_BZ 1;
BA_ "GenSigSwitchedByIgnition" SG_ 374 EBKV_03_BZ 0;
BA_ "GenSigSendType" SG_ 374 EBKV_03_CRC 0;
BA_ "GenSigFuncType" SG_ 374 EBKV_03_CRC 2;
BA_ "GenSigSwitchedByIgnition" SG_ 374 EBKV_03_CRC 0;
BA_ "GenSigSendType" SG_ 374 EBKV_Activate_Fallback_ESP 0;
BA_ "GenSigSwitchedByIgnition" SG_ 374 EBKV_Activate_Fallback_ESP 0;
BA_ "GenSigSendType" SG_ 374 EBKV_Anforderung_HMS 0;
BA_ "GenSigSwitchedByIgnition" SG_ 374 EBKV_Anforderung_HMS 0;
BA_ "GenSigSendType" SG_ 374 EBKV_Aussteuerdruck 0;
BA_ "GenSigStartValue" SG_ 374 EBKV_Aussteuerdruck 254;
BA_ "GenSigSwitchedByIgnition" SG_ 374 EBKV_Aussteuerdruck 0;
BA_ "Fehlerwert" SG_ 374 EBKV_Aussteuerdruck 255;
BA_ "GenSigSendType" SG_ 374 EBKV_Bremspedalweg 0;
BA_ "GenSigSwitchedByIgnition" SG_ 374 EBKV_Bremspedalweg 0;
BA_ "Fehlerwert" SG_ 374 EBKV_Bremspedalweg 255;
BA_ "GenSigSendType" SG_ 374 EBKV_Diagnose 0;
BA_ "GenSigSwitchedByIgnition" SG_ 374 EBKV_Diagnose 0;
BA_ "GenSigSendType" SG_ 374 EBKV_Fahrer_bremst 0;
BA_ "GenSigSwitchedByIgnition" SG_ 374 EBKV_Fahrer_bremst 0;
BA_ "GenSigSendType" SG_ 374 EBKV_Fahrer_bremst_deutlich 0;
BA_ "GenSigSwitchedByIgnition" SG_ 374 EBKV_Fahrer_bremst_deutlich 0;
BA_ "GenSigSendType" SG_ 374 EBKV_Kraftblending_Reserve 0;
BA_ "GenSigStartValue" SG_ 374 EBKV_Kraftblending_Reserve 254;
BA_ "GenSigSwitchedByIgnition" SG_ 374 EBKV_Kraftblending_Reserve 0;
BA_ "Fehlerwert" SG_ 374 EBKV_Kraftblending_Reserve 255;
BA_ "GenSigSendType" SG_ 374 EBKV_OBD_Status 0;
BA_ "GenSigSwitchedByIgnition" SG_ 374 EBKV_OBD_Status 0;
BA_ "GenSigSendType" SG_ 374 EBKV_QBit_Fahrer_bremst 0;
BA_ "GenSigStartValue" SG_ 374 EBKV_QBit_Fahrer_bremst 1;
BA_ "GenSigSwitchedByIgnition" SG_ 374 EBKV_QBit_Fahrer_bremst 0;
BA_ "GenSigSendType" SG_ 374 EBKV_Restdruckabsenkung 0;
BA_ "GenSigSwitchedByIgnition" SG_ 374 EBKV_Restdruckabsenkung 0;
BA_ "GenSigSendType" SG_ 374 EBKV_Status_02 0;
BA_ "GenSigSwitchedByIgnition" SG_ 374 EBKV_Status_02 0;
BA_ "GenSigSendType" SG_ 374 EBKV_Textanzeigen 0;
BA_ "GenSigSwitchedByIgnition" SG_ 374 EBKV_Textanzeigen 0;
BA_ "GenSigSendType" SG_ 374 EBKV_VMM_Sek_Notstopp_Status 0;
BA_ "GenSigSwitchedByIgnition" SG_ 374 EBKV_VMM_Sek_Notstopp_Status 0;
BA_ "GenSigSendType" SG_ 374 EPB_Status_ext 0;
BA_ "GenSigStartValue" SG_ 374 EPB_Status_ext 6;
BA_ "GenSigSwitchedByIgnition" SG_ 374 EPB_Status_ext 0;
BA_ "GenSigSendType" SG_ 374 SBS_Anforderung_GE 0;
BA_ "GenSigSwitchedByIgnition" SG_ 374 SBS_Anforderung_GE 0;
BA_ "GenSigSendType" SG_ 374 SOK_EBKV_03_Signatur 0;
BA_ "GenSigFuncType" SG_ 374 SOK_EBKV_03_Signatur 15;
BA_ "GenSigSendType" SG_ 2589283963 EBKV_Indc_StChk 0;
BA_ "GenSigStartValue" SG_ 2589283963 EBKV_Indc_StChk 1;
BA_ "GenSigSwitchedByIgnition" SG_ 2589283963 EBKV_Indc_StChk 0;
BA_ "GenSigSendType" SG_ 2589283963 EBKV_Indc_StFail 0;
BA_ "GenSigSwitchedByIgnition" SG_ 2589283963 EBKV_Indc_StFail 0;
BA_ "GenSigSendType" SG_ 2589283963 EBKV_OBD_Status_Auth 0;
BA_ "GenSigSwitchedByIgnition" SG_ 2589283963 EBKV_OBD_Status_Auth 0;
BA_ "GenSigSendType" SG_ 2589283963 OBDProtocol_EBKV 0;
BA_ "GenSigStartValue" SG_ 2589283963 OBDProtocol_EBKV 254;
BA_ "GenSigSwitchedByIgnition" SG_ 2589283963 OBDProtocol_EBKV 0;
BA_ "Fehlerwert" SG_ 2589283963 OBDProtocol_EBKV 255;
BA_ "GenSigSendType" SG_ 2589283963 SOK_EBKV_05_Signatur 0;
BA_ "GenSigFuncType" SG_ 2589283963 SOK_EBKV_05_Signatur 15;
BA_ "GenSigSwitchedByIgnition" SG_ 2589283963 SOK_EBKV_05_Signatur 0;
BA_ "GenSigSendType" SG_ 193 CluAxs_Avl 0;
BA_ "GenSigSwitchedByIgnition" SG_ 193 CluAxs_Avl 0;
BA_ "Fehlerwert" SG_ 193 CluAxs_Avl 2;
BA_ "GenSigSendType" SG_ 193 CluAxs_State 0;
BA_ "GenSigSwitchedByIgnition" SG_ 193 CluAxs_State 0;
BA_ "GenSigSendType" SG_ 193 EM2_01_BZ 0;
BA_ "GenSigFuncType" SG_ 193 EM2_01_BZ 1;
BA_ "GenSigSwitchedByIgnition" SG_ 193 EM2_01_BZ 0;
BA_ "GenSigSendType" SG_ 193 EM2_01_CRC 0;
BA_ "GenSigFuncType" SG_ 193 EM2_01_CRC 2;
BA_ "GenSigSwitchedByIgnition" SG_ 193 EM2_01_CRC 0;
BA_ "GenSigSendType" SG_ 193 EM2_AR_aktiv 0;
BA_ "GenSigSwitchedByIgnition" SG_ 193 EM2_AR_aktiv 0;
BA_ "GenSigSendType" SG_ 193 EM2_ErwGrenzen_aktiv 0;
BA_ "GenSigSwitchedByIgnition" SG_ 193 EM2_ErwGrenzen_aktiv 0;
BA_ "GenSigSendType" SG_ 193 EM2_Fehler_ElAntriebAbschaltung 0;
BA_ "GenSigSwitchedByIgnition" SG_ 193 EM2_Fehler_ElAntriebAbschaltung 0;
BA_ "GenSigSendType" SG_ 193 EM2_Fehler_Notabschaltung 0;
BA_ "GenSigSwitchedByIgnition" SG_ 193 EM2_Fehler_Notabschaltung 0;
BA_ "Fehlerwert" SG_ 193 EM2_Fehler_Notabschaltung 1;
BA_ "GenSigSendType" SG_ 193 EM2_IstDrehzahl 0;
BA_ "GenSigStartValue" SG_ 193 EM2_IstDrehzahl 32766;
BA_ "GenSigSwitchedByIgnition" SG_ 193 EM2_IstDrehzahl 0;
BA_ "Fehlerwert" SG_ 193 EM2_IstDrehzahl 32767;
BA_ "GenSigSendType" SG_ 193 EM2_Istmodus 0;
BA_ "GenSigStartValue" SG_ 193 EM2_Istmodus 15;
BA_ "GenSigSwitchedByIgnition" SG_ 193 EM2_Istmodus 0;
BA_ "GenSigSendType" SG_ 193 EM2_IstMoment 0;
BA_ "GenSigStartValue" SG_ 193 EM2_IstMoment 4094;
BA_ "GenSigSwitchedByIgnition" SG_ 193 EM2_IstMoment 0;
BA_ "Fehlerwert" SG_ 193 EM2_IstMoment 4095;
BA_ "GenSigSendType" SG_ 193 EM2_IstSpannung 0;
BA_ "GenSigStartValue" SG_ 193 EM2_IstSpannung 4094;
BA_ "GenSigSwitchedByIgnition" SG_ 193 EM2_IstSpannung 0;
BA_ "Fehlerwert" SG_ 193 EM2_IstSpannung 4095;
BA_ "GenSigSendType" SG_ 193 EM2_Max_Moment 0;
BA_ "GenSigStartValue" SG_ 193 EM2_Max_Moment 2046;
BA_ "GenSigSwitchedByIgnition" SG_ 193 EM2_Max_Moment 0;
BA_ "Fehlerwert" SG_ 193 EM2_Max_Moment 2047;
BA_ "GenSigSendType" SG_ 193 EM2_Max_Moment_Gesamt 0;
BA_ "GenSigStartValue" SG_ 193 EM2_Max_Moment_Gesamt 2046;
BA_ "GenSigSwitchedByIgnition" SG_ 193 EM2_Max_Moment_Gesamt 0;
BA_ "Fehlerwert" SG_ 193 EM2_Max_Moment_Gesamt 2047;
BA_ "GenSigSendType" SG_ 193 EM2_Max_Moment_Lim 0;
BA_ "GenSigStartValue" SG_ 193 EM2_Max_Moment_Lim 2046;
BA_ "GenSigSwitchedByIgnition" SG_ 193 EM2_Max_Moment_Lim 0;
BA_ "Fehlerwert" SG_ 193 EM2_Max_Moment_Lim 2047;
BA_ "GenSigSendType" SG_ 193 EM2_Min_Moment 0;
BA_ "GenSigStartValue" SG_ 193 EM2_Min_Moment 2046;
BA_ "GenSigSwitchedByIgnition" SG_ 193 EM2_Min_Moment 0;
BA_ "Fehlerwert" SG_ 193 EM2_Min_Moment 2047;
BA_ "GenSigSendType" SG_ 193 EM2_Min_Moment_Gesamt 0;
BA_ "GenSigStartValue" SG_ 193 EM2_Min_Moment_Gesamt 2046;
BA_ "GenSigSwitchedByIgnition" SG_ 193 EM2_Min_Moment_Gesamt 0;
BA_ "Fehlerwert" SG_ 193 EM2_Min_Moment_Gesamt 2047;
BA_ "GenSigSendType" SG_ 193 EM2_Min_Moment_Lim 0;
BA_ "GenSigStartValue" SG_ 193 EM2_Min_Moment_Lim 2046;
BA_ "GenSigSwitchedByIgnition" SG_ 193 EM2_Min_Moment_Lim 0;
BA_ "Fehlerwert" SG_ 193 EM2_Min_Moment_Lim 2047;
BA_ "GenSigSendType" SG_ 193 EM2_Mom_DrzEingriff 0;
BA_ "GenSigStartValue" SG_ 193 EM2_Mom_DrzEingriff 2046;
BA_ "GenSigSwitchedByIgnition" SG_ 193 EM2_Mom_DrzEingriff 0;
BA_ "Fehlerwert" SG_ 193 EM2_Mom_DrzEingriff 2047;
BA_ "GenSigSendType" SG_ 193 EM2_Moment_AR_Eingriff 0;
BA_ "GenSigStartValue" SG_ 193 EM2_Moment_AR_Eingriff 4094;
BA_ "GenSigSwitchedByIgnition" SG_ 193 EM2_Moment_AR_Eingriff 0;
BA_ "Fehlerwert" SG_ 193 EM2_Moment_AR_Eingriff 4095;
BA_ "GenSigSendType" SG_ 193 EM2_Raddrehzahl_links 0;
BA_ "GenSigStartValue" SG_ 193 EM2_Raddrehzahl_links 8190;
BA_ "GenSigSwitchedByIgnition" SG_ 193 EM2_Raddrehzahl_links 0;
BA_ "Fehlerwert" SG_ 193 EM2_Raddrehzahl_links 8191;
BA_ "GenSigSendType" SG_ 193 EM2_Raddrehzahl_rechts 0;
BA_ "GenSigStartValue" SG_ 193 EM2_Raddrehzahl_rechts 8190;
BA_ "GenSigSwitchedByIgnition" SG_ 193 EM2_Raddrehzahl_rechts 0;
BA_ "Fehlerwert" SG_ 193 EM2_Raddrehzahl_rechts 8191;
BA_ "GenSigSendType" SG_ 193 EM2_Status_DrzEingriff 3;
BA_ "GenSigSwitchedByIgnition" SG_ 193 EM2_Status_DrzEingriff 0;
BA_ "Fehlerwert" SG_ 193 EM2_Status_DrzEingriff 3;
BA_ "GenSigSendType" SG_ 193 EM2_Strom_HV 0;
BA_ "GenSigStartValue" SG_ 193 EM2_Strom_HV 4094;
BA_ "GenSigSwitchedByIgnition" SG_ 193 EM2_Strom_HV 0;
BA_ "Fehlerwert" SG_ 193 EM2_Strom_HV 4095;
BA_ "GenSigSendType" SG_ 503 EPB_03_BZ 0;
BA_ "GenSigFuncType" SG_ 503 EPB_03_BZ 1;
BA_ "GenSigSwitchedByIgnition" SG_ 503 EPB_03_BZ 0;
BA_ "GenSigSendType" SG_ 503 EPB_03_CRC 0;
BA_ "GenSigFuncType" SG_ 503 EPB_03_CRC 2;
BA_ "GenSigSwitchedByIgnition" SG_ 503 EPB_03_CRC 0;
BA_ "GenSigSendType" SG_ 503 EPB_Autohold_Standbyanzeige 3;
BA_ "GenSigSwitchedByIgnition" SG_ 503 EPB_Autohold_Standbyanzeige 0;
BA_ "GenSigSendType" SG_ 503 EPB_Autoholdlampe_02 3;
BA_ "GenSigSwitchedByIgnition" SG_ 503 EPB_Autoholdlampe_02 0;
BA_ "GenSigSendType" SG_ 503 EPB_Fehlermeldungen_02 3;
BA_ "GenSigSwitchedByIgnition" SG_ 503 EPB_Fehlermeldungen_02 0;
BA_ "GenSigSendType" SG_ 503 EPB_Funktionslampe_02 3;
BA_ "GenSigSwitchedByIgnition" SG_ 503 EPB_Funktionslampe_02 0;
BA_ "GenSigSendType" SG_ 503 EPB_Parkanzeige 3;
BA_ "GenSigSwitchedByIgnition" SG_ 503 EPB_Parkanzeige 0;
BA_ "GenSigSendType" SG_ 503 EPB_Texte_02 3;
BA_ "GenSigSwitchedByIgnition" SG_ 503 EPB_Texte_02 0;
BA_ "GenSigSendType" SG_ 2527679687 EPS_ASM_Data_1 0;
BA_ "GenSigSendType" SG_ 2527679687 EPS_ASM_Data_2 0;
BA_ "GenSigSendType" SG_ 2527679687 EPS_ASM_Data_3 0;
BA_ "GenSigSendType" SG_ 2527679687 EPS_ASM_Data_4 0;
BA_ "GenSigSendType" SG_ 2527679687 EPS_ASM_Data_5 0;
BA_ "GenSigSendType" SG_ 2527679687 EPS_ASM_Data_6 0;
BA_ "GenSigSendType" SG_ 2527679687 EPS_ASM_Ereignis 3;
BA_ "GenSigSendType" SG_ 2527679687 EPS_ASM_Zeitstempel_02 3;
BA_ "GenSigStartValue" SG_ 2527679687 EPS_ASM_Zeitstempel_02 255;
BA_ "GenSigSwitchedByIgnition" SG_ 2527679687 EPS_ASM_Zeitstempel_02 0;
BA_REL_ "GenSigTimeoutTime" BU_SG_REL_ Airbag SG_ 2527679952 BFSFo_Position_2_CRC 2000;
BA_REL_ "GenSigTimeoutTime" BU_SG_REL_ Airbag SG_ 2527679952 BFSFo_Position_2_BZ 2000;
BA_REL_ "GenSigTimeoutTime" BU_SG_REL_ Airbag SG_ 2527679952 HBFSS_Torso_Pos 2000;
BA_REL_ "GenSigTimeoutTime" BU_SG_REL_ Airbag SG_ 870 BM_Warnblinken 5000;
BA_REL_ "GenSigTimeoutTime" BU_SG_REL_ Airbag SG_ 870 BM_links 5000;
BA_REL_ "GenSigTimeoutTime" BU_SG_REL_ Airbag SG_ 870 BM_rechts 5000;
BA_REL_ "GenSigTimeoutTime" BU_SG_REL_ Airbag SG_ 2463978646 CHA_Fahrer_Umschaltung 5000;
BA_REL_ "GenSigTimeoutTime" BU_SG_REL_ Airbag SG_ 2463978646 CHA_Ziel_FahrPr_PreCrash 5000;
BA_REL_ "GenSigTimeoutTime" BU_SG_REL_ Airbag SG_ 1714 DGN_Verlernzaehler 5000;
BA_REL_ "GenSigTimeoutTime" BU_SG_REL_ Airbag SG_ 1714 KBI_Kilometerstand 5000;
BA_REL_ "GenSigTimeoutTime" BU_SG_REL_ Airbag SG_ 1714 UH_Jahr 5000;
BA_REL_ "GenSigTimeoutTime" BU_SG_REL_ Airbag SG_ 1714 UH_Monat 5000;
BA_REL_ "GenSigTimeoutTime" BU_SG_REL_ Airbag SG_ 1714 UH_Tag 5000;
BA_REL_ "GenSigTimeoutTime" BU_SG_REL_ Airbag SG_ 1714 UH_Stunde 5000;
BA_REL_ "GenSigTimeoutTime" BU_SG_REL_ Airbag SG_ 1714 UH_Minute 5000;
BA_REL_ "GenSigTimeoutTime" BU_SG_REL_ Airbag SG_ 1714 UH_Sekunde 5000;
BA_REL_ "GenSigTimeoutTime" BU_SG_REL_ Airbag SG_ 1714 Vehicle_Driving_Cycle 5000;
BA_REL_ "GenSigTimeoutTime" BU_SG_REL_ Airbag SG_ 1714 Kombi_02_alt 5000;
BA_REL_ "GenSigTimeoutTime" BU_SG_REL_ Airbag SG_ 1714 Uhrzeit_01_alt 5000;
BA_REL_ "GenSigTimeoutTime" BU_SG_REL_ Airbag SG_ 1520 DI_KL_58xd 2000;
BA_REL_ "GenSigTimeoutTime" BU_SG_REL_ Airbag SG_ 1520 DI_KL_58xs 2000;
BA_REL_ "GenSigTimeoutTime" BU_SG_REL_ Airbag SG_ 1520 DI_KL_58xt 2000;
BA_REL_ "GenSigTimeoutTime" BU_SG_REL_ Airbag SG_ 420 EA_PreCrash_Anf 5000;
BA_REL_ "GenSigTimeoutTime" BU_SG_REL_ Airbag SG_ 420 EA_Funktionsstatus 5000;
BA_REL_ "GenSigTimeoutTime" BU_SG_REL_ Airbag SG_ 496 EA_Texte 5000;
BA_REL_ "GenSigTimeoutTime" BU_SG_REL_ Airbag SG_ 496 EA_Status_HMI 5000;
BA_REL_ "GenSigTimeoutTime" BU_SG_REL_ Airbag SG_ 374 EBKV_Bremspedalweg 500;
BA_REL_ "GenSigTimeoutTime" BU_SG_REL_ Airbag SG_ 2527679687 EPS_ASM_Ereignis 5000;
BA_REL_ "GenSigTimeoutTime" BU_SG_REL_ Airbag SG_ 2527679687 EPS_ASM_Zeitstempel_02 5000;
BA_REL_ "GenSigTimeoutTime" BU_SG_REL_ Airbag SG_ 2527679687 EPS_ASM_Data_1 5000;
BA_REL_ "GenSigTimeoutTime" BU_SG_REL_ Airbag SG_ 2527679687 EPS_ASM_Data_2 5000;
BA_REL_ "GenSigTimeoutTime" BU_SG_REL_ Airbag SG_ 2527679687 EPS_ASM_Data_3 5000;
BA_REL_ "GenSigTimeoutTime" BU_SG_REL_ Airbag SG_ 2527679687 EPS_ASM_Data_4 5000;
BA_REL_ "GenSigTimeoutTime" BU_SG_REL_ Airbag SG_ 2527679687 EPS_ASM_Data_5 5000;
BA_REL_ "GenSigTimeoutTime" BU_SG_REL_ Airbag SG_ 2527679687 EPS_ASM_Data_6 5000;
BA_REL_ "GenSigTimeoutTime" BU_SG_REL_ Allrad_Haldex SG_ 2463978646 CHA_Ziel_FahrPr_ALR 5000;
BA_REL_ "GenSigTimeoutTime" BU_SG_REL_ Allrad_Haldex SG_ 1714 DGN_Verlernzaehler 5000;
BA_REL_ "GenSigTimeoutTime" BU_SG_REL_ Allrad_Haldex SG_ 1714 KBI_Kilometerstand 5000;
BA_REL_ "GenSigTimeoutTime" BU_SG_REL_ Allrad_Haldex SG_ 1714 UH_Jahr 5000;
BA_REL_ "GenSigTimeoutTime" BU_SG_REL_ Allrad_Haldex SG_ 1714 UH_Monat 5000;
BA_REL_ "GenSigTimeoutTime" BU_SG_REL_ Allrad_Haldex SG_ 1714 UH_Tag 5000;
BA_REL_ "GenSigTimeoutTime" BU_SG_REL_ Allrad_Haldex SG_ 1714 UH_Stunde 5000;
BA_REL_ "GenSigTimeoutTime" BU_SG_REL_ Allrad_Haldex SG_ 1714 UH_Minute 5000;
BA_REL_ "GenSigTimeoutTime" BU_SG_REL_ Allrad_Haldex SG_ 1714 UH_Sekunde 5000;
BA_REL_ "GenSigTimeoutTime" BU_SG_REL_ DCC_Gen3 SG_ 2463978646 CHA_Ziel_FahrPr_DR 5000;
BA_REL_ "GenSigTimeoutTime" BU_SG_REL_ DCC_Gen3 SG_ 1714 KBI_Kilometerstand 5000;
BA_REL_ "GenSigTimeoutTime" BU_SG_REL_ DCC_Gen3 SG_ 1714 UH_Jahr 5000;
BA_REL_ "GenSigTimeoutTime" BU_SG_REL_ DCC_Gen3 SG_ 1714 UH_Monat 5000;
BA_REL_ "GenSigTimeoutTime" BU_SG_REL_ DCC_Gen3 SG_ 1714 UH_Tag 5000;
BA_REL_ "GenSigTimeoutTime" BU_SG_REL_ DCC_Gen3 SG_ 1714 UH_Stunde 5000;
BA_REL_ "GenSigTimeoutTime" BU_SG_REL_ DCC_Gen3 SG_ 1714 UH_Minute 5000;
BA_REL_ "GenSigTimeoutTime" BU_SG_REL_ DCC_Gen3 SG_ 1714 UH_Sekunde 5000;
BA_REL_ "GenSigTimeoutTime" BU_SG_REL_ ESC_MQBW SG_ 870 BM_Warnblinken 5000;
BA_REL_ "GenSigTimeoutTime" BU_SG_REL_ ESC_MQBW SG_ 2463978646 CHA_Ziel_FahrPr_ESP 5000;
BA_REL_ "GenSigTimeoutTime" BU_SG_REL_ ESC_MQBW SG_ 2463978646 CHA_Fahrer_Umschaltung 5000;
BA_REL_ "GenSigTimeoutTime" BU_SG_REL_ ESC_MQBW SG_ 2463978646 CHA_Ziel_FahrPr_DR 5000;
BA_REL_ "GenSigTimeoutTime" BU_SG_REL_ ESC_MQBW SG_ 2463978646 CHA_Ziel_FahrPr_VAQ 5000;
BA_REL_ "GenSigTimeoutTime" BU_SG_REL_ ESC_MQBW SG_ 2463978646 CHA_Ziel_FahrPr_HDC 5000;
BA_REL_ "GenSigTimeoutTime" BU_SG_REL_ ESC_MQBW SG_ 2463978646 CHA_Ziel_FahrPr_mFDR 5000;
BA_REL_ "GenSigTimeoutTime" BU_SG_REL_ ESC_MQBW SG_ 2463978646 CHA_Ziel_FahrPr_HHC 5000;
BA_REL_ "GenSigTimeoutTime" BU_SG_REL_ ESC_MQBW SG_ 2463978646 CHA_Ziel_FahrPr_EDS 5000;
BA_REL_ "GenSigTimeoutTime" BU_SG_REL_ ESC_MQBW SG_ 514 DR_Funktionsstatus 500;
BA_REL_ "GenSigTimeoutTime" BU_SG_REL_ ESC_MQBW SG_ 514 DR_Drehwinkel_VL 500;
BA_REL_ "GenSigTimeoutTime" BU_SG_REL_ ESC_MQBW SG_ 514 DR_Drehwinkel_VR 500;
BA_REL_ "GenSigTimeoutTime" BU_SG_REL_ ESC_MQBW SG_ 514 DR_Drehwinkel_HL 500;
BA_REL_ "GenSigTimeoutTime" BU_SG_REL_ ESC_MQBW SG_ 514 DR_Drehwinkel_HR 500;
BA_REL_ "GenSigTimeoutTime" BU_SG_REL_ ESC_MQBW SG_ 514 DR_Daempferweg_VL 500;
BA_REL_ "GenSigTimeoutTime" BU_SG_REL_ ESC_MQBW SG_ 514 DR_Daempferweg_VR 500;
BA_REL_ "GenSigTimeoutTime" BU_SG_REL_ ESC_MQBW SG_ 514 DR_Daempferweg_HL 500;
BA_REL_ "GenSigTimeoutTime" BU_SG_REL_ ESC_MQBW SG_ 514 DR_Daempferweg_HR 500;
BA_REL_ "GenSigTimeoutTime" BU_SG_REL_ ESC_MQBW SG_ 1714 DGN_Verlernzaehler 5000;
BA_REL_ "GenSigTimeoutTime" BU_SG_REL_ ESC_MQBW SG_ 1714 KBI_Kilometerstand 5000;
BA_REL_ "GenSigTimeoutTime" BU_SG_REL_ ESC_MQBW SG_ 1714 UH_Jahr 5000;
BA_REL_ "GenSigTimeoutTime" BU_SG_REL_ ESC_MQBW SG_ 1714 UH_Monat 5000;
BA_REL_ "GenSigTimeoutTime" BU_SG_REL_ ESC_MQBW SG_ 1714 UH_Tag 5000;
BA_REL_ "GenSigTimeoutTime" BU_SG_REL_ ESC_MQBW SG_ 1714 UH_Stunde 5000;
BA_REL_ "GenSigTimeoutTime" BU_SG_REL_ ESC_MQBW SG_ 1714 UH_Minute 5000;
BA_REL_ "GenSigTimeoutTime" BU_SG_REL_ ESC_MQBW SG_ 1714 UH_Sekunde 5000;
BA_REL_ "GenSigTimeoutTime" BU_SG_REL_ ESC_MQBW SG_ 1520 DI_KL_58xd 2000;
BA_REL_ "GenSigTimeoutTime" BU_SG_REL_ ESC_MQBW SG_ 420 EA_01_CRC 5000;
BA_REL_ "GenSigTimeoutTime" BU_SG_REL_ ESC_MQBW SG_ 420 EA_01_BZ 5000;
BA_REL_ "GenSigTimeoutTime" BU_SG_REL_ ESC_MQBW SG_ 420 EA_Parken_beibehalten_HMS 5000;
BA_REL_ "GenSigTimeoutTime" BU_SG_REL_ ESC_MQBW SG_ 420 EA_Ruckstaerke 5000;
BA_REL_ "GenSigTimeoutTime" BU_SG_REL_ ESC_MQBW SG_ 420 EA_Anf_Prefill 5000;
BA_REL_ "GenSigTimeoutTime" BU_SG_REL_ ESC_MQBW SG_ 420 EA_Anforderung_HMS 5000;
BA_REL_ "GenSigTimeoutTime" BU_SG_REL_ ESC_MQBW SG_ 420 EA_Ruckfreigabe 5000;
BA_REL_ "GenSigTimeoutTime" BU_SG_REL_ ESC_MQBW SG_ 420 EA_01_Sendestatus 5000;
BA_REL_ "GenSigTimeoutTime" BU_SG_REL_ ESC_MQBW SG_ 236 EBKV_02_CRC 500;
BA_REL_ "GenSigTimeoutTime" BU_SG_REL_ ESC_MQBW SG_ 236 EBKV_02_BZ 500;
BA_REL_ "GenSigTimeoutTime" BU_SG_REL_ ESC_MQBW SG_ 236 EBKV_extBr_Status 500;
BA_REL_ "GenSigTimeoutTime" BU_SG_REL_ ESC_MQBW SG_ 236 EBKV_AktBr_aktiv 500;
BA_REL_ "GenSigTimeoutTime" BU_SG_REL_ ESC_MQBW SG_ 236 EBKV_extBr_Druck_Max 500;
BA_REL_ "GenSigTimeoutTime" BU_SG_REL_ ESC_MQBW SG_ 236 EBKV_aktBr_Volumenstrom_Ist 500;
BA_REL_ "GenSigTimeoutTime" BU_SG_REL_ ESC_MQBW SG_ 236 EBKV_Stangenweg 500;
BA_REL_ "GenSigTimeoutTime" BU_SG_REL_ ESC_MQBW SG_ 236 EBKV_Stangenweg_Fahrerwunsch 500;
BA_REL_ "GenSigTimeoutTime" BU_SG_REL_ ESC_MQBW SG_ 374 EBKV_03_CRC 500;
BA_REL_ "GenSigTimeoutTime" BU_SG_REL_ ESC_MQBW SG_ 374 EBKV_03_BZ 500;
BA_REL_ "GenSigTimeoutTime" BU_SG_REL_ ESC_MQBW SG_ 374 EBKV_Activate_Fallback_ESP 500;
BA_REL_ "GenSigTimeoutTime" BU_SG_REL_ ESC_MQBW SG_ 374 EBKV_Restdruckabsenkung 500;
BA_REL_ "GenSigTimeoutTime" BU_SG_REL_ ESC_MQBW SG_ 374 EBKV_Status_02 500;
BA_REL_ "GenSigTimeoutTime" BU_SG_REL_ ESC_MQBW SG_ 374 EBKV_Diagnose 500;
BA_REL_ "GenSigTimeoutTime" BU_SG_REL_ ESC_MQBW SG_ 374 EBKV_Fahrer_bremst 500;
BA_REL_ "GenSigTimeoutTime" BU_SG_REL_ ESC_MQBW SG_ 374 EBKV_QBit_Fahrer_bremst 500;
BA_REL_ "GenSigTimeoutTime" BU_SG_REL_ ESC_MQBW SG_ 374 EBKV_Fahrer_bremst_deutlich 500;
BA_REL_ "GenSigTimeoutTime" BU_SG_REL_ ESC_MQBW SG_ 374 EBKV_OBD_Status 500;
BA_REL_ "GenSigTimeoutTime" BU_SG_REL_ ESC_MQBW SG_ 374 EBKV_VMM_Sek_Notstopp_Status 500;
BA_REL_ "GenSigTimeoutTime" BU_SG_REL_ ESC_MQBW SG_ 374 EBKV_Anforderung_HMS 500;
BA_REL_ "GenSigTimeoutTime" BU_SG_REL_ ESC_MQBW SG_ 374 EBKV_Bremspedalweg 500;
BA_REL_ "GenSigTimeoutTime" BU_SG_REL_ ESC_MQBW SG_ 374 EBKV_Kraftblending_Reserve 500;
BA_REL_ "GenSigTimeoutTime" BU_SG_REL_ ESC_MQBW SG_ 374 EBKV_Aussteuerdruck 500;
BA_REL_ "GenSigTimeoutTime" BU_SG_REL_ Gateway_Max SG_ 903 EBKV_SpannungsAnf 1000;
BA_REL_ "GenSigTimeoutTime" BU_SG_REL_ Gateway_Max SG_ 374 EBKV_Fahrer_bremst 500;
BA_REL_ "GenSigTimeoutTime" BU_SG_REL_ Gateway_Max SG_ 374 EBKV_QBit_Fahrer_bremst 500;
BA_REL_ "GenSigTimeoutTime" BU_SG_REL_ Gateway_Max SG_ 374 EBKV_Bremspedalweg 500;
BA_REL_ "GenSigTimeoutTime" BU_SG_REL_ Gateway_Max SG_ 503 EPB_03_CRC 2000;
BA_REL_ "GenSigTimeoutTime" BU_SG_REL_ Gateway_Max SG_ 503 EPB_03_BZ 2000;
BA_REL_ "GenSigTimeoutTime" BU_SG_REL_ Gateway_Max SG_ 503 EPB_Funktionslampe_02 2000;
BA_REL_ "GenSigTimeoutTime" BU_SG_REL_ Gateway_Max SG_ 503 EPB_Parkanzeige 2000;
BA_REL_ "GenSigTimeoutTime" BU_SG_REL_ Lenkhilfe_REPS SG_ 2463978646 CHA_Ziel_FahrPr_EPS 5000;
BA_REL_ "GenSigTimeoutTime" BU_SG_REL_ Lenkhilfe_REPS SG_ 1714 KBI_Kilometerstand 5000;
BA_REL_ "GenSigTimeoutTime" BU_SG_REL_ Lenkhilfe_REPS SG_ 1714 UH_Jahr 5000;
BA_REL_ "GenSigTimeoutTime" BU_SG_REL_ Lenkhilfe_REPS SG_ 1714 UH_Monat 5000;
BA_REL_ "GenSigTimeoutTime" BU_SG_REL_ Lenkhilfe_REPS SG_ 1714 UH_Tag 5000;
BA_REL_ "GenSigTimeoutTime" BU_SG_REL_ Lenkhilfe_REPS SG_ 1714 UH_Stunde 5000;
BA_REL_ "GenSigTimeoutTime" BU_SG_REL_ Lenkhilfe_REPS SG_ 1714 UH_Minute 5000;
BA_REL_ "GenSigTimeoutTime" BU_SG_REL_ Lenkhilfe_REPS SG_ 1714 UH_Sekunde 5000;
BA_REL_ "GenSigTimeoutTime" BU_SG_REL_ Lenkhilfe_REPS SG_ 1714 Vehicle_Driving_Cycle 5000;
BA_REL_ "GenSigTimeoutTime" BU_SG_REL_ Lenkhilfe_REPS SG_ 331 DSR_QFK_AnfStat 5000;
BA_REL_ "GenSigTimeoutTime" BU_SG_REL_ Lenkhilfe_REPS SG_ 331 DSR_QFK_Spuerb 5000;
BA_REL_ "GenSigTimeoutTime" BU_SG_REL_ Lenkhilfe_REPS SG_ 331 DSR_QFK_KruemmSoll 5000;
BA_REL_ "GenSigTimeoutTime" BU_SG_REL_ Lenkhilfe_REPS SG_ 331 DSR_QFK_KruemmSoll_VZ 5000;
BA_REL_ "GenSigTimeoutTime" BU_SG_REL_ Lenkhilfe_REPS SG_ 331 DSR_QFK_Signal1 5000;
BA_REL_ "GenSigTimeoutTime" BU_SG_REL_ Lenkhilfe_REPS SG_ 331 DSR_QFK_Art1 5000;
BA_REL_ "GenSigTimeoutTime" BU_SG_REL_ Lenkhilfe_REPS SG_ 331 DSR_QFK_Art2 5000;
BA_REL_ "GenSigTimeoutTime" BU_SG_REL_ Lenkhilfe_REPS SG_ 331 DSR_QFK_Signal2 5000;
BA_REL_ "GenSigTimeoutTime" BU_SG_REL_ Lenkhilfe_REPS SG_ 331 DSR_01_Sendestatus 5000;
BA_REL_ "GenSigTimeoutTime" BU_SG_REL_ Lenkhilfe_REPS SG_ 331 DSR_QFK_KrSoll_VZ 5000;
BA_REL_ "GenSigTimeoutTime" BU_SG_REL_ Lenkhilfe_REPS SG_ 331 DSR_QFK_KrSoll 5000;
VAL_ 870 BM_ZV_auf 0 "inaktiv" 1 "aktiv" ;
VAL_ 870 BM_ZV_zu 0 "inaktiv" 1 "aktiv" ;
VAL_ 870 BM_DWA_ein 0 "inaktiv" 1 "aktiv" ;
VAL_ 870 BM_DWA_Alarm 0 "inaktiv" 1 "aktiv" ;
VAL_ 870 BM_Crash 0 "inaktiv" 1 "aktiv" ;
VAL_ 870 BM_Panik 0 "inaktiv" 1 "aktiv" ;
VAL_ 870 BM_Not_Bremsung 0 "kein_blinken" 1 "Notbremswarnblinken_aktiv" ;
VAL_ 870 BM_GDO 0 "inaktiv" 1 "aktiv" ;
VAL_ 870 BM_Warnblinken 0 "inaktiv" 1 "aktiv" ;
VAL_ 870 BM_Taxi_Notalarm 0 "inaktiv" 1 "aktiv" ;
VAL_ 870 BM_Telematik 0 "inaktiv" 1 "aktiv" ;
VAL_ 870 BM_links 0 "inaktiv" 1 "aktiv" ;
VAL_ 870 BM_rechts 0 "inaktiv" 1 "aktiv" ;
VAL_ 870 Blinken_li_Fzg_Takt 0 "Blinker_links_ausgeschaltet" 1 "Blinker_links_eingeschaltet" ;
VAL_ 870 Blinken_re_Fzg_Takt 0 "Blinker_rechts_ausgeschaltet" 1 "Blinker_rechts_eingeschaltet" ;
VAL_ 870 Blinken_li_Kombi_Takt 0 "Blinkerkontrolllampe_links_ausgeschaltet" 1 "Blinkerkontrolllampe_links_eingeschaltet" ;
VAL_ 870 Blinken_re_Kombi_Takt 0 "Blinkerkontrolllampe_rechts_ausgeschaltet" 1 "Blinkerkontrolllampe_rechts_eingeschaltet" ;
VAL_ 870 BM_NBA_n_codiert_n_aktiv 0 "codiert_AND_kein_Fehler" 1 "nicht_codiert_OR_Fehler_erkannt" ;
VAL_ 870 BM_NBA_Status 0 "NBA_nicht_aktiv" 1 "BRL_Dunkelphase" 3 "BRL_Hellphase" ;
VAL_ 870 BM_WBT_Beleuchtung 0 "inaktiv" 1 "aktiv" ;
VAL_ 870 BM_HD_Oeffnung_angelernt 0 "keine_Quittierung" 1 "Quittierung" ;
VAL_ 870 BM_Autobahn 0 "inaktiv" 1 "aktiv" ;
VAL_ 870 BM_Rollenmodus_Blinken 0 "inaktiv" 1 "aktiv" ;
VAL_ 870 BM_Recas 0 "kein_blinken" 1 "Recasblinken_aktiv" ;
VAL_ 870 BM_Wischblinken 0 "inaktiv" 1 "aktiv" ;
VAL_ 870 BM_Telematik_Abbruchgrund 0 "Init" 1 "speed_out_of_range" 2 "defect" 3 "clamp_s_on" 4 "clamp_15_on" 5 "door_open" 6 "engine_hood_open" 7 "trunk_open" 8 "convertible_top_not_locked" 9 "horn_activated_by_user" 10 "Higher_Prioritiy_Function_active" 11 "Central_Lock_status_changed" 12 "Request_Dropped_by_Requester" 13 "Service_Duration_Expired" 14 "not_possible_due_to_coding" 15 "no_reason_or_unknown_timeout" ;
VAL_ 870 BM_PiloPa 0 "PiloPa_Blinkerquittierung_inaktiv" 1 "PiloPa_Blinkerquittierung_aktiv" ;
VAL_ 870 SAL_TA_Blinken_Status 0 "init" 1 "nicht_bereit" 2 "bereit" 3 "aktiv_links" 4 "aktiv_rechts" ;
VAL_ 870 BM_WBA_Warnblinken 0 "WBA_Warnblinken_inaktiv" 1 "WBA_Warnblinken_aktiv" ;
VAL_ 870 SAL_RHP_Blinken_Status 0 "init" 1 "nicht_bereit" 2 "bereit" 3 "aktiv_links" 4 "aktiv_rechts" ;
VAL_ 870 SAL_RHP_Warnblinken 0 "inaktiv" 1 "aktiv" ;
VAL_ 903 EBKV_Hinweise 0 "i_O_System" 1 "Werkstattdiagnose" 2 "Rollenmodes" 3 "Uebernahme_Feststellbremse" ;
VAL_ 903 EBKV_Warnungen 0 "i_O_System" 1 "Ausfall_2nd_Aktuator" 2 "Reduktion_Bremsverstaerkung" 3 "Ausfall_eBKV_ohne_HBV" 4 "Ausfall_Stillstandsmanagement" ;
VAL_ 903 EBKV_BKL_Warnungen 0 "i_O_System" 1 "Lampen_Pruefung" 2 "Ausfall_eBKV_und_HBV" ;
VAL_ 903 EPB_Funktionslampe_ext 0 "Aus" 1 "Ein" ;
VAL_ 903 EPB_Fehlermeldung_ext 0 "keine_Anzeige" 1 "Systemstoerung_Kl15an" 2 "Systemstoerung_Kl15aus" 3 "Parkbremse_betaetigen" 4 "Systemstoerung_Hanghaltefaehigkeit" 5 "Funktionseinschraenkung_Kl15an" 6 "Funktionseinschraenkung_Kl15aus" 7 "HU_Modus_aktiv" 8 "Transportmodus" 9 "Produktionsmodus" 10 "FktEinschr_Taster_defekt" 11 "Funktionseinschraenkung_Hanghalt" ;
VAL_ 903 EBKV_Charisma_FahrPr 0 "keine_Funktion" 1 "Programm_1" 2 "Programm_2" 3 "Programm_3" 4 "Programm_4" 5 "Programm_5" 6 "Programm_6" 7 "Programm_7" 8 "Programm_8" 9 "Programm_9" 10 "Programm_10" 11 "Programm_11" 12 "Programm_12" 13 "Programm_13" 14 "Programm_14" 15 "Programm_15" ;
VAL_ 903 EBKV_Charisma_Status 0 "Init" 1 "verfuegbar" 2 "nicht_verfuegbar" 3 "asynchron_durch_Fahrerwunsch" ;
VAL_ 903 EBKV_SpannungsAnf 0 "keine_Anforderung" 1 "Anforderung_Stufe_1" 2 "Anforderung_Stufe_2" 3 "Anforderung_Stufe_3" ;
VAL_ 2463978646 CHA_Ziel_FahrPr_AGA 0 "keine_Funktion" 1 "Programm_1" 2 "Programm_2" 3 "Programm_3" 4 "Programm_4" 5 "Programm_5" 6 "Programm_6" 7 "Programm_7" 8 "Programm_8" 9 "Programm_9" 10 "Programm_10" 11 "Programm_11" 12 "Programm_12" 13 "Programm_13" 14 "Programm_14" 15 "Programm_15" ;
VAL_ 2463978646 CHA_Ziel_FahrPr_ESP 0 "keine_Funktion" 1 "Programm_1" 2 "Programm_2" 3 "Programm_3" 4 "Programm_4" 5 "Programm_5" 6 "Programm_6" 7 "Programm_7" 8 "Programm_8" 9 "Programm_9" 10 "Programm_10" 11 "Programm_11" 12 "Programm_12" 13 "Programm_13" 14 "Programm_14" 15 "Programm_15" ;
VAL_ 2463978646 CHA_Ziel_FahrPr_Freilauf 0 "keine_Funktion" 1 "Programm_1" 2 "Programm_2" 3 "Programm_3" 4 "Programm_4" 5 "Programm_5" 6 "Programm_6" 7 "Programm_7" 8 "Programm_8" 9 "Programm_9" 10 "Programm_10" 11 "Programm_11" 12 "Programm_12" 13 "Programm_13" 14 "Programm_14" 15 "Programm_15" ;
VAL_ 2463978646 CHA_Fahrer_Umschaltung 0 "keine_oder_automatische_Umschaltung" 1 "manuelle_Umschaltung" ;
VAL_ 2463978646 CHA_Fahrer_Umschaltung_BMA 0 "keine_oder_autom_Umschaltung" 1 "manuelle_Umschaltung" ;
VAL_ 2463978646 CHA_Ziel_FahrPr_MO 0 "keine_Funktion" 1 "Programm_1" 2 "Programm_2" 3 "Programm_3" 4 "Programm_4" 5 "Programm_5" 6 "Programm_6" 7 "Programm_7" 8 "Programm_8" 9 "Programm_9" 10 "Programm_10" 11 "Programm_11" 12 "Programm_12" 13 "Programm_13" 14 "Programm_14" 15 "Programm_15" ;
VAL_ 2463978646 CHA_Ziel_FahrPr_GE 0 "keine_Funktion" 1 "Programm_1" 2 "Programm_2" 3 "Programm_3" 4 "Programm_4" 5 "Programm_5" 6 "Programm_6" 7 "Programm_7" 8 "Programm_8" 9 "Programm_9" 10 "Programm_10" 11 "Programm_11" 12 "Programm_12" 13 "Programm_13" 14 "Programm_14" 15 "Programm_15" ;
VAL_ 2463978646 CHA_Ziel_FahrPr_ALR 0 "keine_Funktion" 1 "Programm_1" 2 "Programm_2" 3 "Programm_3" 4 "Programm_4" 5 "Programm_5" 6 "Programm_6" 7 "Programm_7" 8 "Programm_8" 9 "Programm_9" 10 "Programm_10" 11 "Programm_11" 12 "Programm_12" 13 "Programm_13" 14 "Programm_14" 15 "Programm_15" ;
VAL_ 2463978646 CHA_Ziel_FahrPr_MO_BZS 0 "keine_Funktion" 1 "Programm_1" 2 "Programm_2" 3 "Programm_3" 4 "Programm_4" 5 "Programm_5" 6 "Programm_6" 7 "Programm_7" 8 "Programm_8" 9 "Programm_9" 10 "Programm_10" 11 "Programm_11" 12 "Programm_12" 13 "Programm_13" 14 "Programm_14" 15 "Programm_15" ;
VAL_ 2463978646 CHA_Ziel_FahrPr_DR 0 "keine_Funktion" 1 "Programm_1" 2 "Programm_2" 3 "Programm_3" 4 "Programm_4" 5 "Programm_5" 6 "Programm_6" 7 "Programm_7" 8 "Programm_8" 9 "Programm_9" 10 "Programm_10" 11 "Programm_11" 12 "Programm_12" 13 "Programm_13" 14 "Programm_14" 15 "Programm_15" ;
VAL_ 2463978646 CHA_Ziel_FahrPr_VAQ 0 "keine_Funktion" 1 "Programm_1" 2 "Programm_2" 3 "Programm_3" 4 "Programm_4" 5 "Programm_5" 6 "Programm_6" 7 "Programm_7" 8 "Programm_8" 9 "Programm_9" 10 "Programm_10" 11 "Programm_11" 12 "Programm_12" 13 "Programm_13" 14 "Programm_14" 15 "Programm_15" ;
VAL_ 2463978646 CHA_Ziel_FahrPr_AFS 0 "keine_Funktion" 1 "Programm_1" 2 "Programm_2" 3 "Programm_3" 4 "Programm_4" 5 "Programm_5" 6 "Programm_6" 7 "Programm_7" 8 "Programm_8" 9 "Programm_9" 10 "Programm_10" 11 "Programm_11" 12 "Programm_12" 13 "Programm_13" 14 "Programm_14" 15 "Programm_15" ;
VAL_ 2463978646 CHA_Ziel_FahrPr_PreCrash 0 "keine_Funktion" 1 "Programm_1" 2 "Programm_2" 3 "Programm_3" 4 "Programm_4" 5 "Programm_5" 6 "Programm_6" 7 "Programm_7" 8 "Programm_8" 9 "Programm_9" 10 "Programm_10" 11 "Programm_11" 12 "Programm_12" 13 "Programm_13" 14 "Programm_14" 15 "Programm_15" ;
VAL_ 2463978646 CHA_Ziel_FahrPr_EPS 0 "keine_Funktion" 1 "Programm_1" 2 "Programm_2" 3 "Programm_3" 4 "Programm_4" 5 "Programm_5" 6 "Programm_6" 7 "Programm_7" 8 "Programm_8" 9 "Programm_9" 10 "Programm_10" 11 "Programm_11" 12 "Programm_12" 13 "Programm_13" 14 "Programm_14" 15 "Programm_15" ;
VAL_ 2463978646 CHA_Ziel_FahrPr_ACC 0 "keine_Funktion" 1 "Programm_1" 2 "Programm_2" 3 "Programm_3" 4 "Programm_4" 5 "Programm_5" 6 "Programm_6" 7 "Programm_7" 8 "Programm_8" 9 "Programm_9" 10 "Programm_10" 11 "Programm_11" 12 "Programm_12" 13 "Programm_13" 14 "Programm_14" 15 "Programm_15" ;
VAL_ 2463978646 CHA_Ziel_FahrPr_SAK 0 "keine_Funktion" 1 "Programm_1" 2 "Programm_2" 3 "Programm_3" 4 "Programm_4" 5 "Programm_5" 6 "Programm_6" 7 "Programm_7" 8 "Programm_8" 9 "Programm_9" 10 "Programm_10" 11 "Programm_11" 12 "Programm_12" 13 "Programm_13" 14 "Programm_14" 15 "Programm_15" ;
VAL_ 2463978646 CHA_Ziel_FahrPr_MO_StSt 0 "keine_Funktion" 1 "Programm_1" 2 "Programm_2" 3 "Programm_3" 4 "Programm_4" 5 "Programm_5" 6 "Programm_6" 7 "Programm_7" 8 "Programm_8" 9 "Programm_9" 10 "Programm_10" 11 "Programm_11" 12 "Programm_12" 13 "Programm_13" 14 "Programm_14" 15 "Programm_15" ;
VAL_ 2463978646 CHA_Ziel_FahrPr_EBKV 0 "keine_Funktion" 1 "Programm_1" 2 "Programm_2" 3 "Programm_3" 4 "Programm_4" 5 "Programm_5" 6 "Programm_6" 7 "Programm_7" 8 "Programm_8" 9 "Programm_9" 10 "Programm_10" 11 "Programm_11" 12 "Programm_12" 13 "Programm_13" 14 "Programm_14" 15 "Programm_15" ;
VAL_ 2463978646 CHA_Ziel_FahrPr_IL 0 "keine_Funktion" 1 "Programm_1" 2 "Programm_2" 3 "Programm_3" 4 "Programm_4" 5 "Programm_5" 6 "Programm_6" 7 "Programm_7" 8 "Programm_8" 9 "Programm_9" 10 "Programm_10" 11 "Programm_11" 12 "Programm_12" 13 "Programm_13" 14 "Programm_14" 15 "Programm_15" ;
VAL_ 2463978646 CHA_Current_Mode 0 "keine_Funktion" 1 "Programm_1" 2 "Programm_2" 3 "Programm_3" 4 "Programm_4" 5 "Programm_5" 6 "Programm_6" 7 "Programm_7" 8 "Programm_8" 9 "Programm_9" 10 "Programm_10" 11 "Programm_11" 12 "Programm_12" 13 "Programm_13" 14 "Programm_14" 15 "Programm_15" ;
VAL_ 2463978646 CHA_Ziel_FahrPr_QS 0 "keine_Funktion" 1 "Programm_1" 2 "Programm_2" 3 "Programm_3" 4 "Programm_4" 5 "Programm_5" 6 "Programm_6" 7 "Programm_7" 8 "Programm_8" 9 "Programm_9" 10 "Programm_10" 11 "Programm_11" 12 "Programm_12" 13 "Programm_13" 14 "Programm_14" 15 "Programm_15" ;
VAL_ 2463978646 CHA_Ziel_FahrPr_SCU 0 "keine_Funktion" 1 "Programm_1" 2 "Programm_2" 3 "Programm_3" 4 "Programm_4" 5 "Programm_5" 6 "Programm_6" 7 "Programm_7" 8 "Programm_8" 9 "Programm_9" 10 "Programm_10" 11 "Programm_11" 12 "Programm_12" 13 "Programm_13" 14 "Programm_14" 15 "Programm_15" ;
VAL_ 2463978646 CHA_Ziel_FahrPr_HAL 0 "keine_Funktion" 1 "Programm_1" 2 "Programm_2" 3 "Programm_3" 4 "Programm_4" 5 "Programm_5" 6 "Programm_6" 7 "Programm_7" 8 "Programm_8" 9 "Programm_9" 10 "Programm_10" 11 "Programm_11" 12 "Programm_12" 13 "Programm_13" 14 "Programm_14" 15 "Programm_15" ;
VAL_ 2463978646 CHA_Ziel_FahrPr_NR 0 "keine_Funktion" 1 "Programm_1" 2 "Programm_2" 3 "Programm_3" 4 "Programm_4" 5 "Programm_5" 6 "Programm_6" 7 "Programm_7" 8 "Programm_8" 9 "Programm_9" 10 "Programm_10" 11 "Programm_11" 12 "Programm_12" 13 "Programm_13" 14 "Programm_14" 15 "Programm_15" ;
VAL_ 2463978646 CHA_Ziel_FahrPr_AV 0 "keine_Funktion" 1 "Programm_1" 2 "Programm_2" 3 "Programm_3" 4 "Programm_4" 5 "Programm_5" 6 "Programm_6" 7 "Programm_7" 8 "Programm_8" 9 "Programm_9" 10 "Programm_10" 11 "Programm_11" 12 "Programm_12" 13 "Programm_13" 14 "Programm_14" 15 "Programm_15" ;
VAL_ 2463978646 CHA_Ziel_FahrPr_MXB 0 "keine_Funktion" 1 "Programm_1" 2 "Programm_2" 3 "Programm_3" 4 "Programm_4" 5 "Programm_5" 6 "Programm_6" 7 "Programm_7" 8 "Programm_8" 9 "Programm_9" 10 "Programm_10" 11 "Programm_11" 12 "Programm_12" 13 "Programm_13" 14 "Programm_14" 15 "Programm_15" ;
VAL_ 2463978646 CHA_Ziel_FahrPr_AFR 0 "keine_Funktion" 1 "Programm_1" 2 "Programm_2" 3 "Programm_3" 4 "Programm_4" 5 "Programm_5" 6 "Programm_6" 7 "Programm_7" 8 "Programm_8" 9 "Programm_9" 10 "Programm_10" 11 "Programm_11" 12 "Programm_12" 13 "Programm_13" 14 "Programm_14" 15 "Programm_15" ;
VAL_ 2463978646 CHA_Ziel_FahrPr_HDC 0 "keine_Funktion" 1 "Programm_1" 2 "Programm_2" 3 "Programm_3" 4 "Programm_4" 5 "Programm_5" 6 "Programm_6" 7 "Programm_7" 8 "Programm_8" 9 "Programm_9" 10 "Programm_10" 11 "Programm_11" 12 "Programm_12" 13 "Programm_13" 14 "Programm_14" 15 "Programm_15" ;
VAL_ 2463978646 CHA_Ziel_FahrPr_EAR 0 "keine_Funktion" 1 "Programm_1" 2 "Programm_2" 3 "Programm_3" 4 "Programm_4" 5 "Programm_5" 6 "Programm_6" 7 "Programm_7" 8 "Programm_8" 9 "Programm_9" 10 "Programm_10" 11 "Programm_11" 12 "Programm_12" 13 "Programm_13" 14 "Programm_14" 15 "Programm_15" ;
VAL_ 2463978646 CHA_Ziel_FahrPr_AEB 0 "keine_Funktion" 1 "Programm_1" 2 "Programm_2" 3 "Programm_3" 4 "Programm_4" 5 "Programm_5" 6 "Programm_6" 7 "Programm_7" 8 "Programm_8" 9 "Programm_9" 10 "Programm_10" 11 "Programm_11" 12 "Programm_12" 13 "Programm_13" 14 "Programm_14" 15 "Programm_15" ;
VAL_ 2463978646 CHA_Ziel_FahrPr_FCWO 0 "keine_Funktion" 1 "Programm_1" 2 "Programm_2" 3 "Programm_3" 4 "Programm_4" 5 "Programm_5" 6 "Programm_6" 7 "Programm_7" 8 "Programm_8" 9 "Programm_9" 10 "Programm_10" 11 "Programm_11" 12 "Programm_12" 13 "Programm_13" 14 "Programm_14" 15 "Programm_15" ;
VAL_ 2463978646 CHA_Ziel_FahrPr_FCWP 0 "keine_Funktion" 1 "Programm_1" 2 "Programm_2" 3 "Programm_3" 4 "Programm_4" 5 "Programm_5" 6 "Programm_6" 7 "Programm_7" 8 "Programm_8" 9 "Programm_9" 10 "Programm_10" 11 "Programm_11" 12 "Programm_12" 13 "Programm_13" 14 "Programm_14" 15 "Programm_15" ;
VAL_ 2463978646 CHA_Ziel_FahrPr_eSound 0 "keine_Funktion" 1 "Programm_1" 2 "Programm_2" 3 "Programm_3" 4 "Programm_4" 5 "Programm_5" 6 "Programm_6" 7 "Programm_7" 8 "Programm_8" 9 "Programm_9" 10 "Programm_10" 11 "Programm_11" 12 "Programm_12" 13 "Programm_13" 14 "Programm_14" 15 "Programm_15" ;
VAL_ 2463978646 CHA_Ziel_FahrPr_RHP 0 "keine_Funktion" 1 "Programm_1" 2 "Programm_2" 3 "Programm_3" 4 "Programm_4" 5 "Programm_5" 6 "Programm_6" 7 "Programm_7" 8 "Programm_8" 9 "Programm_9" 10 "Programm_10" 11 "Programm_11" 12 "Programm_12" 13 "Programm_13" 14 "Programm_14" 15 "Programm_15" ;
VAL_ 2463978646 CHA_Ziel_FahrPr_ToS_laengs 0 "keine_Funktion" 1 "Programm_1" 2 "Programm_2" 3 "Programm_3" 4 "Programm_4" 5 "Programm_5" 6 "Programm_6" 7 "Programm_7" 8 "Programm_8" 9 "Programm_9" 10 "Programm_10" 11 "Programm_11" 12 "Programm_12" 13 "Programm_13" 14 "Programm_14" 15 "Programm_15" ;
VAL_ 2463978646 CHA_Ziel_FahrPr_ToS_quer 0 "keine_Funktion" 1 "Programm_1" 2 "Programm_2" 3 "Programm_3" 4 "Programm_4" 5 "Programm_5" 6 "Programm_6" 7 "Programm_7" 8 "Programm_8" 9 "Programm_9" 10 "Programm_10" 11 "Programm_11" 12 "Programm_12" 13 "Programm_13" 14 "Programm_14" 15 "Programm_15" ;
VAL_ 2463978646 CHA_Ziel_FahrPr_mFDR 0 "keine_Funktion" 1 "Programm_1" 2 "Programm_2" 3 "Programm_3" 4 "Programm_4" 5 "Programm_5" 6 "Programm_6" 7 "Programm_7" 8 "Programm_8" 9 "Programm_9" 10 "Programm_10" 11 "Programm_11" 12 "Programm_12" 13 "Programm_13" 14 "Programm_14" 15 "Programm_15" ;
VAL_ 2463978646 CHA_Ziel_FahrPr_Reku_ZwGas 0 "kein_Funktion" 1 "Programm_1" 2 "Programm_2" 3 "Programm_3" 4 "Programm_4" 5 "Programm_5" 6 "Programm_6" 7 "Programm_7" 8 "Programm_8" 9 "Programm_9" 10 "Programm_10" 11 "Programm_11" 12 "Programm_12" 13 "Programm_13" 14 "Programm_14" 15 "Programm_15" ;
VAL_ 2463978646 CHA_Ziel_FahrPr_MO_Freilauf 0 "keine_Funktion" 1 "Programm_1" 2 "Programm_2" 3 "Programm_3" 4 "Programm_4" 5 "Programm_5" 6 "Programm_6" 7 "Programm_7" 8 "Programm_8" 9 "Programm_9" 10 "Programm_10" 11 "Programm_11" 12 "Programm_12" 13 "Programm_13" 14 "Programm_14" 15 "Programm_15" ;
VAL_ 2463978646 CHA_Ziel_FahrPr_BMS 0 "keine_Funktion" 1 "Programm_1" 2 "Programm_2" 3 "Programm_3" 4 "Programm_4" 5 "Programm_5" 6 "Programm_6" 7 "Programm_7" 8 "Programm_8" 9 "Programm_9" 10 "Programm_10" 11 "Programm_11" 12 "Programm_12" 13 "Programm_13" 14 "Programm_14" 15 "Programm_15" ;
VAL_ 2463978646 CHA_Ziel_FahrPr_PDC 0 "keine_Funktion" 1 "Programm_1" 2 "Programm_2" 3 "Programm_3" 4 "Programm_4" 5 "Programm_5" 6 "Programm_6" 7 "Programm_7" 8 "Programm_8" 9 "Programm_9" 10 "Programm_10" 11 "Programm_11" 12 "Programm_12" 13 "Programm_13" 14 "Programm_14" 15 "Programm_15" ;
VAL_ 2463978646 CHA_Ziel_FahrPr_HHC 0 "keine_Funktion" 1 "Programm_1" 2 "Programm_2" 3 "Programm_3" 4 "Programm_4" 5 "Programm_5" 6 "Programm_6" 7 "Programm_7" 8 "Programm_8" 9 "Programm_9" 10 "Programm_10" 11 "Programm_11" 12 "Programm_12" 13 "Programm_13" 14 "Programm_14" 15 "Programm_15" ;
VAL_ 2463978646 CHA_Ziel_FahrPr_EDS 0 "keine_Funktion" 1 "Programm_1" 2 "Programm_2" 3 "Programm_3" 4 "Programm_4" 5 "Programm_5" 6 "Programm_6" 7 "Programm_7" 8 "Programm_8" 9 "Programm_9" 10 "Programm_10" 11 "Programm_11" 12 "Programm_12" 13 "Programm_13" 14 "Programm_14" 15 "Programm_15" ;
VAL_ 2463978646 CHA_Ziel_FahrPr_PACC 0 "keine_Funktion" 1 "Programm_1" 2 "Programm_2" 3 "Programm_3" 4 "Programm_4" 5 "Programm_5" 6 "Programm_6" 7 "Programm_7" 8 "Programm_8" 9 "Programm_9" 10 "Programm_10" 11 "Programm_11" 12 "Programm_12" 13 "Programm_13" 14 "Programm_14" 15 "Programm_15" ;
VAL_ 2463978646 CHA_Ziel_FahrPr_AGK 0 "keine_Funktion" 1 "Programm_1" 2 "Programm_2" 3 "Programm_3" 4 "Programm_4" 5 "Programm_5" 6 "Programm_6" 7 "Programm_7" 8 "Programm_8" 9 "Programm_9" 10 "Programm_10" 11 "Programm_11" 12 "Programm_12" 13 "Programm_13" 14 "Programm_14" 15 "Programm_15" ;
VAL_ 918 DR_Gelbe_Warnlampe 0 "Warnlampe aus" 1 "Warnlampe ein (Aufprüfen)" 2 "Warnlampe an (Warnung)" 3 "reserviert" ;
VAL_ 514 DR_Aufbaubeschleunigung_HR 1021 "Sensor_nicht_verbaut" 1022 "Init" 1023 "Fehler" ;
VAL_ 514 DR_Aufbaubeschleunigung_VR 1021 "Sensor_nicht_verbaut" 1022 "Init" 1023 "Fehler" ;
VAL_ 514 DR_Aufbaubeschleunigung_VL 1021 "Sensor_nicht_verbaut" 1022 "Init" 1023 "Fehler" ;
VAL_ 514 DR_Aufbaubeschleunigung_HL 1021 "Sensor_nicht_verbaut" 1022 "Init" 1023 "Fehler" ;
VAL_ 514 DR_Funktionsstatus 0 "Init" 1 "Funktion_iO" 2 "Fehlerzustand_erkannt" 3 "keine_Inbetriebnahme" ;
VAL_ 514 DR_Drehwinkelsensortausch_VL 0 "Init" ;
VAL_ 514 DR_Drehwinkelsensortausch_VR 0 "Init" ;
VAL_ 514 DR_Drehwinkelsensortausch_HL 0 "Init" ;
VAL_ 514 DR_Drehwinkelsensortausch_HR 0 "Init" ;
VAL_ 514 DR_Drehwinkel_VL 4091 "nicht_verwendet" 4092 "nicht_verwendet" 4093 "Sensor_nicht_verbaut" 4094 "Init" 4095 "Fehler" ;
VAL_ 514 DR_Drehwinkel_VR 4091 "nicht_verwendet" 4092 "nicht_verwendet" 4093 "Sensor_nicht_verbaut" 4094 "Init" 4095 "Fehler" ;
VAL_ 514 DR_Drehwinkel_HL 4091 "nicht_verwendet" 4092 "nicht_verwendet" 4093 "Sensor_nicht_verbaut" 4094 "Init" 4095 "Fehler" ;
VAL_ 514 DR_Drehwinkel_HR 4091 "nicht_verwendet" 4092 "nicht_verwendet" 4093 "Sensor_nicht_verbaut" 4094 "Init" 4095 "Fehler" ;
VAL_ 514 DR_Daempferweg_VL 4092 "Nicht_angelernt" 4093 "Nicht_verbaut" 4094 "Init" 4095 "Fehler" ;
VAL_ 514 DR_Daempferweg_VR 4092 "Nicht_angelernt" 4093 "Nicht_verbaut" 4094 "Init" 4095 "Fehler" ;
VAL_ 514 DR_Daempferweg_HL 4092 "Nicht_angelernt" 4093 "Nicht_verbaut" 4094 "Init" 4095 "Fehler" ;
VAL_ 514 DR_Daempferweg_HR 4092 "Nicht_angelernt" 4093 "Nicht_verbaut" 4094 "Init" 4095 "Fehler" ;
VAL_ 1714 DGN_Verlernzaehler 255 "ungültiger Zählerstand oder kein gültiger Fahrzyklus" ;
VAL_ 1714 KBI_Kilometerstand 1048574 "Init" 1048575 "Fehler" ;
VAL_ 1714 UH_Monat 0 "Init" 14 "Relatives_Datum" 15 "Fehler" ;
VAL_ 1714 UH_Tag 0 "Init" ;
VAL_ 1714 Vehicle_Driving_Cycle 0 "kein_Driving_Cycle_erkannt" 1 "Driving_Cycle_erkannt" ;
VAL_ 1714 Kombi_02_alt 0 "aktuell" 1 "veraltet" ;
VAL_ 1714 Uhrzeit_01_alt 0 "aktuell" 1 "veraltet" ;
VAL_ 1520 DI_KL_58xd 254 "Init" 255 "Fehler" ;
VAL_ 1520 DI_KL_58xs 126 "Init" 127 "Fehler" ;
VAL_ 1520 DI_KL_58xt 126 "Init" 127 "Fehler" ;
VAL_ 1520 BCM1_Stellgroesse_Kl_58s 125 "Nicht_verbaut" 126 "Init" 127 "Fehler" ;
VAL_ 331 DSR_QFK_AnfStat 1 "Init" 2 "Bereit" 4 "Eingriff" ;
VAL_ 331 DSR_QFK_KruemmSoll_VZ 0 "positiv" 1 "negativ" ;
VAL_ 331 DSR_01_Sendestatus 0 "langsamer_Zyklus" 1 "schneller_Zyklus" ;
VAL_ 331 DSR_QFK_KrSoll_VZ 0 "positiv" 1 "negativ" ;
VAL_ 420 EA_Parken_beibehalten_HMS 0 "Parken_nicht_beibehalten" 1 "Parken_beibehalten" 2 "Init" 3 "Fehler" ;
VAL_ 420 EA_Ruckstaerke 0 "Keine_Anforderung" 1 "Schwach" 2 "Mittel" 3 "Stark" ;
VAL_ 420 EA_Warnruckprofil 0 "keine_Ruckanforderung" 1 "Profil_1" 2 "Profil_2" 3 "Profil_3" 4 "Profil_4" 5 "Profil_5" 6 "Profil_6" 7 "Profil_7" ;
VAL_ 420 EA_PreCrash_Anf 0 "keine_Anforderung" 1 "Aktionsgenerierte_Warnung_1" 2 "Aktionsgenerierte_Warnung_2" 3 "Aktionsgenerierte_Warnung_3" 4 "Aktionsgenerierte_Warnung_4" 5 "Aktionsgenerierte_Warnung_5" 6 "Aktionsgenerierte_Warnung_6" 7 "Aktionsgenerierte_Warnung_7" ;
VAL_ 420 EA_aktiv_laengs 0 "nicht_aktiv" 1 "aktiv_Vorstufe" 2 "aktiv_Hauptstufe" ;
VAL_ 420 EA_Funktionsstatus 0 "EA_INIT" 1 "EA_OFF" 2 "EA_STANDBY" 3 "EA_PHASE0_AKTIV" 4 "EA_PHASE1_AKTIV" 5 "EA_PHASE2_AKTIV" 6 "EA_PHASE3_AKTIV" 7 "EA_REVERSIBLER_FEHLER" 8 "EA_IRREVERSIBLER_FEHLER" ;
VAL_ 420 EA_Gurtstraffer_Anf 0 "Keine_Anforderung" 1 "Haptik_1" 2 "Haptik_2" 3 "Haptik_3" ;
VAL_ 420 EA_Anf_Prefill 0 "Prefill_nicht_aktivieren" 1 "Prefill_aktivieren" ;
VAL_ 420 EA_Anforderung_HMS 0 "keine_Anforderung" 1 "halten" 2 "parken" 3 "halten_Standby" 4 "anfahren" 5 "Loesen_ueber_Rampe" 6 "Parken_mit_P" ;
VAL_ 420 EA_Ruckfreigabe 0 "keine_Freigabe" 1 "Freigabe" ;
VAL_ 420 EA_01_Sendestatus 0 "EA_01_im_langsamen_Zyklus" 1 "EA_01_im_schnellen_Zyklus" ;
VAL_ 420 EA_Sollbeschleunigung 2046 "Neutralwert" 2047 "Fehler" ;
VAL_ 496 EA_Texte 0 "keine_Anzeige" 1 "Nothalteassistent_fehlende_Fahreraktivitaet" 2 "Nothalteassistent_aktiv_Fahrzeugfuehrung_uebernehmen" 3 "Nothalteassistent_automatischer_Nothalt_wird_durchgefuehrt" 4 "Nothalteassistent_automatischer_Nothalt_durchgefuehrt" 5 "Nothalteassistent_Verbindung_zum_Notruf_wird_aufgebaut" 6 "Nothalteassistent_deaktiviert" 7 "Nothalteassistent_Eingriff_abgebrochen" 8 "Nothalteassistent_fehlende_Fahreraktivitaet_2" 9 "Sekundenschlaf_erkannt" 10 "LaneAssist_Lenkung_uebernehmen" 11 "ACA_Fahrzeugfuehrung_uebernehmen" 12 "EA_Fahr_Standstreifenwechsel" 14 "Nothalteassistent_nicht_verfuegbar_reversibel" 15 "Nothalteassistent_Stoerung_irreversibel" ;
VAL_ 496 ACF_Lampe_Hands_Off 0 "keine_Anzeige" 1 "Hands_Off_erkannt" ;
VAL_ 496 EA_Fahrzeughupe_Anf 0 "keine_Anforderung" 1 "Anforderung_Fahrzeughupe" ;
VAL_ 496 EA_eCall_Anf 0 "Keine_Anforderung" 1 "Ausloesen_eCall" ;
VAL_ 496 EA_Infotainment_Anf 0 "Init" 1 "Keine_Absenkung" 2 "Absenkung" 3 "Mute" ;
VAL_ 496 EA_Tueren_Anf 0 "Keine_Anforderung" 1 "Tueren_entriegeln" ;
VAL_ 496 EA_Innenraumlicht_Anf 0 "Innenraumbeleuchtung_ausschalten" 1 "Innenraumbeleuchtung_einschalten" ;
VAL_ 496 zFAS_Warnblinken 0 "Aus" 1 "Statisch" 2 "Taster" 3 "Statisch_ohne_WBT" ;
VAL_ 496 STP_Primaeranz 0 "keine_Anzeige" 1 "Verfuegbar" 2 "Aktiv" 3 "Uebernahme" 4 "Aktiv_Warnung" 5 "Nicht_Verfuegbar" ;
VAL_ 496 EA_Bremslichtblinken 0 "kein_Blinken" 1 "Anforderung_Bremslichtblinken" ;
VAL_ 496 EA_Blinken 0 "Kein_Blinken" 1 "Wechselblinken_links" 2 "Wechselblinken_rechts" 3 "Warnblinken" 4 "Warnblinken_Taster" 5 "Richtungsblinken_links" 6 "Richtungsblinken_rechts" ;
VAL_ 496 EA_Status_HMI 0 "Keine_Anzeige" 1 "Aktiv_quer_laengs" 2 "Aktiv_laengs" ;
VAL_ 496 EA_Warnlevel 0 "keine_Gefaehrdung" 63 "max_Gefaehrdung" ;
VAL_ 236 EBKV_extBr_Status 0 "Init" 1 "verfuegbar" 2 "nicht_verfuegbar" 3 "aktiv" 4 "Aktiv_mit_Einschraenkung" ;
VAL_ 236 EBKV_AktBr_aktiv 0 "Fahrer_aktiv" 1 "eBKV_aktiv" ;
VAL_ 236 EBKV_extBr_Druck_Max 254 "Init" 255 "Fehler" ;
VAL_ 236 EBKV_aktBr_Volumenstrom_Ist 65534 "Init" 65535 "Fehler" ;
VAL_ 236 EBKV_Stangenweg 4094 "Init" 4095 "Fehler" ;
VAL_ 236 EBKV_Stangenweg_Fahrerwunsch 4094 "Init" 4095 "Fehler" ;
VAL_ 374 EBKV_Activate_Fallback_ESP 0 "Rueckfallebene_nicht_aktiv" 1 "Rueckfallebene_aktiv" ;
VAL_ 374 EBKV_Restdruckabsenkung 0 "RPR_Passive" 1 "RPR_Preload" 2 "RPR_Hold" 3 "RPR_Suction" 4 "RPR_HoldLowPressure" 5 "RPR_Abort" ;
VAL_ 374 EBKV_Status_02 0 "EBKV_nicht_initialisiert" 1 "EBKV_Fehler_Zustand_aus" 2 "EBKV_Diagnose" 3 "EBKV_nicht_belegt" 4 "EBKV_Standalone" 5 "EBKV_degradiert" 6 "EBKV_Nachlauf_degradiert" 7 "EBKV_bereit" 8 "EBKV_Ausfall_Rekukomponente" 9 "EBKV_Shutdown" 10 "EBKV_nicht_belegt" 11 "EBKV_nicht_belegt" 12 "EBKV_nicht_belegt" 13 "EBKV_nicht_belegt" 14 "EBKV_nicht_belegt" 15 "EBKV_nicht_belegt" ;
VAL_ 374 EBKV_Diagnose 0 "Diagnose_inaktiv" 1 "Diagnose_aktiv" ;
VAL_ 374 EBKV_Fahrer_bremst 0 "Fahrer_bremst_nicht_selbst" 1 "Fahrer_will_selbst_bremsen" ;
VAL_ 374 EBKV_QBit_Fahrer_bremst 0 "gueltiger_Wert" 1 "Ersatz_Init_oder_Fehlerwert" ;
VAL_ 374 EBKV_Fahrer_bremst_deutlich 0 "Fahrer_uebertritt_Schwelle_nicht" 1 "Fahrer_uebertritt_Schwelle" ;
VAL_ 374 EBKV_OBD_Status 0 "MIL_aus" 1 "MIL_ein" ;
VAL_ 374 EBKV_VMM_Sek_Notstopp_Status 0 "Init" 1 "Verfuegbar" 2 "Passiv_Ueberwachung" 3 "Aktiv_Ausgeloest" 4 "Systemkomponente_Defekt" ;
VAL_ 374 EBKV_Anforderung_HMS 0 "keine_Anforderung" 1 "halten" 2 "parken" 3 "halten_Standby" 4 "anfahren" 5 "Loesen_ueber_Rampe" 7 "HMS_uebernehmen" ;
VAL_ 374 SBS_Anforderung_GE 0 "keine_Anforderung" 1 "P_einlegen" ;
VAL_ 374 EPB_Status_ext 0 "offen" 1 "geschlossen_Parken" 2 "teilgespannt_Halten" 3 "im_Lauf_oeffnen" 4 "im_Lauf_schliessen" 5 "tbd" 6 "Init" 7 "unbekannt" ;
VAL_ 374 EBKV_Textanzeigen 0 "keine_Anzeige" 1 "nicht_gegen_verrollen_gesichert" 2 "Reduktion_Bremskraftverstaerkung" 3 "nicht_belegt" ;
VAL_ 374 EBKV_Bremspedalweg 0 "Init" 255 "Fehler" ;
VAL_ 374 EBKV_Kraftblending_Reserve 254 "Init" 255 "Fehler" ;
VAL_ 374 EBKV_Aussteuerdruck 251 "Aussteuerdruck_VKM_Start" 252 "Aussteuerdruck_Nachlauf_Phase1" 253 "Aussteuerdruck_Nachlauf_Phase2" 254 "Init" 255 "Fehler" ;
VAL_ 2589283963 EBKV_OBD_Status_Auth 0 "MIL_aus" 1 "MIL_ein" ;
VAL_ 2589283963 EBKV_Indc_StChk 0 "Completed" 1 "NotCompleted" ;
VAL_ 2589283963 EBKV_Indc_StFail 0 "passiv" 1 "aktiv" ;
VAL_ 2589283963 OBDProtocol_EBKV 0 "OBDonUDS" 1 "OBDclassic" 16 "NoOBD" 254 "Init" 255 "Fehler" ;
VAL_ 193 EM2_Istmodus 0 "Standby" 1 "Momentenreg" 2 "Int_Drehzahlreg" 3 "Spannungsreg" 4 "Ext_Drehzahlreg" 5 "Inverter_Fehler" 6 "Kalibrierung" 7 "Sonderbremsbetrieb" 8 "Freilauf" 9 "Autonome_Synchronisation" 15 "Initialisierung" ;
VAL_ 193 EM2_IstMoment 4094 "Init" 4095 "Fehler" ;
VAL_ 193 EM2_Moment_AR_Eingriff 4094 "Init" 4095 "Fehler" ;
VAL_ 193 EM2_IstDrehzahl 32766 "Init" 32767 "Fehler" ;
VAL_ 193 EM2_AR_aktiv 0 "Init" 1 "Ruckeldaempfer_aktiv" ;
VAL_ 193 EM2_IstSpannung 4094 "Init" 4095 "Fehler" ;
VAL_ 193 EM2_Strom_HV 4094 "Init" 4095 "Fehler" ;
VAL_ 193 EM2_Max_Moment 2046 "Init" 2047 "Fehler" ;
VAL_ 193 EM2_ErwGrenzen_aktiv 0 "kein_extended_Range" 1 "extended_Range" ;
VAL_ 193 EM2_Min_Moment 2046 "Init" 2047 "Fehler" ;
VAL_ 193 EM2_Fehler_ElAntriebAbschaltung 0 "Init" 1 "Abschaltung" ;
VAL_ 193 EM2_Max_Moment_Lim 2046 "Init" 2047 "Fehler" ;
VAL_ 193 EM2_Fehler_Notabschaltung 0 "kein_Fehler" 1 "Fehler" ;
VAL_ 193 EM2_Min_Moment_Lim 2046 "Init" 2047 "Fehler" ;
VAL_ 193 EM2_Status_DrzEingriff 0 "kein_Eingriff" 1 "Eingriff_Max_Drehzahlregler" 2 "Eingriff_Min_Drehzahlregler" 3 "Fehler" ;
VAL_ 193 EM2_Mom_DrzEingriff 2046 "Init" 2047 "Fehler" ;
VAL_ 193 EM2_Raddrehzahl_links 8188 "reserviert" 8189 "reserviert" 8190 "Init" 8191 "Fehler" ;
VAL_ 193 EM2_Raddrehzahl_rechts 8188 "reserviert" 8189 "reserviert" 8190 "Init" 8191 "Fehler" ;
VAL_ 193 EM2_Max_Moment_Gesamt 2046 "Init" 2047 "Fehler" ;
VAL_ 193 EM2_Min_Moment_Gesamt 2046 "Init" 2047 "Fehler" ;
VAL_ 193 CluAxs_Avl 0 "Init" 1 "verfuegbar" 2 "Fehler" ;
VAL_ 193 CluAxs_State 0 "Init" 1 "offen" 2 "geschlossen" 3 "im_Uebergang" ;
VAL_ 503 EPB_Texte_02 0 "keine_Anzeige" 1 "Neigungswinkel_zu_gross" 2 "Parkbremse_von_Hand_oeffnen" 3 "HU_Modus_oder_EPB_in_Diagnose" 4 "Bremspedal_betaetigen" 5 "EPB_durch_Fahrstufe_loesen" 6 "tbd" 7 "Stoerung_Anfahrassistent" 8 "Motor_starten" 9 "Feststellbremse_nicht_automatisch_geschlossen" 10 "Parkbremse_loesen_nicht_moeglich_Ladekabel_gesteckt" 11 "Notbremsung_ueber_EPB_Taster" 12 "Parkbremse_angezogen" 13 "Parkbremse_loesen_nicht_moeglich_ParkPilot_aktiv" ;
VAL_ 503 EPB_Fehlermeldungen_02 0 "keine_Anzeige" 1 "Systemstoerung_Kl15an" 2 "Systemstoerung_Kl15aus" 3 "Parkbremse_betaetigen" 4 "Systemstoerung_Hanghaltefaehigkeit" 5 "Funktionseinschraenkung_Kl15an" 6 "Funktionseinschraenkung_Kl15aus" 7 "HU_Modus_aktiv" 8 "Transportmodus" 9 "Produktionsmodus" 10 "FktEinschr_Taster_defekt" 11 "Funktionseinschraenkung_Hanghalt" ;
VAL_ 503 EPB_Funktionslampe_02 0 "Aus" 1 "Ein" ;
VAL_ 503 EPB_Autoholdlampe_02 0 "Lampe aus (Autohold inaktiv)" 1 "Lampe ein (Autohold aktiv)" ;
VAL_ 503 EPB_Autohold_Standbyanzeige 0 "Lampe aus" 1 "Lampe ein" ;
VAL_ 503 EPB_Parkanzeige 0 "aus" 1 "an" 2 "blinken" 3 "reserviert" ;
VAL_ 2527679687 EPS_ASM_Ereignis 0 "No_Event" 255 "ASM_Trigger" ;
VAL_ 2527679687 EPS_ASM_Zeitstempel_02 255 "INIT" ;
